// *************************************************************************** *
// *                                                                           *
// *                      Mentor Graphics Corporation                          *
// *                          All rights reserved                              *
// *                                                                           *
// *************************************************************************** *
// *                                                                           *
// * Description:         CANDB File                                           *
// * Generated at:        2019-08-28 11:46:03                                  *
// * System:              xMA19024                                             *
// * Variant:             LSPA                                                 *
// * Network:             PropulsionCAN                                        *
// *                                                                           *
// *************************************************************************** *
// *                                                                           *
// *             THIS CONFIGURATION MIGHT CONTAIN SOME ERRORS                  *
// *              IF THE INPUT MODEL WAS NOT PROPERLY FORMED!                  *
// *                    Do Not Use this File directly!                         *
// *                                                                           *
// *************************************************************************** *
VERSION "PropulsionCAN"

NS_ :

BS_:

BU_:  BECM DEM ECM EGSM ESM ETC IEM IGM ISGM MVBM MVCM MVEM OBC SRS TACM TCM VDDM VGM

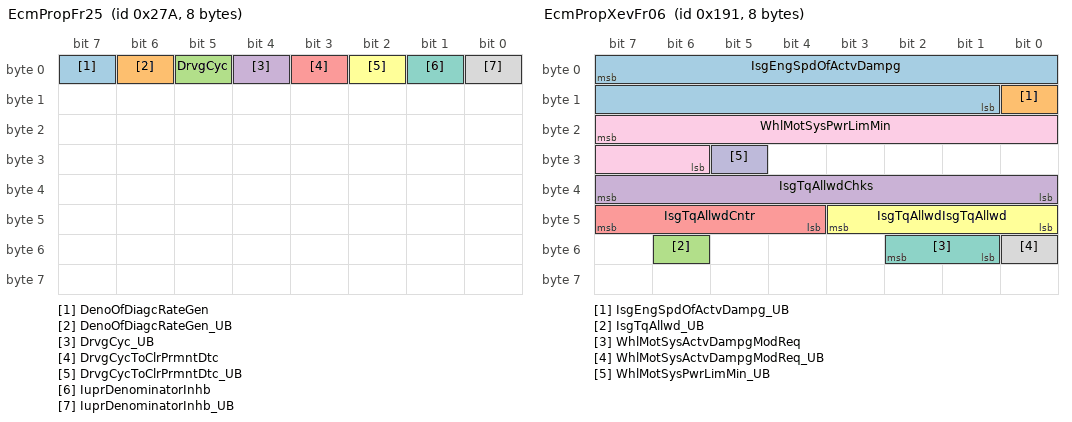
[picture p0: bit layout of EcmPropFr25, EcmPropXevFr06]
BO_ 634 EcmPropFr25: 8 ECM
 SG_ DenoOfDiagcRateGen : 7|1@0+ (1,0) [0|1] "" BECM,IEM,IGM,ISGM,MVBM,OBC
 SG_ DenoOfDiagcRateGen_UB : 6|1@0+ (1,0) [0|1] "" BECM,IEM,IGM,ISGM,MVBM,OBC
 SG_ DrvgCyc : 5|1@0+ (1,0) [0|1] "" BECM,IEM,IGM,ISGM,MVBM,MVCM,OBC,TCM
 SG_ DrvgCyc_UB : 4|1@0+ (1,0) [0|1] "" BECM,IEM,IGM,ISGM,MVBM,MVCM,OBC,TCM
 SG_ DrvgCycToClrPrmntDtc : 3|1@0+ (1,0) [0|1] "" BECM,IEM,IGM,ISGM,MVBM,OBC
 SG_ DrvgCycToClrPrmntDtc_UB : 2|1@0+ (1,0) [0|1] "" BECM,IEM,IGM,ISGM,MVBM,OBC
 SG_ IuprDenominatorInhb : 1|1@0+ (1,0) [0|1] "" BECM,IEM,IGM,ISGM,MVBM,OBC,TCM,VDDM
 SG_ IuprDenominatorInhb_UB : 0|1@0+ (1,0) [0|1] "" BECM,IEM,IGM,ISGM,MVBM,OBC,TCM,VDDM

BO_ 1312 EcmPropNMFr: 8 ECM
 SG_ PNC22_ECM : 22|1@0+ (1,0) [0|0] "" DEM
 SG_ PNC25_ECM : 25|1@0+ (1,0) [0|0] "" DEM
 SG_ PNC26_ECM : 26|1@0+ (1,0) [0|0] "" DEM
 SG_ PNC27_ECM : 27|1@0+ (1,0) [0|0] "" DEM
 SG_ PNC28_ECM : 28|1@0+ (1,0) [0|0] "" DEM
 SG_ PNC29_ECM : 29|1@0+ (1,0) [0|0] "" DEM
 SG_ PNC30_ECM : 30|1@0+ (1,0) [0|0] "" DEM
 SG_ PNC16_ECM : 16|1@0+ (1,0) [0|0] "" DEM
 SG_ PNC24_ECM : 24|1@0+ (1,0) [0|0] "" DEM
 SG_ PNC20_ECM : 20|1@0+ (1,0) [0|0] "" DEM
 SG_ PNC39_ECM : 39|1@0+ (1,0) [0|0] "" DEM
 SG_ PNC35_ECM : 35|1@0+ (1,0) [0|0] "" DEM
 SG_ NM_PNI_ECM : 14|1@0+ (1,0) [0|0] "" DEM
 SG_ NM_AW_ECM : 12|1@0+ (1,0) [0|0] "" DEM
 SG_ NM_CS_ECM : 11|1@0+ (1,0) [0|0] "" DEM
 SG_ NM_RMR_ECM : 8|1@0+ (1,0) [0|0] "" DEM
 SG_ NM_NodeID_ECM : 7|8@0+ (1,0) [0|0] "" DEM

BO_ 1347 EcmPropVFCVectorFr: 8 ECM
 SG_ VFCVectorECMBlockID : 1|2@0+ (1.0,0.0) [0.0|3.0] "Unitless" ETC
 SG_ VFCVectorECMVFCid0 : 2|1@0+ (1,0) [0|1] "" ETC
 SG_ VFCVectorECMVFCid1 : 3|1@0+ (1,0) [0|1] "" ETC
 SG_ VFCVectorECMVFCid10 : 12|1@0+ (1,0) [0|1] "" ETC
 SG_ VFCVectorECMVFCid11 : 13|1@0+ (1,0) [0|1] "" ETC
 SG_ VFCVectorECMVFCid12 : 14|1@0+ (1,0) [0|1] "" ETC
 SG_ VFCVectorECMVFCid13 : 15|1@0+ (1,0) [0|1] "" ETC
 SG_ VFCVectorECMVFCid14 : 16|1@0+ (1,0) [0|1] "" ETC
 SG_ VFCVectorECMVFCid15 : 17|1@0+ (1,0) [0|1] "" ETC
 SG_ VFCVectorECMVFCid16 : 18|1@0+ (1,0) [0|1] "" ETC
 SG_ VFCVectorECMVFCid17 : 19|1@0+ (1,0) [0|1] "" ETC
 SG_ VFCVectorECMVFCid18 : 20|1@0+ (1,0) [0|1] "" ETC
 SG_ VFCVectorECMVFCid19 : 21|1@0+ (1,0) [0|1] "" ETC
 SG_ VFCVectorECMVFCid2 : 4|1@0+ (1,0) [0|1] "" ETC
 SG_ VFCVectorECMVFCid20 : 22|1@0+ (1,0) [0|1] "" ETC
 SG_ VFCVectorECMVFCid21 : 23|1@0+ (1,0) [0|1] "" ETC
 SG_ VFCVectorECMVFCid22 : 24|1@0+ (1,0) [0|1] "" ETC
 SG_ VFCVectorECMVFCid23 : 25|1@0+ (1,0) [0|1] "" ETC
 SG_ VFCVectorECMVFCid24 : 26|1@0+ (1,0) [0|1] "" ETC
 SG_ VFCVectorECMVFCid25 : 27|1@0+ (1,0) [0|1] "" ETC
 SG_ VFCVectorECMVFCid26 : 28|1@0+ (1,0) [0|1] "" ETC
 SG_ VFCVectorECMVFCid27 : 29|1@0+ (1,0) [0|1] "" ETC
 SG_ VFCVectorECMVFCid28 : 30|1@0+ (1,0) [0|1] "" ETC
 SG_ VFCVectorECMVFCid29 : 31|1@0+ (1,0) [0|1] "" ETC
 SG_ VFCVectorECMVFCid3 : 5|1@0+ (1,0) [0|1] "" ETC
 SG_ VFCVectorECMVFCid30 : 32|1@0+ (1,0) [0|1] "" ETC
 SG_ VFCVectorECMVFCid31 : 33|1@0+ (1,0) [0|1] "" ETC
 SG_ VFCVectorECMVFCid32 : 34|1@0+ (1,0) [0|1] "" ETC
 SG_ VFCVectorECMVFCid33 : 35|1@0+ (1,0) [0|1] "" ETC
 SG_ VFCVectorECMVFCid34 : 36|1@0+ (1,0) [0|1] "" ETC
 SG_ VFCVectorECMVFCid35 : 37|1@0+ (1,0) [0|1] "" ETC
 SG_ VFCVectorECMVFCid36 : 38|1@0+ (1,0) [0|1] "" ETC
 SG_ VFCVectorECMVFCid37 : 39|1@0+ (1,0) [0|1] "" ETC
 SG_ VFCVectorECMVFCid38 : 40|1@0+ (1,0) [0|1] "" ETC
 SG_ VFCVectorECMVFCid39 : 41|1@0+ (1,0) [0|1] "" ETC
 SG_ VFCVectorECMVFCid4 : 6|1@0+ (1,0) [0|1] "" ETC
 SG_ VFCVectorECMVFCid40 : 42|1@0+ (1,0) [0|1] "" ETC
 SG_ VFCVectorECMVFCid41 : 43|1@0+ (1,0) [0|1] "" ETC
 SG_ VFCVectorECMVFCid42 : 44|1@0+ (1,0) [0|1] "" ETC
 SG_ VFCVectorECMVFCid43 : 45|1@0+ (1,0) [0|1] "" ETC
 SG_ VFCVectorECMVFCid44 : 46|1@0+ (1,0) [0|1] "" ETC
 SG_ VFCVectorECMVFCid45 : 47|1@0+ (1,0) [0|1] "" ETC
 SG_ VFCVectorECMVFCid46 : 48|1@0+ (1,0) [0|1] "" ETC
 SG_ VFCVectorECMVFCid47 : 49|1@0+ (1,0) [0|1] "" ETC
 SG_ VFCVectorECMVFCid48 : 50|1@0+ (1,0) [0|1] "" ETC
 SG_ VFCVectorECMVFCid49 : 51|1@0+ (1,0) [0|1] "" ETC
 SG_ VFCVectorECMVFCid5 : 7|1@0+ (1,0) [0|1] "" ETC
 SG_ VFCVectorECMVFCid50 : 52|1@0+ (1,0) [0|1] "" ETC
 SG_ VFCVectorECMVFCid51 : 53|1@0+ (1,0) [0|1] "" ETC
 SG_ VFCVectorECMVFCid52 : 54|1@0+ (1,0) [0|1] "" ETC
 SG_ VFCVectorECMVFCid53 : 55|1@0+ (1,0) [0|1] "" ETC
 SG_ VFCVectorECMVFCid54 : 56|1@0+ (1,0) [0|1] "" ETC
 SG_ VFCVectorECMVFCid55 : 57|1@0+ (1,0) [0|1] "" ETC
 SG_ VFCVectorECMVFCid56 : 58|1@0+ (1,0) [0|1] "" ETC
 SG_ VFCVectorECMVFCid57 : 59|1@0+ (1,0) [0|1] "" ETC
 SG_ VFCVectorECMVFCid58 : 60|1@0+ (1,0) [0|1] "" ETC
 SG_ VFCVectorECMVFCid59 : 61|1@0+ (1,0) [0|1] "" ETC
 SG_ VFCVectorECMVFCid6 : 8|1@0+ (1,0) [0|1] "" ETC
 SG_ VFCVectorECMVFCid60 : 62|1@0+ (1,0) [0|1] "" ETC
 SG_ VFCVectorECMVFCid61 : 63|1@0+ (1,0) [0|1] "" ETC
 SG_ VFCVectorECMVFCid7 : 9|1@0+ (1,0) [0|1] "" ETC
 SG_ VFCVectorECMVFCid8 : 10|1@0+ (1,0) [0|1] "" ETC
 SG_ VFCVectorECMVFCid9 : 11|1@0+ (1,0) [0|1] "" ETC

BO_ 401 EcmPropXevFr06: 8 ECM
 SG_ IsgEngSpdOfActvDampg : 7|15@0+ (0.5,0.0) [0.0|16383.5] "rpm" IGM
 SG_ IsgEngSpdOfActvDampg_UB : 8|1@0+ (1,0) [0|1] "" IGM
 SG_ IsgTqAllwd_UB : 54|1@0+ (1,0) [0|1] "" IGM
 SG_ IsgTqAllwdChks : 39|8@0+ (1.0,0.0) [0.0|255.0] "Unitless" IGM
 SG_ IsgTqAllwdCntr : 47|4@0+ (1.0,0.0) [0.0|15.0] "Unitless" IGM
 SG_ IsgTqAllwdIsgTqAllwd : 43|4@0+ (1.0,0.0) [0.0|15.0] "Unitless" IGM
 SG_ WhlMotSysActvDampgModReq : 50|2@0+ (1,0) [0|3] "" IEM
 SG_ WhlMotSysActvDampgModReq_UB : 48|1@0+ (1,0) [0|1] "" IEM
 SG_ WhlMotSysPwrLimMin : 23|10@0+ (0.5,-511.0) [-511.0|0.0] "kW" IEM
 SG_ WhlMotSysPwrLimMin_UB : 29|1@0+ (1,0) [0|1] "" IEM

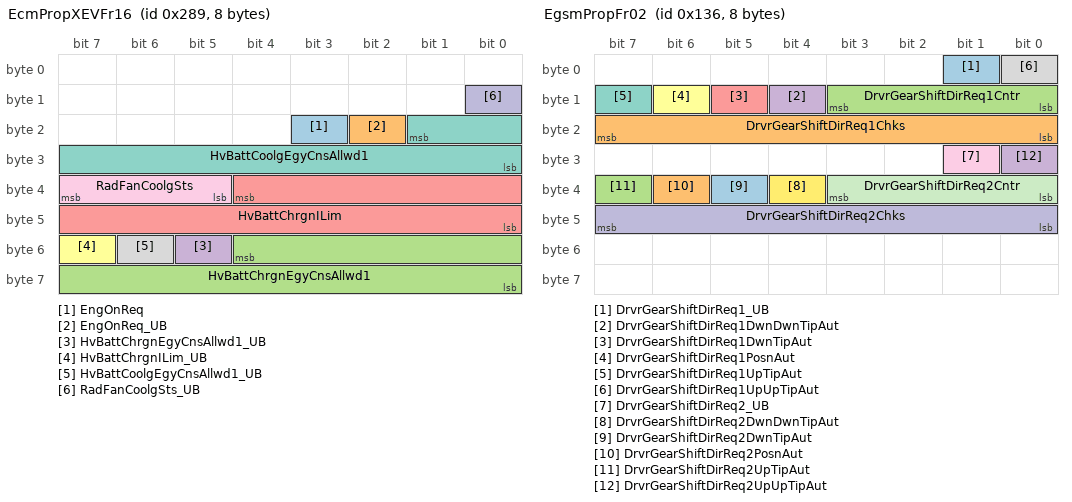
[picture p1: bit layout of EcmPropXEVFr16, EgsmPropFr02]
BO_ 649 EcmPropXEVFr16: 8 ECM
 SG_ EngOnReq : 19|1@0+ (1,0) [0|1] "" BECM
 SG_ EngOnReq_UB : 18|1@0+ (1,0) [0|1] "" BECM
 SG_ HvBattChrgnEgyCnsAllwd1 : 52|13@0+ (20.0,0.0) [0.0|163820.0] "Wh" BECM
 SG_ HvBattChrgnEgyCnsAllwd1_UB : 53|1@0+ (1,0) [0|1] "" BECM
 SG_ HvBattChrgnILim : 36|13@0+ (0.1,0.0) [0.0|819.1] "A" OBC
 SG_ HvBattChrgnILim_UB : 55|1@0+ (1,0) [0|1] "" OBC
 SG_ HvBattCoolgEgyCnsAllwd1 : 17|10@0+ (20.0,0.0) [0.0|20460.0] "Wh" BECM
 SG_ HvBattCoolgEgyCnsAllwd1_UB : 54|1@0+ (1,0) [0|1] "" BECM
 SG_ RadFanCoolgSts : 39|3@0+ (1.0,0.0) [0.0|7.0] "Unitless" BECM
 SG_ RadFanCoolgSts_UB : 8|1@0+ (1,0) [0|1] "" BECM

BO_ 1584 EcmToVddmPropDiagResFrame: 8 ECM
 SG_ EcmToVddmPropDiagResNpdu : 7|64@0+ (1,0) [0|0] "" VDDM

BO_ 2024 EcmToVgmJ1979OBDPropCanResFrame11: 8 ECM
 SG_ EcmToVgmJ1979OBDPropCanResNpdu11 : 7|64@0+ (1,0) [0|0] "" VGM

BO_ 309 EgsmPropFr01: 8 EGSM
 SG_ DrvrGearShiftManReq_UB : 7|1@0+ (1,0) [0|1] "" ECM,TCM
 SG_ DrvrGearShiftManReqDwnDwnTipReq : 0|1@0+ (1,0) [0|1] "" ECM,TCM
 SG_ DrvrGearShiftManReqDwnTipReq : 1|1@0+ (1,0) [0|1] "" ECM,TCM
 SG_ DrvrGearShiftManReqSteerWhlDwnReq1 : 2|1@0+ (1,0) [0|1] "" ECM,TCM
 SG_ DrvrGearShiftManReqSteerWhlUpReq : 3|1@0+ (1,0) [0|1] "" ECM,TCM
 SG_ DrvrGearShiftManReqTipReq1 : 4|1@0+ (1,0) [0|1] "" ECM,TCM
 SG_ DrvrGearShiftManReqUpTipReq1 : 5|1@0+ (1,0) [0|1] "" ECM,TCM
 SG_ DrvrGearShiftManReqUpUpTipReq : 6|1@0+ (1,0) [0|1] "" ECM,TCM
 SG_ DrvrGearShiftParkReq_UB : 15|1@0+ (1,0) [0|1] "" ECM,VDDM
 SG_ DrvrGearShiftParkReq1 : 14|1@0+ (1,0) [0|1] "" ECM,VDDM
 SG_ DrvrGearShiftParkReqChks : 23|8@0+ (1.0,0.0) [0.0|255.0] "Unitless" ECM,VDDM
 SG_ DrvrGearShiftParkReqCntr : 11|4@0+ (1.0,0.0) [0.0|15.0] "Unitless" ECM,VDDM
 SG_ DrvrGearShiftParkReqSts : 13|2@0+ (1,0) [0|3] "" ECM,VDDM
 SG_ GearLock : 28|1@0+ (1,0) [0|1] "" ECM
 SG_ GearLock_UB : 29|1@0+ (1,0) [0|1] "" ECM
 SG_ GearShiftUnitSts : 26|3@0+ (1,0) [0|7] "" ECM,VDDM
 SG_ GearShiftUnitSts_UB : 27|1@0+ (1,0) [0|1] "" ECM,VDDM

BO_ 310 EgsmPropFr02: 8 EGSM
 SG_ DrvrGearShiftDirReq1_UB : 1|1@0+ (1,0) [0|1] "" ECM,VDDM
 SG_ DrvrGearShiftDirReq1Chks : 23|8@0+ (1.0,0.0) [0.0|255.0] "Unitless" ECM,VDDM
 SG_ DrvrGearShiftDirReq1Cntr : 11|4@0+ (1.0,0.0) [0.0|15.0] "Unitless" ECM,VDDM
 SG_ DrvrGearShiftDirReq1DwnDwnTipAut : 12|1@0+ (1,0) [0|1] "" ECM,VDDM
 SG_ DrvrGearShiftDirReq1DwnTipAut : 13|1@0+ (1,0) [0|1] "" ECM,VDDM
 SG_ DrvrGearShiftDirReq1PosnAut : 14|1@0+ (1,0) [0|1] "" ECM,VDDM
 SG_ DrvrGearShiftDirReq1UpTipAut : 15|1@0+ (1,0) [0|1] "" ECM,VDDM
 SG_ DrvrGearShiftDirReq1UpUpTipAut : 0|1@0+ (1,0) [0|1] "" ECM,VDDM
 SG_ DrvrGearShiftDirReq2_UB : 25|1@0+ (1,0) [0|1] "" ECM,VDDM
 SG_ DrvrGearShiftDirReq2Chks : 47|8@0+ (1.0,0.0) [0.0|255.0] "Unitless" ECM,VDDM
 SG_ DrvrGearShiftDirReq2Cntr : 35|4@0+ (1.0,0.0) [0.0|15.0] "Unitless" ECM,VDDM
 SG_ DrvrGearShiftDirReq2DwnDwnTipAut : 36|1@0+ (1,0) [0|1] "" ECM,VDDM
 SG_ DrvrGearShiftDirReq2DwnTipAut : 37|1@0+ (1,0) [0|1] "" ECM,VDDM
 SG_ DrvrGearShiftDirReq2PosnAut : 38|1@0+ (1,0) [0|1] "" ECM,VDDM
 SG_ DrvrGearShiftDirReq2UpTipAut : 39|1@0+ (1,0) [0|1] "" ECM,VDDM
 SG_ DrvrGearShiftDirReq2UpUpTipAut : 24|1@0+ (1,0) [0|1] "" ECM,VDDM

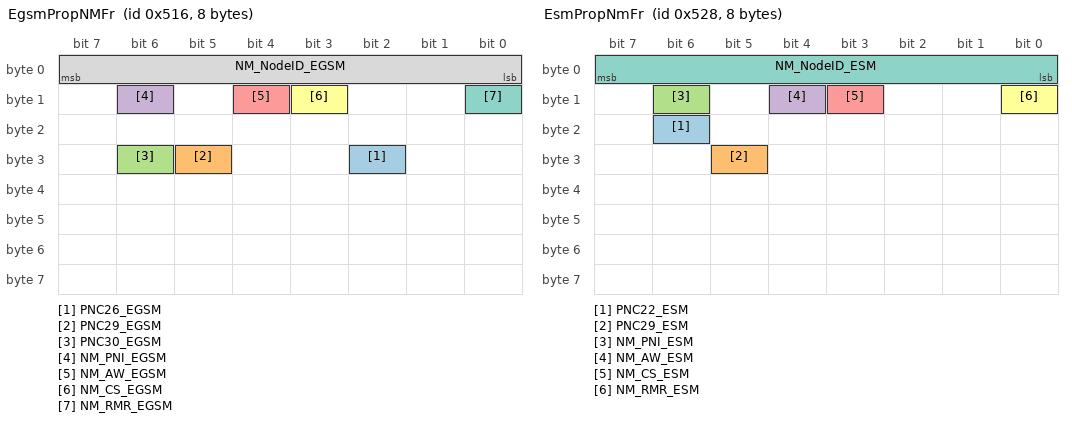
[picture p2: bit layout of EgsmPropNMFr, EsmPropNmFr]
BO_ 1302 EgsmPropNMFr: 8 EGSM
 SG_ PNC26_EGSM : 26|1@0+ (1,0) [0|0] "" ECM
 SG_ PNC29_EGSM : 29|1@0+ (1,0) [0|0] "" ECM
 SG_ PNC30_EGSM : 30|1@0+ (1,0) [0|0] "" ECM
 SG_ NM_PNI_EGSM : 14|1@0+ (1,0) [0|0] "" ECM
 SG_ NM_AW_EGSM : 12|1@0+ (1,0) [0|0] "" ECM
 SG_ NM_CS_EGSM : 11|1@0+ (1,0) [0|0] "" ECM
 SG_ NM_RMR_EGSM : 8|1@0+ (1,0) [0|0] "" ECM
 SG_ NM_NodeID_EGSM : 7|8@0+ (1,0) [0|0] "" ECM

BO_ 1349 EgsmPropVFCVectorFr: 8 EGSM
 SG_ VFCVectorEGSMBlockID : 1|2@0+ (1.0,0.0) [0.0|3.0] "Unitless" ETC
 SG_ VFCVectorEGSMVFCid0 : 2|1@0+ (1,0) [0|1] "" ETC
 SG_ VFCVectorEGSMVFCid1 : 3|1@0+ (1,0) [0|1] "" ETC
 SG_ VFCVectorEGSMVFCid10 : 12|1@0+ (1,0) [0|1] "" ETC
 SG_ VFCVectorEGSMVFCid11 : 13|1@0+ (1,0) [0|1] "" ETC
 SG_ VFCVectorEGSMVFCid12 : 14|1@0+ (1,0) [0|1] "" ETC
 SG_ VFCVectorEGSMVFCid13 : 15|1@0+ (1,0) [0|1] "" ETC
 SG_ VFCVectorEGSMVFCid14 : 16|1@0+ (1,0) [0|1] "" ETC
 SG_ VFCVectorEGSMVFCid15 : 17|1@0+ (1,0) [0|1] "" ETC
 SG_ VFCVectorEGSMVFCid16 : 18|1@0+ (1,0) [0|1] "" ETC
 SG_ VFCVectorEGSMVFCid17 : 19|1@0+ (1,0) [0|1] "" ETC
 SG_ VFCVectorEGSMVFCid18 : 20|1@0+ (1,0) [0|1] "" ETC
 SG_ VFCVectorEGSMVFCid19 : 21|1@0+ (1,0) [0|1] "" ETC
 SG_ VFCVectorEGSMVFCid2 : 4|1@0+ (1,0) [0|1] "" ETC
 SG_ VFCVectorEGSMVFCid20 : 22|1@0+ (1,0) [0|1] "" ETC
 SG_ VFCVectorEGSMVFCid21 : 23|1@0+ (1,0) [0|1] "" ETC
 SG_ VFCVectorEGSMVFCid22 : 24|1@0+ (1,0) [0|1] "" ETC
 SG_ VFCVectorEGSMVFCid23 : 25|1@0+ (1,0) [0|1] "" ETC
 SG_ VFCVectorEGSMVFCid24 : 26|1@0+ (1,0) [0|1] "" ETC
 SG_ VFCVectorEGSMVFCid25 : 27|1@0+ (1,0) [0|1] "" ETC
 SG_ VFCVectorEGSMVFCid26 : 28|1@0+ (1,0) [0|1] "" ETC
 SG_ VFCVectorEGSMVFCid27 : 29|1@0+ (1,0) [0|1] "" ETC
 SG_ VFCVectorEGSMVFCid28 : 30|1@0+ (1,0) [0|1] "" ETC
 SG_ VFCVectorEGSMVFCid29 : 31|1@0+ (1,0) [0|1] "" ETC
 SG_ VFCVectorEGSMVFCid3 : 5|1@0+ (1,0) [0|1] "" ETC
 SG_ VFCVectorEGSMVFCid30 : 32|1@0+ (1,0) [0|1] "" ETC
 SG_ VFCVectorEGSMVFCid31 : 33|1@0+ (1,0) [0|1] "" ETC
 SG_ VFCVectorEGSMVFCid32 : 34|1@0+ (1,0) [0|1] "" ETC
 SG_ VFCVectorEGSMVFCid33 : 35|1@0+ (1,0) [0|1] "" ETC
 SG_ VFCVectorEGSMVFCid34 : 36|1@0+ (1,0) [0|1] "" ETC
 SG_ VFCVectorEGSMVFCid35 : 37|1@0+ (1,0) [0|1] "" ETC
 SG_ VFCVectorEGSMVFCid36 : 38|1@0+ (1,0) [0|1] "" ETC
 SG_ VFCVectorEGSMVFCid37 : 39|1@0+ (1,0) [0|1] "" ETC
 SG_ VFCVectorEGSMVFCid38 : 40|1@0+ (1,0) [0|1] "" ETC
 SG_ VFCVectorEGSMVFCid39 : 41|1@0+ (1,0) [0|1] "" ETC
 SG_ VFCVectorEGSMVFCid4 : 6|1@0+ (1,0) [0|1] "" ETC
 SG_ VFCVectorEGSMVFCid40 : 42|1@0+ (1,0) [0|1] "" ETC
 SG_ VFCVectorEGSMVFCid41 : 43|1@0+ (1,0) [0|1] "" ETC
 SG_ VFCVectorEGSMVFCid42 : 44|1@0+ (1,0) [0|1] "" ETC
 SG_ VFCVectorEGSMVFCid43 : 45|1@0+ (1,0) [0|1] "" ETC
 SG_ VFCVectorEGSMVFCid44 : 46|1@0+ (1,0) [0|1] "" ETC
 SG_ VFCVectorEGSMVFCid45 : 47|1@0+ (1,0) [0|1] "" ETC
 SG_ VFCVectorEGSMVFCid46 : 48|1@0+ (1,0) [0|1] "" ETC
 SG_ VFCVectorEGSMVFCid47 : 49|1@0+ (1,0) [0|1] "" ETC
 SG_ VFCVectorEGSMVFCid48 : 50|1@0+ (1,0) [0|1] "" ETC
 SG_ VFCVectorEGSMVFCid49 : 51|1@0+ (1,0) [0|1] "" ETC
 SG_ VFCVectorEGSMVFCid5 : 7|1@0+ (1,0) [0|1] "" ETC
 SG_ VFCVectorEGSMVFCid50 : 52|1@0+ (1,0) [0|1] "" ETC
 SG_ VFCVectorEGSMVFCid51 : 53|1@0+ (1,0) [0|1] "" ETC
 SG_ VFCVectorEGSMVFCid52 : 54|1@0+ (1,0) [0|1] "" ETC
 SG_ VFCVectorEGSMVFCid53 : 55|1@0+ (1,0) [0|1] "" ETC
 SG_ VFCVectorEGSMVFCid54 : 56|1@0+ (1,0) [0|1] "" ETC
 SG_ VFCVectorEGSMVFCid55 : 57|1@0+ (1,0) [0|1] "" ETC
 SG_ VFCVectorEGSMVFCid56 : 58|1@0+ (1,0) [0|1] "" ETC
 SG_ VFCVectorEGSMVFCid57 : 59|1@0+ (1,0) [0|1] "" ETC
 SG_ VFCVectorEGSMVFCid58 : 60|1@0+ (1,0) [0|1] "" ETC
 SG_ VFCVectorEGSMVFCid59 : 61|1@0+ (1,0) [0|1] "" ETC
 SG_ VFCVectorEGSMVFCid6 : 8|1@0+ (1,0) [0|1] "" ETC
 SG_ VFCVectorEGSMVFCid60 : 62|1@0+ (1,0) [0|1] "" ETC
 SG_ VFCVectorEGSMVFCid61 : 63|1@0+ (1,0) [0|1] "" ETC
 SG_ VFCVectorEGSMVFCid7 : 9|1@0+ (1,0) [0|1] "" ETC
 SG_ VFCVectorEGSMVFCid8 : 10|1@0+ (1,0) [0|1] "" ETC
 SG_ VFCVectorEGSMVFCid9 : 11|1@0+ (1,0) [0|1] "" ETC

BO_ 1587 EgsmToVddmPropDiagResFrame: 8 EGSM
 SG_ EgsmToVddmPropDiagResNpdu : 7|64@0+ (1,0) [0|0] "" VDDM

BO_ 801 EsmPropFr01: 4 ESM
 SG_ ComLostExtrSoundFront : 7|1@0+ (1,0) [0|1] "" VDDM
 SG_ ComLostExtrSoundFront_UB : 15|1@0+ (1,0) [0|1] "" VDDM

BO_ 1320 EsmPropNmFr: 8 ESM
 SG_ PNC22_ESM : 22|1@0+ (1,0) [0|0] "" EGSM
 SG_ PNC29_ESM : 29|1@0+ (1,0) [0|0] "" EGSM
 SG_ NM_PNI_ESM : 14|1@0+ (1,0) [0|0] "" EGSM
 SG_ NM_AW_ESM : 12|1@0+ (1,0) [0|0] "" EGSM
 SG_ NM_CS_ESM : 11|1@0+ (1,0) [0|0] "" EGSM
 SG_ NM_RMR_ESM : 8|1@0+ (1,0) [0|0] "" EGSM
 SG_ NM_NodeID_ESM : 7|8@0+ (1,0) [0|0] "" EGSM

BO_ 1594 EsmToVddmPropDiagResFrame: 8 ESM
 SG_ EsmToVddmPropDiagResNpdu : 7|64@0+ (1,0) [0|0] "" VDDM

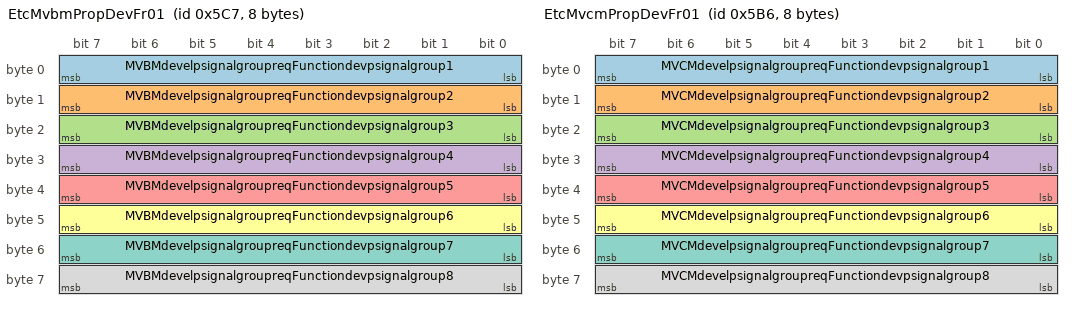
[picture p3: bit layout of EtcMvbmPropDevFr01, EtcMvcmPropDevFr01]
BO_ 1479 EtcMvbmPropDevFr01: 8 ETC
 SG_ MVBMdevelpsignalgroupreqFunctiondevpsignalgroup1 : 7|8@0+ (1.0,0.0) [0.0|255.0] "Unitless" MVBM
 SG_ MVBMdevelpsignalgroupreqFunctiondevpsignalgroup2 : 15|8@0+ (1.0,0.0) [0.0|255.0] "Unitless" MVBM
 SG_ MVBMdevelpsignalgroupreqFunctiondevpsignalgroup3 : 23|8@0+ (1.0,0.0) [0.0|255.0] "Unitless" MVBM
 SG_ MVBMdevelpsignalgroupreqFunctiondevpsignalgroup4 : 31|8@0+ (1.0,0.0) [0.0|255.0] "Unitless" MVBM
 SG_ MVBMdevelpsignalgroupreqFunctiondevpsignalgroup5 : 39|8@0+ (1.0,0.0) [0.0|255.0] "Unitless" MVBM
 SG_ MVBMdevelpsignalgroupreqFunctiondevpsignalgroup6 : 47|8@0+ (1.0,0.0) [0.0|255.0] "Unitless" MVBM
 SG_ MVBMdevelpsignalgroupreqFunctiondevpsignalgroup7 : 55|8@0+ (1.0,0.0) [0.0|255.0] "Unitless" MVBM
 SG_ MVBMdevelpsignalgroupreqFunctiondevpsignalgroup8 : 63|8@0+ (1.0,0.0) [0.0|255.0] "Unitless" MVBM

BO_ 1462 EtcMvcmPropDevFr01: 8 ETC
 SG_ MVCMdevelpsignalgroupreqFunctiondevpsignalgroup1 : 7|8@0+ (1.0,0.0) [0.0|255.0] "Unitless" MVCM
 SG_ MVCMdevelpsignalgroupreqFunctiondevpsignalgroup2 : 15|8@0+ (1.0,0.0) [0.0|255.0] "Unitless" MVCM
 SG_ MVCMdevelpsignalgroupreqFunctiondevpsignalgroup3 : 23|8@0+ (1.0,0.0) [0.0|255.0] "Unitless" MVCM
 SG_ MVCMdevelpsignalgroupreqFunctiondevpsignalgroup4 : 31|8@0+ (1.0,0.0) [0.0|255.0] "Unitless" MVCM
 SG_ MVCMdevelpsignalgroupreqFunctiondevpsignalgroup5 : 39|8@0+ (1.0,0.0) [0.0|255.0] "Unitless" MVCM
 SG_ MVCMdevelpsignalgroupreqFunctiondevpsignalgroup6 : 47|8@0+ (1.0,0.0) [0.0|255.0] "Unitless" MVCM
 SG_ MVCMdevelpsignalgroupreqFunctiondevpsignalgroup7 : 55|8@0+ (1.0,0.0) [0.0|255.0] "Unitless" MVCM
 SG_ MVCMdevelpsignalgroupreqFunctiondevpsignalgroup8 : 63|8@0+ (1.0,0.0) [0.0|255.0] "Unitless" MVCM

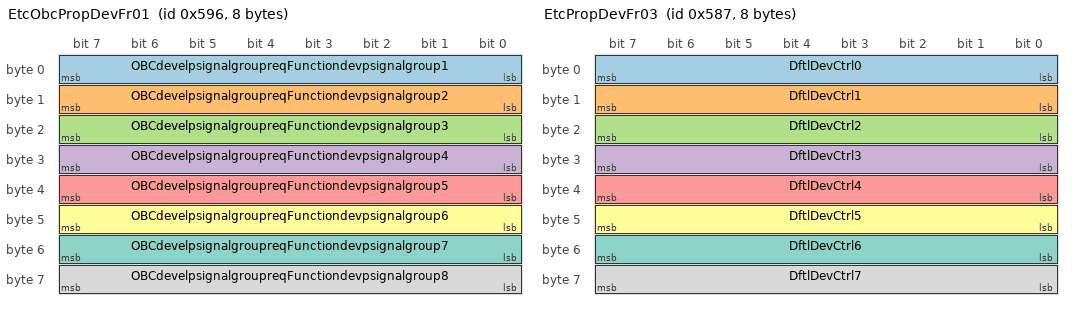
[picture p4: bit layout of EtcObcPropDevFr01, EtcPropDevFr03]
BO_ 1430 EtcObcPropDevFr01: 8 ETC
 SG_ OBCdevelpsignalgroupreqFunctiondevpsignalgroup1 : 7|8@0+ (1.0,0.0) [0.0|255.0] "Unitless" OBC
 SG_ OBCdevelpsignalgroupreqFunctiondevpsignalgroup2 : 15|8@0+ (1.0,0.0) [0.0|255.0] "Unitless" OBC
 SG_ OBCdevelpsignalgroupreqFunctiondevpsignalgroup3 : 23|8@0+ (1.0,0.0) [0.0|255.0] "Unitless" OBC
 SG_ OBCdevelpsignalgroupreqFunctiondevpsignalgroup4 : 31|8@0+ (1.0,0.0) [0.0|255.0] "Unitless" OBC
 SG_ OBCdevelpsignalgroupreqFunctiondevpsignalgroup5 : 39|8@0+ (1.0,0.0) [0.0|255.0] "Unitless" OBC
 SG_ OBCdevelpsignalgroupreqFunctiondevpsignalgroup6 : 47|8@0+ (1.0,0.0) [0.0|255.0] "Unitless" OBC
 SG_ OBCdevelpsignalgroupreqFunctiondevpsignalgroup7 : 55|8@0+ (1.0,0.0) [0.0|255.0] "Unitless" OBC
 SG_ OBCdevelpsignalgroupreqFunctiondevpsignalgroup8 : 63|8@0+ (1.0,0.0) [0.0|255.0] "Unitless" OBC

BO_ 1415 EtcPropDevFr03: 8 ETC
 SG_ DftlDevCtrl0 : 7|8@0+ (1.0,0.0) [0.0|255.0] "Unitless" DEM
 SG_ DftlDevCtrl1 : 15|8@0+ (1.0,0.0) [0.0|255.0] "Unitless" DEM
 SG_ DftlDevCtrl2 : 23|8@0+ (1.0,0.0) [0.0|255.0] "Unitless" DEM
 SG_ DftlDevCtrl3 : 31|8@0+ (1.0,0.0) [0.0|255.0] "Unitless" DEM
 SG_ DftlDevCtrl4 : 39|8@0+ (1.0,0.0) [0.0|255.0] "Unitless" DEM
 SG_ DftlDevCtrl5 : 47|8@0+ (1.0,0.0) [0.0|255.0] "Unitless" DEM
 SG_ DftlDevCtrl6 : 55|8@0+ (1.0,0.0) [0.0|255.0] "Unitless" DEM
 SG_ DftlDevCtrl7 : 63|8@0+ (1.0,0.0) [0.0|255.0] "Unitless" DEM

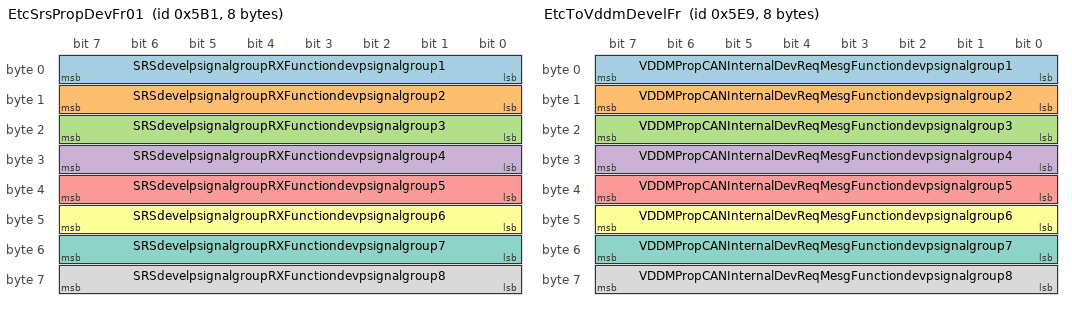
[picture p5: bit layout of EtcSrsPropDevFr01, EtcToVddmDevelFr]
BO_ 1457 EtcSrsPropDevFr01: 8 ETC
 SG_ SRSdevelpsignalgroupRXFunctiondevpsignalgroup1 : 7|8@0+ (1.0,0.0) [0.0|255.0] "Unitless" SRS
 SG_ SRSdevelpsignalgroupRXFunctiondevpsignalgroup2 : 15|8@0+ (1.0,0.0) [0.0|255.0] "Unitless" SRS
 SG_ SRSdevelpsignalgroupRXFunctiondevpsignalgroup3 : 23|8@0+ (1.0,0.0) [0.0|255.0] "Unitless" SRS
 SG_ SRSdevelpsignalgroupRXFunctiondevpsignalgroup4 : 31|8@0+ (1.0,0.0) [0.0|255.0] "Unitless" SRS
 SG_ SRSdevelpsignalgroupRXFunctiondevpsignalgroup5 : 39|8@0+ (1.0,0.0) [0.0|255.0] "Unitless" SRS
 SG_ SRSdevelpsignalgroupRXFunctiondevpsignalgroup6 : 47|8@0+ (1.0,0.0) [0.0|255.0] "Unitless" SRS
 SG_ SRSdevelpsignalgroupRXFunctiondevpsignalgroup7 : 55|8@0+ (1.0,0.0) [0.0|255.0] "Unitless" SRS
 SG_ SRSdevelpsignalgroupRXFunctiondevpsignalgroup8 : 63|8@0+ (1.0,0.0) [0.0|255.0] "Unitless" SRS

BO_ 1410 EtctoCddXCPFr01: 8 ETC

BO_ 1448 ETCtoDEMXCPFr01: 8 ETC

BO_ 1447 ETCtoDEMXCPFr02: 8 ETC

BO_ 1449 ETCtoDEMXCPFr03: 8 ETC

BO_ 1450 ETCtoDEMXCPFr04: 8 ETC

BO_ 1451 ETCtoDEMXCPFr05: 8 ETC

BO_ 1452 ETCtoDEMXCPFr06: 8 ETC

BO_ 1412 EtctoEcmXCPFr01: 8 ETC

BO_ 1418 EtctoIgsmXCPFr01: 8 ETC

BO_ 1424 ETCtoTACMXcpFr01: 8 ETC

BO_ 1428 ETCtoTACMXcpFr02: 8 ETC

BO_ 1513 EtcToVddmDevelFr: 8 ETC
 SG_ VDDMPropCANInternalDevReqMesgFunctiondevpsignalgroup1 : 7|8@0+ (1.0,0.0) [0.0|255.0] "Unitless" VDDM
 SG_ VDDMPropCANInternalDevReqMesgFunctiondevpsignalgroup2 : 15|8@0+ (1.0,0.0) [0.0|255.0] "Unitless" VDDM
 SG_ VDDMPropCANInternalDevReqMesgFunctiondevpsignalgroup3 : 23|8@0+ (1.0,0.0) [0.0|255.0] "Unitless" VDDM
 SG_ VDDMPropCANInternalDevReqMesgFunctiondevpsignalgroup4 : 31|8@0+ (1.0,0.0) [0.0|255.0] "Unitless" VDDM
 SG_ VDDMPropCANInternalDevReqMesgFunctiondevpsignalgroup5 : 39|8@0+ (1.0,0.0) [0.0|255.0] "Unitless" VDDM
 SG_ VDDMPropCANInternalDevReqMesgFunctiondevpsignalgroup6 : 47|8@0+ (1.0,0.0) [0.0|255.0] "Unitless" VDDM
 SG_ VDDMPropCANInternalDevReqMesgFunctiondevpsignalgroup7 : 55|8@0+ (1.0,0.0) [0.0|255.0] "Unitless" VDDM
 SG_ VDDMPropCANInternalDevReqMesgFunctiondevpsignalgroup8 : 63|8@0+ (1.0,0.0) [0.0|255.0] "Unitless" VDDM

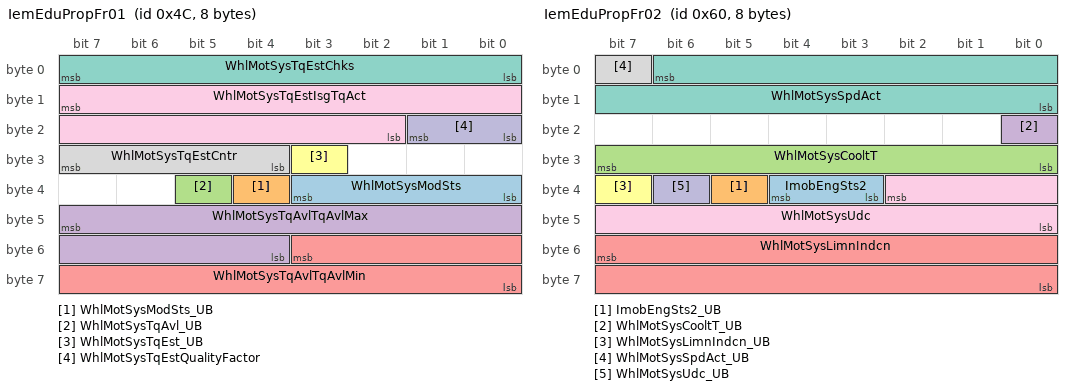
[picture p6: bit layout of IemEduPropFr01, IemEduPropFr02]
BO_ 76 IemEduPropFr01: 8 IEM
 SG_ WhlMotSysModSts : 35|4@0+ (1,0) [0|15] "" BECM,ECM,VDDM
 SG_ WhlMotSysModSts_UB : 36|1@0+ (1,0) [0|1] "" BECM,ECM,VDDM
 SG_ WhlMotSysTqAvl_UB : 37|1@0+ (1,0) [0|1] "" ECM
 SG_ WhlMotSysTqAvlTqAvlMax : 47|12@0+ (4.0,-8188.0) [-8188.0|8192.0] "NewtonMeter" ECM
 SG_ WhlMotSysTqAvlTqAvlMin : 51|12@0+ (4.0,-8188.0) [-8188.0|8192.0] "NewtonMeter" ECM
 SG_ WhlMotSysTqEst_UB : 27|1@0+ (1,0) [0|1] "" ECM,VDDM
 SG_ WhlMotSysTqEstChks : 7|8@0+ (1.0,0.0) [0.0|255.0] "Unitless" ECM,VDDM
 SG_ WhlMotSysTqEstCntr : 31|4@0+ (1.0,0.0) [0.0|15.0] "Unitless" ECM,VDDM
 SG_ WhlMotSysTqEstIsgTqAct : 15|14@0+ (1.0,-8188.0) [-8188.0|8192.0] "NewtonMeter" ECM,VDDM
 SG_ WhlMotSysTqEstQualityFactor : 17|2@0+ (1,0) [0|3] "" ECM,VDDM

BO_ 96 IemEduPropFr02: 8 IEM
 SG_ ImobEngSts2 : 36|2@0+ (1,0) [0|3] "" VDDM
 SG_ ImobEngSts2_UB : 37|1@0+ (1,0) [0|1] "" VDDM
 SG_ WhlMotSysCooltT : 31|8@0+ (1.0,-40.0) [-40.0|215.0] "degC" ECM,VDDM
 SG_ WhlMotSysCooltT_UB : 16|1@0+ (1,0) [0|1] "" ECM,VDDM
 SG_ WhlMotSysLimnIndcn : 55|16@0+ (1.0,0.0) [0.0|65535.0] "Unitless" ECM,VDDM
 SG_ WhlMotSysLimnIndcn_UB : 39|1@0+ (1,0) [0|1] "" ECM,VDDM
 SG_ WhlMotSysSpdAct : 6|15@0- (1.0,0.0) [-16384.0|16383.0] "rpm" ECM,VDDM
 SG_ WhlMotSysSpdAct_UB : 7|1@0+ (1,0) [0|1] "" ECM,VDDM
 SG_ WhlMotSysUdc : 34|11@0+ (0.25,0.0) [0.0|511.0] "Volt" ECM,VDDM
 SG_ WhlMotSysUdc_UB : 38|1@0+ (1,0) [0|1] "" ECM,VDDM

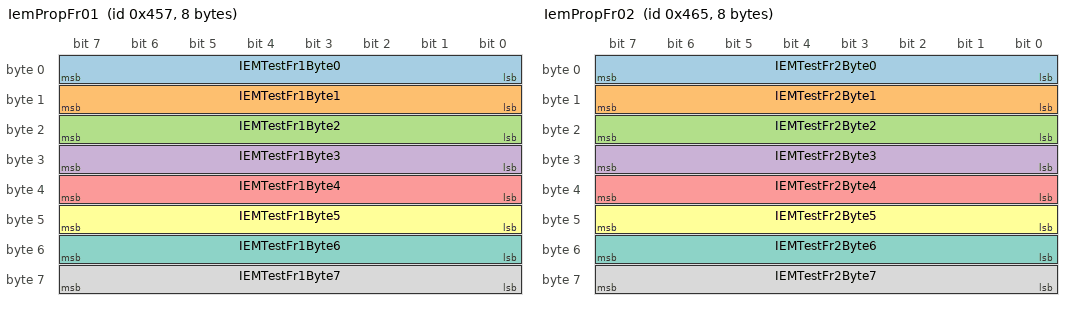
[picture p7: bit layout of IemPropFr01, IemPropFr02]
BO_ 1111 IemPropFr01: 8 IEM
 SG_ IEMTestFr1Byte0 : 7|8@0+ (1.0,0.0) [0.0|255.0] "Unitless" ETC
 SG_ IEMTestFr1Byte1 : 15|8@0+ (1.0,0.0) [0.0|255.0] "Unitless" ETC
 SG_ IEMTestFr1Byte2 : 23|8@0+ (1.0,0.0) [0.0|255.0] "Unitless" ETC
 SG_ IEMTestFr1Byte3 : 31|8@0+ (1.0,0.0) [0.0|255.0] "Unitless" ETC
 SG_ IEMTestFr1Byte4 : 39|8@0+ (1.0,0.0) [0.0|255.0] "Unitless" ETC
 SG_ IEMTestFr1Byte5 : 47|8@0+ (1.0,0.0) [0.0|255.0] "Unitless" ETC
 SG_ IEMTestFr1Byte6 : 55|8@0+ (1.0,0.0) [0.0|255.0] "Unitless" ETC
 SG_ IEMTestFr1Byte7 : 63|8@0+ (1.0,0.0) [0.0|255.0] "Unitless" ETC

BO_ 1125 IemPropFr02: 8 IEM
 SG_ IEMTestFr2Byte0 : 7|8@0+ (1.0,0.0) [0.0|255.0] "Unitless" ETC
 SG_ IEMTestFr2Byte1 : 15|8@0+ (1.0,0.0) [0.0|255.0] "Unitless" ETC
 SG_ IEMTestFr2Byte2 : 23|8@0+ (1.0,0.0) [0.0|255.0] "Unitless" ETC
 SG_ IEMTestFr2Byte3 : 31|8@0+ (1.0,0.0) [0.0|255.0] "Unitless" ETC
 SG_ IEMTestFr2Byte4 : 39|8@0+ (1.0,0.0) [0.0|255.0] "Unitless" ETC
 SG_ IEMTestFr2Byte5 : 47|8@0+ (1.0,0.0) [0.0|255.0] "Unitless" ETC
 SG_ IEMTestFr2Byte6 : 55|8@0+ (1.0,0.0) [0.0|255.0] "Unitless" ETC
 SG_ IEMTestFr2Byte7 : 63|8@0+ (1.0,0.0) [0.0|255.0] "Unitless" ETC

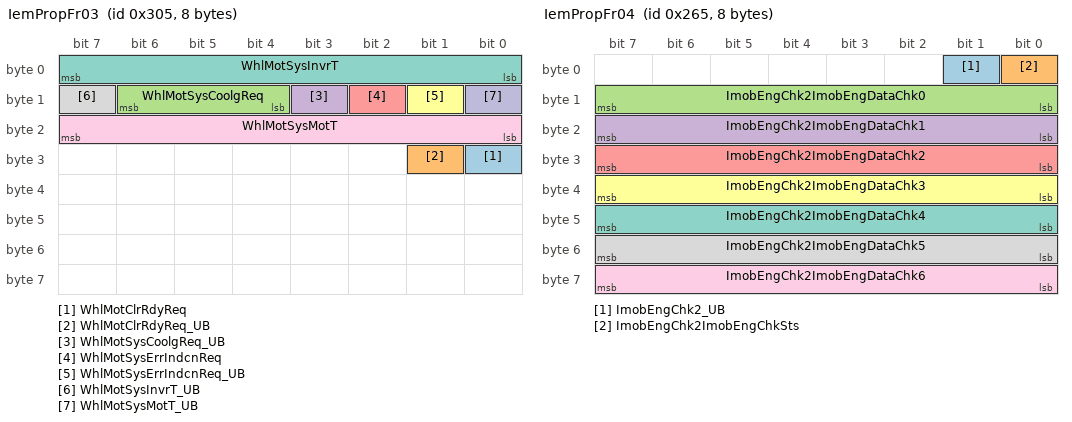
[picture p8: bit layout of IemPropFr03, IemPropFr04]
BO_ 773 IemPropFr03: 8 IEM
 SG_ WhlMotClrRdyReq : 24|1@0+ (1,0) [0|1] "" ECM
 SG_ WhlMotClrRdyReq_UB : 25|1@0+ (1,0) [0|1] "" ECM
 SG_ WhlMotSysCoolgReq : 14|3@0+ (1,0) [0|7] "" ECM
 SG_ WhlMotSysCoolgReq_UB : 11|1@0+ (1,0) [0|1] "" ECM
 SG_ WhlMotSysErrIndcnReq : 10|1@0+ (1,0) [0|1] "" ECM
 SG_ WhlMotSysErrIndcnReq_UB : 9|1@0+ (1,0) [0|1] "" ECM
 SG_ WhlMotSysInvrT : 7|8@0+ (1.0,-50.0) [-50.0|200.0] "degC" ECM,VDDM
 SG_ WhlMotSysInvrT_UB : 15|1@0+ (1,0) [0|1] "" ECM,VDDM
 SG_ WhlMotSysMotT : 23|8@0+ (1.0,-50.0) [-50.0|200.0] "degC" ECM,VDDM
 SG_ WhlMotSysMotT_UB : 8|1@0+ (1,0) [0|1] "" ECM,VDDM

BO_ 613 IemPropFr04: 8 IEM
 SG_ ImobEngChk2_UB : 1|1@0+ (1,0) [0|1] "" VDDM
 SG_ ImobEngChk2ImobEngChkSts : 0|1@0+ (1,0) [0|1] "" VDDM
 SG_ ImobEngChk2ImobEngDataChk0 : 15|8@0+ (1.0,0.0) [0.0|255.0] "Unitless" VDDM
 SG_ ImobEngChk2ImobEngDataChk1 : 23|8@0+ (1.0,0.0) [0.0|255.0] "Unitless" VDDM
 SG_ ImobEngChk2ImobEngDataChk2 : 31|8@0+ (1.0,0.0) [0.0|255.0] "Unitless" VDDM
 SG_ ImobEngChk2ImobEngDataChk3 : 39|8@0+ (1.0,0.0) [0.0|255.0] "Unitless" VDDM
 SG_ ImobEngChk2ImobEngDataChk4 : 47|8@0+ (1.0,0.0) [0.0|255.0] "Unitless" VDDM
 SG_ ImobEngChk2ImobEngDataChk5 : 55|8@0+ (1.0,0.0) [0.0|255.0] "Unitless" VDDM
 SG_ ImobEngChk2ImobEngDataChk6 : 63|8@0+ (1.0,0.0) [0.0|255.0] "Unitless" VDDM

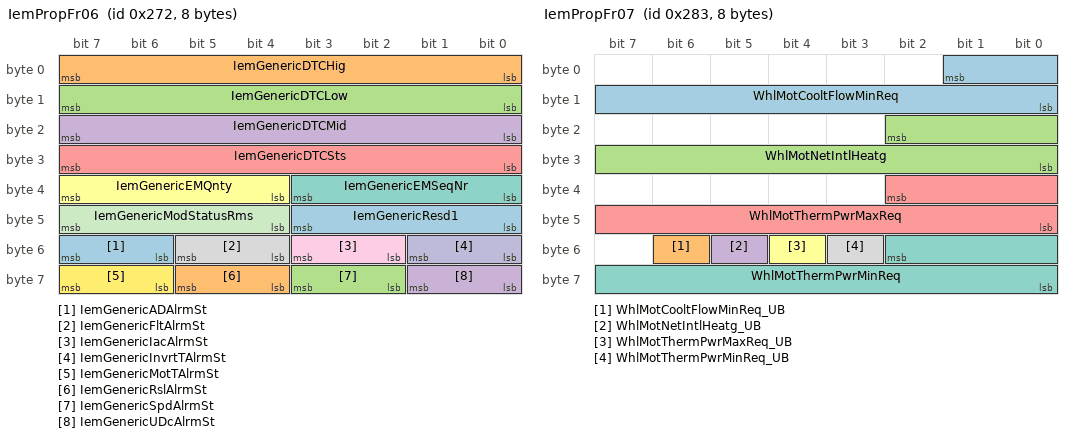
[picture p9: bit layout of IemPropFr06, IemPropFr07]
BO_ 626 IemPropFr06: 8 IEM
 SG_ IemGenericADAlrmSt : 55|2@0+ (1,0) [0|3] "" VDDM
 SG_ IemGenericDTCHig : 7|8@0+ (1.0,0.0) [0.0|255.0] "Unitless" VDDM
 SG_ IemGenericDTCLow : 15|8@0+ (1.0,0.0) [0.0|255.0] "Unitless" VDDM
 SG_ IemGenericDTCMid : 23|8@0+ (1.0,0.0) [0.0|255.0] "Unitless" VDDM
 SG_ IemGenericDTCSts : 31|8@0+ (1.0,0.0) [0.0|255.0] "Unitless" VDDM
 SG_ IemGenericEMQnty : 39|4@0+ (1.0,0.0) [0.0|15.0] "Unitless" VDDM
 SG_ IemGenericEMSeqNr : 35|4@0+ (1.0,0.0) [0.0|15.0] "Unitless" VDDM
 SG_ IemGenericFltAlrmSt : 53|2@0+ (1,0) [0|3] "" VDDM
 SG_ IemGenericIacAlrmSt : 51|2@0+ (1,0) [0|3] "" VDDM
 SG_ IemGenericInvrtTAlrmSt : 49|2@0+ (1,0) [0|3] "" VDDM
 SG_ IemGenericModStatusRms : 47|4@0+ (1,0) [0|15] "" VDDM
 SG_ IemGenericMotTAlrmSt : 63|2@0+ (1,0) [0|3] "" VDDM
 SG_ IemGenericResd1 : 43|4@0+ (1.0,0.0) [0.0|15.0] "Unitless" VDDM
 SG_ IemGenericRslAlrmSt : 61|2@0+ (1,0) [0|3] "" VDDM
 SG_ IemGenericSpdAlrmSt : 59|2@0+ (1,0) [0|3] "" VDDM
 SG_ IemGenericUDcAlrmSt : 57|2@0+ (1,0) [0|3] "" VDDM

BO_ 643 IemPropFr07: 8 IEM
 SG_ WhlMotCooltFlowMinReq : 1|10@0+ (0.01,0.0) [0.0|10.23] "L / min" ECM
 SG_ WhlMotCooltFlowMinReq_UB : 54|1@0+ (1,0) [0|1] "" ECM
 SG_ WhlMotNetIntlHeatg : 18|11@0- (10.0,0.0) [-10000.0|10000.0] "W" ECM
 SG_ WhlMotNetIntlHeatg_UB : 53|1@0+ (1,0) [0|1] "" ECM
 SG_ WhlMotThermPwrMaxReq : 34|11@0- (10.0,0.0) [-10000.0|10000.0] "W" ECM
 SG_ WhlMotThermPwrMaxReq_UB : 52|1@0+ (1,0) [0|1] "" ECM
 SG_ WhlMotThermPwrMinReq : 50|11@0- (10.0,0.0) [-10000.0|10000.0] "W" ECM
 SG_ WhlMotThermPwrMinReq_UB : 51|1@0+ (1,0) [0|1] "" ECM

BO_ 99 IemPropFr08: 8 IEM
 SG_ WhlMotSysIdc : 5|14@0+ (0.1,-818.8) [-818.8|819.2] "A" ECM,VDDM
 SG_ WhlMotSysIdc_UB : 6|1@0+ (1,0) [0|1] "" ECM,VDDM

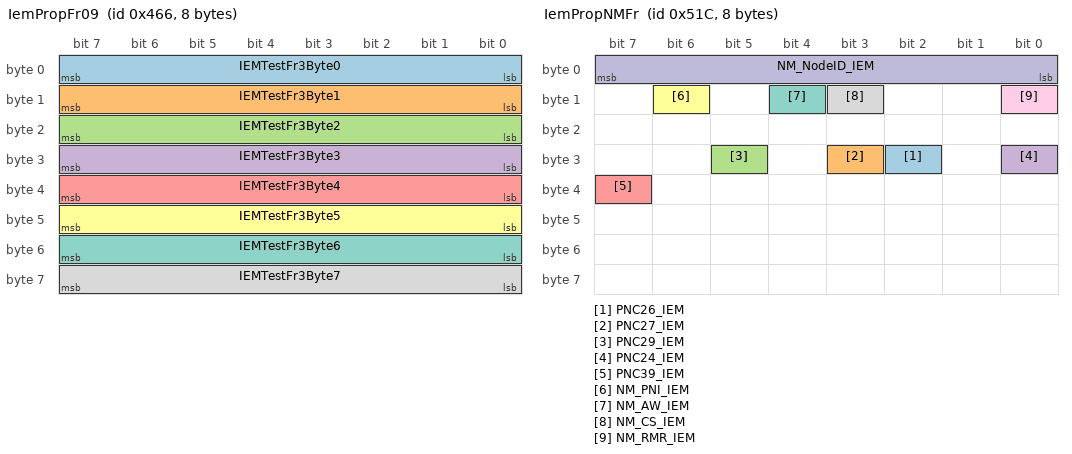
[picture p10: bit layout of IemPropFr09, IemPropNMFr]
BO_ 1126 IemPropFr09: 8 IEM
 SG_ IEMTestFr3Byte0 : 7|8@0+ (1.0,0.0) [0.0|255.0] "Unitless" ETC
 SG_ IEMTestFr3Byte1 : 15|8@0+ (1.0,0.0) [0.0|255.0] "Unitless" ETC
 SG_ IEMTestFr3Byte2 : 23|8@0+ (1.0,0.0) [0.0|255.0] "Unitless" ETC
 SG_ IEMTestFr3Byte3 : 31|8@0+ (1.0,0.0) [0.0|255.0] "Unitless" ETC
 SG_ IEMTestFr3Byte4 : 39|8@0+ (1.0,0.0) [0.0|255.0] "Unitless" ETC
 SG_ IEMTestFr3Byte5 : 47|8@0+ (1.0,0.0) [0.0|255.0] "Unitless" ETC
 SG_ IEMTestFr3Byte6 : 55|8@0+ (1.0,0.0) [0.0|255.0] "Unitless" ETC
 SG_ IEMTestFr3Byte7 : 63|8@0+ (1.0,0.0) [0.0|255.0] "Unitless" ETC

BO_ 1308 IemPropNMFr: 8 IEM
 SG_ PNC26_IEM : 26|1@0+ (1,0) [0|0] "" ESM
 SG_ PNC27_IEM : 27|1@0+ (1,0) [0|0] "" ESM
 SG_ PNC29_IEM : 29|1@0+ (1,0) [0|0] "" ESM
 SG_ PNC24_IEM : 24|1@0+ (1,0) [0|0] "" ESM
 SG_ PNC39_IEM : 39|1@0+ (1,0) [0|0] "" ESM
 SG_ NM_PNI_IEM : 14|1@0+ (1,0) [0|0] "" ESM
 SG_ NM_AW_IEM : 12|1@0+ (1,0) [0|0] "" ESM
 SG_ NM_CS_IEM : 11|1@0+ (1,0) [0|0] "" ESM
 SG_ NM_RMR_IEM : 8|1@0+ (1,0) [0|0] "" ESM
 SG_ NM_NodeID_IEM : 7|8@0+ (1,0) [0|0] "" ESM

BO_ 1591 IemToVddmPropDiagResFrame: 8 IEM
 SG_ IemToVddmPropDiagResNpdu : 7|64@0+ (1,0) [0|0] "" VDDM

BO_ 2027 IemToVgmJ1979OBDPropCanResFrame11: 8 IEM
 SG_ IemToVgmJ1979OBDPropCanResNpdu11 : 7|64@0+ (1,0) [0|0] "" VGM

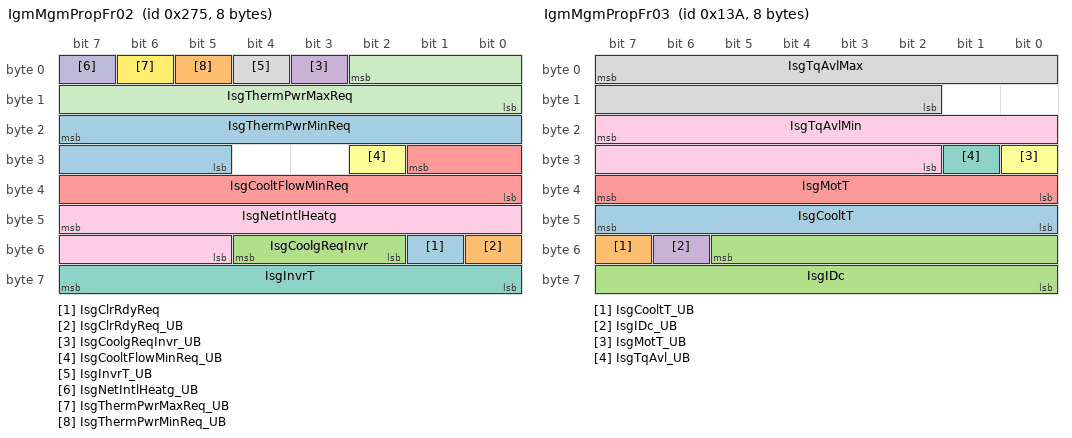
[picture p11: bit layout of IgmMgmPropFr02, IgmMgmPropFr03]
BO_ 629 IgmMgmPropFr02: 8 IGM
 SG_ IsgClrRdyReq : 49|1@0+ (1,0) [0|1] "" ECM
 SG_ IsgClrRdyReq_UB : 48|1@0+ (1,0) [0|1] "" ECM
 SG_ IsgCoolgReqInvr : 52|3@0+ (1,0) [0|7] "" ECM
 SG_ IsgCoolgReqInvr_UB : 3|1@0+ (1,0) [0|1] "" ECM
 SG_ IsgCooltFlowMinReq : 25|10@0+ (0.01,0.0) [0.0|10.23] "L / min" ECM
 SG_ IsgCooltFlowMinReq_UB : 26|1@0+ (1,0) [0|1] "" ECM
 SG_ IsgInvrT : 63|8@0+ (1.0,-50.0) [-50.0|200.0] "degC" ECM,VDDM
 SG_ IsgInvrT_UB : 4|1@0+ (1,0) [0|1] "" ECM,VDDM
 SG_ IsgNetIntlHeatg : 47|11@0- (10.0,0.0) [-10000.0|10000.0] "W" ECM
 SG_ IsgNetIntlHeatg_UB : 7|1@0+ (1,0) [0|1] "" ECM
 SG_ IsgThermPwrMaxReq : 2|11@0- (10.0,0.0) [-10000.0|10000.0] "W" ECM
 SG_ IsgThermPwrMaxReq_UB : 6|1@0+ (1,0) [0|1] "" ECM
 SG_ IsgThermPwrMinReq : 23|11@0- (10.0,0.0) [-10000.0|10000.0] "W" ECM
 SG_ IsgThermPwrMinReq_UB : 5|1@0+ (1,0) [0|1] "" ECM

BO_ 314 IgmMgmPropFr03: 8 IGM
 SG_ IsgCooltT : 47|8@0+ (1.0,-40.0) [-40.0|215.0] "degC" BECM,ECM,VDDM
 SG_ IsgCooltT_UB : 55|1@0+ (1,0) [0|1] "" BECM,ECM,VDDM
 SG_ IsgIDc : 53|14@0+ (0.1,-818.8) [-818.8|819.2] "A" ECM,VDDM
 SG_ IsgIDc_UB : 54|1@0+ (1,0) [0|1] "" ECM,VDDM
 SG_ IsgMotT : 39|8@0+ (1.0,-50.0) [-50.0|200.0] "degC" ECM,VDDM
 SG_ IsgMotT_UB : 24|1@0+ (1,0) [0|1] "" ECM,VDDM
 SG_ IsgTqAvl_UB : 25|1@0+ (1,0) [0|1] "" ECM
 SG_ IsgTqAvlMax : 7|14@0+ (1.0,-8188.0) [-8188.0|8192.0] "NewtonMeter" ECM
 SG_ IsgTqAvlMin : 23|14@0+ (1.0,-8188.0) [-8188.0|8192.0] "NewtonMeter" ECM

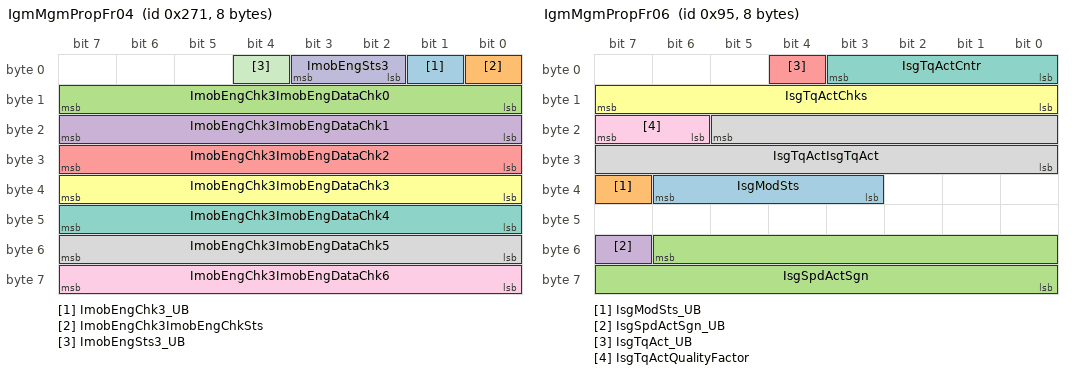
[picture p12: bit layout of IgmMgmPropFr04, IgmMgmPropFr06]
BO_ 625 IgmMgmPropFr04: 8 IGM
 SG_ ImobEngChk3_UB : 1|1@0+ (1,0) [0|1] "" VDDM
 SG_ ImobEngChk3ImobEngChkSts : 0|1@0+ (1,0) [0|1] "" VDDM
 SG_ ImobEngChk3ImobEngDataChk0 : 15|8@0+ (1.0,0.0) [0.0|255.0] "Unitless" VDDM
 SG_ ImobEngChk3ImobEngDataChk1 : 23|8@0+ (1.0,0.0) [0.0|255.0] "Unitless" VDDM
 SG_ ImobEngChk3ImobEngDataChk2 : 31|8@0+ (1.0,0.0) [0.0|255.0] "Unitless" VDDM
 SG_ ImobEngChk3ImobEngDataChk3 : 39|8@0+ (1.0,0.0) [0.0|255.0] "Unitless" VDDM
 SG_ ImobEngChk3ImobEngDataChk4 : 47|8@0+ (1.0,0.0) [0.0|255.0] "Unitless" VDDM
 SG_ ImobEngChk3ImobEngDataChk5 : 55|8@0+ (1.0,0.0) [0.0|255.0] "Unitless" VDDM
 SG_ ImobEngChk3ImobEngDataChk6 : 63|8@0+ (1.0,0.0) [0.0|255.0] "Unitless" VDDM
 SG_ ImobEngSts3 : 3|2@0+ (1,0) [0|3] "" VDDM
 SG_ ImobEngSts3_UB : 4|1@0+ (1,0) [0|1] "" VDDM

BO_ 342 IgmMgmPropFr05: 8 IGM
 SG_ IsgLimnIndcn : 55|16@0+ (1.0,0.0) [0.0|65535.0] "Unitless" ECM,VDDM
 SG_ IsgLimnIndcn_UB : 20|1@0+ (1,0) [0|1] "" ECM,VDDM
 SG_ IsgUDc : 2|11@0+ (0.25,0.0) [0.0|511.0] "Volt" ECM,VDDM
 SG_ IsgUDc_UB : 3|1@0+ (1,0) [0|1] "" ECM,VDDM

BO_ 149 IgmMgmPropFr06: 8 IGM
 SG_ IsgModSts : 38|4@0+ (1,0) [0|15] "" BECM,ECM,VDDM
 SG_ IsgModSts_UB : 39|1@0+ (1,0) [0|1] "" BECM,ECM,VDDM
 SG_ IsgSpdActSgn : 54|15@0- (1.0,0.0) [-16384.0|16383.0] "rpm" ECM,VDDM
 SG_ IsgSpdActSgn_UB : 55|1@0+ (1,0) [0|1] "" ECM,VDDM
 SG_ IsgTqAct_UB : 4|1@0+ (1,0) [0|1] "" ECM,VDDM
 SG_ IsgTqActChks : 15|8@0+ (1.0,0.0) [0.0|255.0] "Unitless" ECM,VDDM
 SG_ IsgTqActCntr : 3|4@0+ (1.0,0.0) [0.0|15.0] "Unitless" ECM,VDDM
 SG_ IsgTqActIsgTqAct : 21|14@0+ (1.0,-8188.0) [-8188.0|8192.0] "NewtonMeter" ECM,VDDM
 SG_ IsgTqActQualityFactor : 23|2@0+ (1,0) [0|3] "" ECM,VDDM

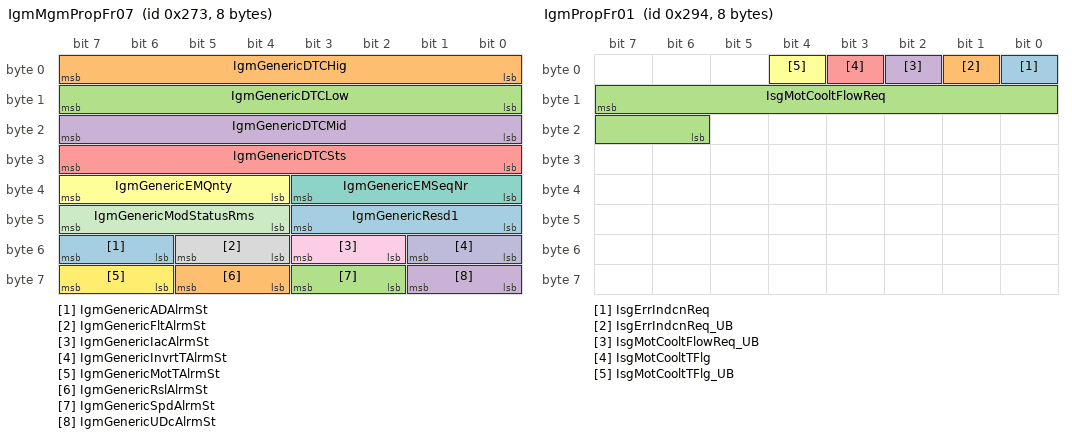
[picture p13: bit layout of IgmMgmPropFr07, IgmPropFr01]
BO_ 627 IgmMgmPropFr07: 8 IGM
 SG_ IgmGenericADAlrmSt : 55|2@0+ (1,0) [0|3] "" VDDM
 SG_ IgmGenericDTCHig : 7|8@0+ (1.0,0.0) [0.0|255.0] "Unitless" VDDM
 SG_ IgmGenericDTCLow : 15|8@0+ (1.0,0.0) [0.0|255.0] "Unitless" VDDM
 SG_ IgmGenericDTCMid : 23|8@0+ (1.0,0.0) [0.0|255.0] "Unitless" VDDM
 SG_ IgmGenericDTCSts : 31|8@0+ (1.0,0.0) [0.0|255.0] "Unitless" VDDM
 SG_ IgmGenericEMQnty : 39|4@0+ (1.0,0.0) [0.0|15.0] "Unitless" VDDM
 SG_ IgmGenericEMSeqNr : 35|4@0+ (1.0,0.0) [0.0|15.0] "Unitless" VDDM
 SG_ IgmGenericFltAlrmSt : 53|2@0+ (1,0) [0|3] "" VDDM
 SG_ IgmGenericIacAlrmSt : 51|2@0+ (1,0) [0|3] "" VDDM
 SG_ IgmGenericInvrtTAlrmSt : 49|2@0+ (1,0) [0|3] "" VDDM
 SG_ IgmGenericModStatusRms : 47|4@0+ (1,0) [0|15] "" VDDM
 SG_ IgmGenericMotTAlrmSt : 63|2@0+ (1,0) [0|3] "" VDDM
 SG_ IgmGenericResd1 : 43|4@0+ (1.0,0.0) [0.0|15.0] "Unitless" VDDM
 SG_ IgmGenericRslAlrmSt : 61|2@0+ (1,0) [0|3] "" VDDM
 SG_ IgmGenericSpdAlrmSt : 59|2@0+ (1,0) [0|3] "" VDDM
 SG_ IgmGenericUDcAlrmSt : 57|2@0+ (1,0) [0|3] "" VDDM

BO_ 660 IgmPropFr01: 8 IGM
 SG_ IsgErrIndcnReq : 0|1@0+ (1,0) [0|1] "" ECM
 SG_ IsgErrIndcnReq_UB : 1|1@0+ (1,0) [0|1] "" ECM
 SG_ IsgMotCooltFlowReq : 15|10@0+ (0.05,0.0) [0.0|51.150000000000006] "L / min" ECM
 SG_ IsgMotCooltFlowReq_UB : 2|1@0+ (1,0) [0|1] "" ECM
 SG_ IsgMotCooltTFlg : 3|1@0+ (1,0) [0|1] "" ECM
 SG_ IsgMotCooltTFlg_UB : 4|1@0+ (1,0) [0|1] "" ECM

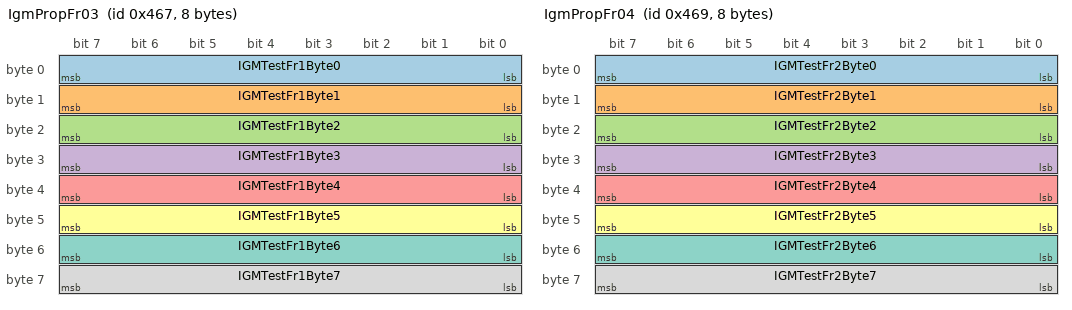
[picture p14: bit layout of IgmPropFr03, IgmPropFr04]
BO_ 1127 IgmPropFr03: 8 IGM
 SG_ IGMTestFr1Byte0 : 7|8@0+ (1.0,0.0) [0.0|255.0] "Unitless" ETC
 SG_ IGMTestFr1Byte1 : 15|8@0+ (1.0,0.0) [0.0|255.0] "Unitless" ETC
 SG_ IGMTestFr1Byte2 : 23|8@0+ (1.0,0.0) [0.0|255.0] "Unitless" ETC
 SG_ IGMTestFr1Byte3 : 31|8@0+ (1.0,0.0) [0.0|255.0] "Unitless" ETC
 SG_ IGMTestFr1Byte4 : 39|8@0+ (1.0,0.0) [0.0|255.0] "Unitless" ETC
 SG_ IGMTestFr1Byte5 : 47|8@0+ (1.0,0.0) [0.0|255.0] "Unitless" ETC
 SG_ IGMTestFr1Byte6 : 55|8@0+ (1.0,0.0) [0.0|255.0] "Unitless" ETC
 SG_ IGMTestFr1Byte7 : 63|8@0+ (1.0,0.0) [0.0|255.0] "Unitless" ETC

BO_ 1129 IgmPropFr04: 8 IGM
 SG_ IGMTestFr2Byte0 : 7|8@0+ (1.0,0.0) [0.0|255.0] "Unitless" ETC
 SG_ IGMTestFr2Byte1 : 15|8@0+ (1.0,0.0) [0.0|255.0] "Unitless" ETC
 SG_ IGMTestFr2Byte2 : 23|8@0+ (1.0,0.0) [0.0|255.0] "Unitless" ETC
 SG_ IGMTestFr2Byte3 : 31|8@0+ (1.0,0.0) [0.0|255.0] "Unitless" ETC
 SG_ IGMTestFr2Byte4 : 39|8@0+ (1.0,0.0) [0.0|255.0] "Unitless" ETC
 SG_ IGMTestFr2Byte5 : 47|8@0+ (1.0,0.0) [0.0|255.0] "Unitless" ETC
 SG_ IGMTestFr2Byte6 : 55|8@0+ (1.0,0.0) [0.0|255.0] "Unitless" ETC
 SG_ IGMTestFr2Byte7 : 63|8@0+ (1.0,0.0) [0.0|255.0] "Unitless" ETC

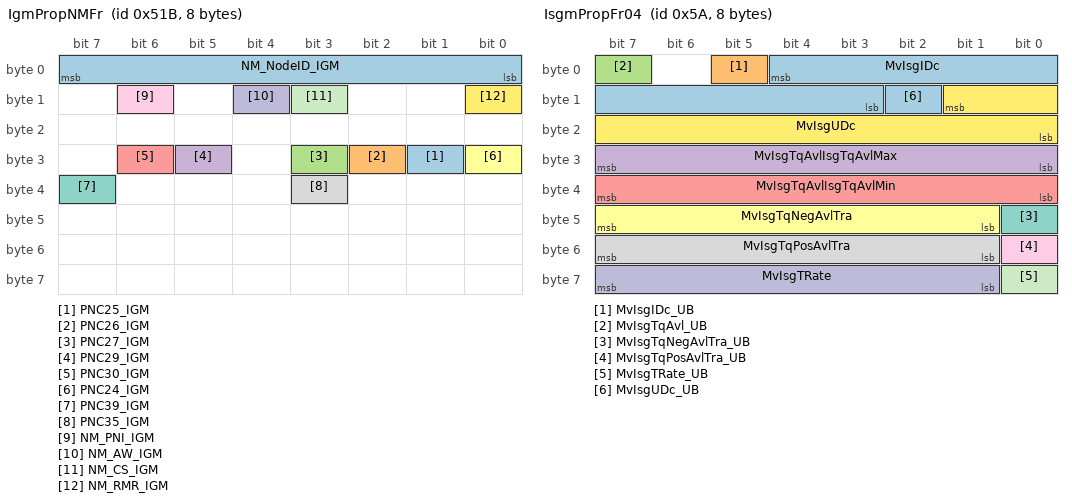
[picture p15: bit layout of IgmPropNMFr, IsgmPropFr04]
BO_ 1307 IgmPropNMFr: 8 IGM
 SG_ PNC25_IGM : 25|1@0+ (1,0) [0|0] "" IEM
 SG_ PNC26_IGM : 26|1@0+ (1,0) [0|0] "" IEM
 SG_ PNC27_IGM : 27|1@0+ (1,0) [0|0] "" IEM
 SG_ PNC29_IGM : 29|1@0+ (1,0) [0|0] "" IEM
 SG_ PNC30_IGM : 30|1@0+ (1,0) [0|0] "" IEM
 SG_ PNC24_IGM : 24|1@0+ (1,0) [0|0] "" IEM
 SG_ PNC39_IGM : 39|1@0+ (1,0) [0|0] "" IEM
 SG_ PNC35_IGM : 35|1@0+ (1,0) [0|0] "" IEM
 SG_ NM_PNI_IGM : 14|1@0+ (1,0) [0|0] "" IEM
 SG_ NM_AW_IGM : 12|1@0+ (1,0) [0|0] "" IEM
 SG_ NM_CS_IGM : 11|1@0+ (1,0) [0|0] "" IEM
 SG_ NM_RMR_IGM : 8|1@0+ (1,0) [0|0] "" IEM
 SG_ NM_NodeID_IGM : 7|8@0+ (1,0) [0|0] "" IEM

BO_ 1590 IgmToVddmPropDiagResFrame: 8 IGM
 SG_ IgmToVddmPropDiagResNpdu : 7|64@0+ (1,0) [0|0] "" VDDM

BO_ 2028 IgmToVgmJ1979OBDPropCanResFrame11: 8 IGM
 SG_ IgmToVgmJ1979OBDPropCanResNpdu11 : 7|64@0+ (1,0) [0|0] "" VGM

BO_ 90 IsgmPropFr04: 8 ISGM
 SG_ MvIsgIDc : 4|10@0+ (1.0,-410.0) [-410.0|410.0] "A" ECM,MVBM
 SG_ MvIsgIDc_UB : 5|1@0+ (1,0) [0|1] "" ECM,MVBM
 SG_ MvIsgTqAvl_UB : 7|1@0+ (1,0) [0|1] "" ECM
 SG_ MvIsgTqAvlIsgTqAvlMax : 31|8@0+ (0.5,0.0) [0.0|70.0] "NewtonMeter" ECM
 SG_ MvIsgTqAvlIsgTqAvlMin : 39|8@0+ (0.5,-70.0) [-70.0|0.0] "NewtonMeter" ECM
 SG_ MvIsgTqNegAvlTra : 47|7@0+ (-0.5,0.0) [-55.0|0.0] "NewtonMeter" ECM
 SG_ MvIsgTqNegAvlTra_UB : 40|1@0+ (1,0) [0|1] "" ECM
 SG_ MvIsgTqPosAvlTra : 55|7@0+ (0.5,0.0) [0.0|55.0] "NewtonMeter" ECM
 SG_ MvIsgTqPosAvlTra_UB : 48|1@0+ (1,0) [0|1] "" ECM
 SG_ MvIsgTRate : 63|7@0+ (1.0,0.0) [0.0|120.0] "%" ECM
 SG_ MvIsgTRate_UB : 56|1@0+ (1,0) [0|1] "" ECM
 SG_ MvIsgUDc : 9|10@0+ (0.1,0.0) [0.0|102.30000000000001] "Volt" ECM,MVBM
 SG_ MvIsgUDc_UB : 10|1@0+ (1,0) [0|1] "" ECM,MVBM

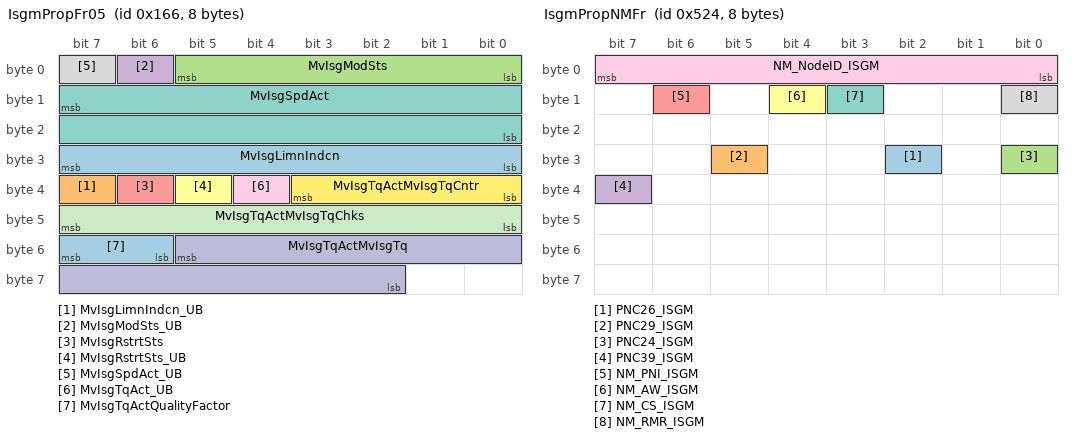
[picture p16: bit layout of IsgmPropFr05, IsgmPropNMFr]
BO_ 358 IsgmPropFr05: 8 ISGM
 SG_ MvIsgLimnIndcn : 31|8@0+ (1.0,0.0) [0.0|255.0] "Unitless" ECM
 SG_ MvIsgLimnIndcn_UB : 39|1@0+ (1,0) [0|1] "" ECM
 SG_ MvIsgModSts : 5|6@0+ (1,0) [0|63] "" ECM,VDDM
 SG_ MvIsgModSts_UB : 6|1@0+ (1,0) [0|1] "" ECM,VDDM
 SG_ MvIsgRstrtSts : 38|1@0+ (1,0) [0|1] "" ECM
 SG_ MvIsgRstrtSts_UB : 37|1@0+ (1,0) [0|1] "" ECM
 SG_ MvIsgSpdAct : 15|16@0+ (1.0,-10000.0) [-10000.0|22000.0] "rpm" ECM
 SG_ MvIsgSpdAct_UB : 7|1@0+ (1,0) [0|1] "" ECM
 SG_ MvIsgTqAct_UB : 36|1@0+ (1,0) [0|1] "" ECM
 SG_ MvIsgTqActMvIsgTq : 53|12@0+ (0.1,-70.0) [-70.0|70.0] "NewtonMeter" ECM
 SG_ MvIsgTqActMvIsgTqChks : 47|8@0+ (1.0,0.0) [0.0|255.0] "Unitless" ECM
 SG_ MvIsgTqActMvIsgTqCntr : 35|4@0+ (1.0,0.0) [0.0|15.0] "Unitless" ECM
 SG_ MvIsgTqActQualityFactor : 55|2@0+ (1,0) [0|3] "" ECM

BO_ 897 IsgmPropFr07: 8 ISGM
 SG_ MvIsgFltState1_UB : 10|1@0+ (1,0) [0|1] "" ECM
 SG_ MvIsgFltState1MvIsgIvtrThermProtn : 7|1@0+ (1,0) [0|1] "" ECM
 SG_ MvIsgFltState1MvIsgLoadDump : 6|1@0+ (1,0) [0|1] "" ECM
 SG_ MvIsgFltState1MvIsgNegSpdDetn : 5|1@0+ (1,0) [0|1] "" ECM
 SG_ MvIsgFltState1MvIsgOvrheatg : 4|1@0+ (1,0) [0|1] "" ECM
 SG_ MvIsgFltState1MvIsgPwrLimn : 3|1@0+ (1,0) [0|1] "" ECM
 SG_ MvIsgFltState1MvIsgStrtrModWarn : 2|1@0+ (1,0) [0|1] "" ECM
 SG_ MvIsgFltState1MvIsgULo : 1|1@0+ (1,0) [0|1] "" ECM
 SG_ MvIsgFltState1MvIsgUOvld : 0|1@0+ (1,0) [0|1] "" ECM
 SG_ MvIsgFltState2_UB : 47|1@0+ (1,0) [0|1] "" ECM
 SG_ MvIsgFltState2MvIsgBrushWearUDrpFlt : 9|1@0+ (1,0) [0|1] "" ECM
 SG_ MvIsgFltState2MvIsgCanFlt : 8|1@0+ (1,0) [0|1] "" ECM
 SG_ MvIsgFltState2MvIsgExctCircHiSideFlt : 23|1@0+ (1,0) [0|1] "" ECM
 SG_ MvIsgFltState2MvIsgIOvld : 18|1@0+ (1,0) [0|1] "" ECM
 SG_ MvIsgFltState2MvIsgPwrModuleIvtrFlt : 19|1@0+ (1,0) [0|1] "" ECM
 SG_ MvIsgFltState2MvIsgPwrModuleStrtrFlt : 20|1@0+ (1,0) [0|1] "" ECM
 SG_ MvIsgFltState2MvIsgRotorIOvld : 21|1@0+ (1,0) [0|1] "" ECM
 SG_ MvIsgFltState2MvIsgTqLvlFlt : 22|1@0+ (1,0) [0|1] "" ECM
 SG_ MvIsgFltState3_UB : 46|1@0+ (1,0) [0|1] "" ECM
 SG_ MvIsgFltState3BattUHi : 31|1@0+ (1,0) [0|1] "" ECM
 SG_ MvIsgFltState3BattULo : 30|1@0+ (1,0) [0|1] "" ECM
 SG_ MvIsgFltState3MvIsg48vVSClOc : 29|1@0+ (1,0) [0|1] "" ECM
 SG_ MvIsgFltState3MvIsgExctCircLatentFlt : 28|1@0+ (1,0) [0|1] "" ECM
 SG_ MvIsgFltState3MvIsgRotorOpenCircFlt : 27|1@0+ (1,0) [0|1] "" ECM
 SG_ MvIsgFltState3MvIsgRPSCh : 26|1@0+ (1,0) [0|1] "" ECM
 SG_ MvIsgFltState3MvIsgRPSClOc : 25|1@0+ (1,0) [0|1] "" ECM
 SG_ MvIsgFltState3MvIsgRvsSpdFlt : 24|1@0+ (1,0) [0|1] "" ECM
 SG_ MvIsgFltState4_UB : 45|1@0+ (1,0) [0|1] "" ECM
 SG_ MvIsgFltState4MvIsg48vVSCh : 39|1@0+ (1,0) [0|1] "" ECM
 SG_ MvIsgFltState4MvIsgECSCh : 38|1@0+ (1,0) [0|1] "" ECM
 SG_ MvIsgFltState4MvIsgECSClOc : 37|1@0+ (1,0) [0|1] "" ECM
 SG_ MvIsgFltState4MvIsgPCSCl : 36|1@0+ (1,0) [0|1] "" ECM
 SG_ MvIsgFltState4MvIsgPCSOc : 35|1@0+ (1,0) [0|1] "" ECM
 SG_ MvIsgFltState4MvIsgTECl : 34|1@0+ (1,0) [0|1] "" ECM
 SG_ MvIsgFltState4MvIsgTPCBChOc : 33|1@0+ (1,0) [0|1] "" ECM
 SG_ MvIsgFltState4MvIsgTPCBCl : 32|1@0+ (1,0) [0|1] "" ECM
 SG_ MvIsgFltState5_UB : 44|1@0+ (1,0) [0|1] "" ECM
 SG_ MvIsgFltState5MvIsgPMSClCh : 43|1@0+ (1,0) [0|1] "" ECM
 SG_ MvIsgFltState5MvIsgPMSOc : 42|1@0+ (1,0) [0|1] "" ECM
 SG_ MvIsgFltState5MvIsgRotorPosnTrackingLoopFlt : 41|1@0+ (1,0) [0|1] "" ECM
 SG_ MvIsgFltState5MvIsgRPSOc : 40|1@0+ (1,0) [0|1] "" ECM
 SG_ MvIsgFltState5MvIsgTEChOc : 55|1@0+ (1,0) [0|1] "" ECM

BO_ 1316 IsgmPropNMFr: 8 ISGM
 SG_ PNC26_ISGM : 26|1@0+ (1,0) [0|0] "" IGM
 SG_ PNC29_ISGM : 29|1@0+ (1,0) [0|0] "" IGM
 SG_ PNC24_ISGM : 24|1@0+ (1,0) [0|0] "" IGM
 SG_ PNC39_ISGM : 39|1@0+ (1,0) [0|0] "" IGM
 SG_ NM_PNI_ISGM : 14|1@0+ (1,0) [0|0] "" IGM
 SG_ NM_AW_ISGM : 12|1@0+ (1,0) [0|0] "" IGM
 SG_ NM_CS_ISGM : 11|1@0+ (1,0) [0|0] "" IGM
 SG_ NM_RMR_ISGM : 8|1@0+ (1,0) [0|0] "" IGM
 SG_ NM_NodeID_ISGM : 7|8@0+ (1,0) [0|0] "" IGM

BO_ 1419 IsgmtoEtcXCPFr01: 8 ISGM

BO_ 1598 IsgmToVddmPropDiagResFrame: 8 ISGM
 SG_ IsgmToVddmPropDiagResNpdu : 7|64@0+ (1,0) [0|0] "" VDDM

BO_ 2028 IsgmToVgmJ1979OBDPropCanResFrame11: 8 ISGM
 SG_ IsgmToVgmJ1979OBDPropCanResNpdu11 : 7|64@0+ (1,0) [0|0] "" VGM

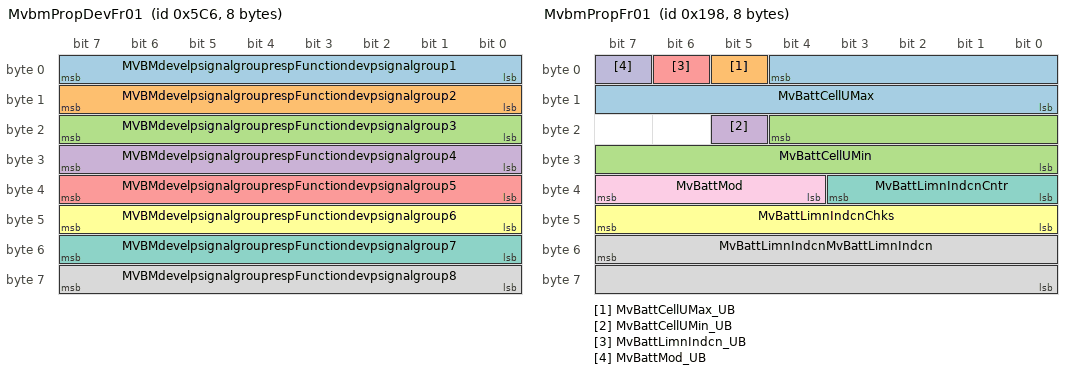
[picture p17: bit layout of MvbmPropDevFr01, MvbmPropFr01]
BO_ 1478 MvbmPropDevFr01: 8 MVBM
 SG_ MVBMdevelpsignalgrouprespFunctiondevpsignalgroup1 : 7|8@0+ (1.0,0.0) [0.0|255.0] "Unitless" ETC
 SG_ MVBMdevelpsignalgrouprespFunctiondevpsignalgroup2 : 15|8@0+ (1.0,0.0) [0.0|255.0] "Unitless" ETC
 SG_ MVBMdevelpsignalgrouprespFunctiondevpsignalgroup3 : 23|8@0+ (1.0,0.0) [0.0|255.0] "Unitless" ETC
 SG_ MVBMdevelpsignalgrouprespFunctiondevpsignalgroup4 : 31|8@0+ (1.0,0.0) [0.0|255.0] "Unitless" ETC
 SG_ MVBMdevelpsignalgrouprespFunctiondevpsignalgroup5 : 39|8@0+ (1.0,0.0) [0.0|255.0] "Unitless" ETC
 SG_ MVBMdevelpsignalgrouprespFunctiondevpsignalgroup6 : 47|8@0+ (1.0,0.0) [0.0|255.0] "Unitless" ETC
 SG_ MVBMdevelpsignalgrouprespFunctiondevpsignalgroup7 : 55|8@0+ (1.0,0.0) [0.0|255.0] "Unitless" ETC
 SG_ MVBMdevelpsignalgrouprespFunctiondevpsignalgroup8 : 63|8@0+ (1.0,0.0) [0.0|255.0] "Unitless" ETC

BO_ 408 MvbmPropFr01: 8 MVBM
 SG_ MvBattCellUMax : 4|13@0+ (0.001,0.0) [0.0|8.19] "Volt" ECM
 SG_ MvBattCellUMax_UB : 5|1@0+ (1,0) [0|1] "" ECM
 SG_ MvBattCellUMin : 20|13@0+ (0.001,0.0) [0.0|8.19] "Volt" ECM
 SG_ MvBattCellUMin_UB : 21|1@0+ (1,0) [0|1] "" ECM
 SG_ MvBattLimnIndcn_UB : 6|1@0+ (1,0) [0|1] "" ECM
 SG_ MvBattLimnIndcnChks : 47|8@0+ (1.0,0.0) [0.0|255.0] "Unitless" ECM
 SG_ MvBattLimnIndcnCntr : 35|4@0+ (1.0,0.0) [0.0|15.0] "Unitless" ECM
 SG_ MvBattLimnIndcnMvBattLimnIndcn : 55|16@0+ (1.0,0.0) [0.0|65535.0] "Unitless" ECM
 SG_ MvBattMod : 39|4@0+ (1,0) [0|15] "" ECM,VDDM
 SG_ MvBattMod_UB : 7|1@0+ (1,0) [0|1] "" ECM,VDDM

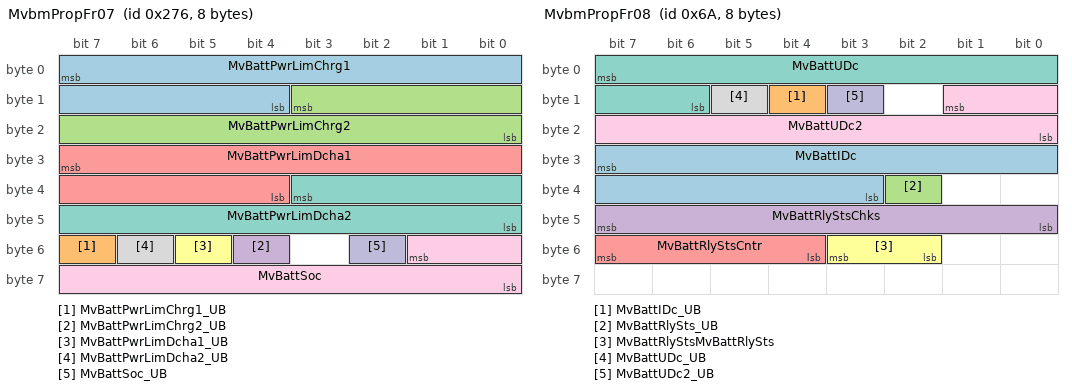
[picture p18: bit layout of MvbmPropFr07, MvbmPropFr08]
BO_ 630 MvbmPropFr07: 8 MVBM
 SG_ MvBattPwrLimChrg1 : 7|12@0+ (0.01,0.0) [0.0|40.94] "kW" ECM
 SG_ MvBattPwrLimChrg1_UB : 55|1@0+ (1,0) [0|1] "" ECM
 SG_ MvBattPwrLimChrg2 : 11|12@0+ (0.01,0.0) [0.0|40.94] "kW" ECM
 SG_ MvBattPwrLimChrg2_UB : 52|1@0+ (1,0) [0|1] "" ECM
 SG_ MvBattPwrLimDcha1 : 31|12@0+ (0.01,-40.94) [-40.94|0.0] "kW" ECM
 SG_ MvBattPwrLimDcha1_UB : 53|1@0+ (1,0) [0|1] "" ECM
 SG_ MvBattPwrLimDcha2 : 35|12@0+ (0.01,-40.94) [-40.94|0.0] "kW" ECM
 SG_ MvBattPwrLimDcha2_UB : 54|1@0+ (1,0) [0|1] "" ECM
 SG_ MvBattSoc : 49|10@0+ (0.1,0.0) [0.0|100.0] "%" ECM
 SG_ MvBattSoc_UB : 50|1@0+ (1,0) [0|1] "" ECM

BO_ 106 MvbmPropFr08: 8 MVBM
 SG_ MvBattIDc : 31|13@0- (0.25,0.0) [-1024.0|1023.75] "A" ECM
 SG_ MvBattIDc_UB : 12|1@0+ (1,0) [0|1] "" ECM
 SG_ MvBattRlySts_UB : 34|1@0+ (1,0) [0|1] "" ECM,ISGM,MVCM,VDDM
 SG_ MvBattRlyStsChks : 47|8@0+ (1.0,0.0) [0.0|255.0] "Unitless" ECM,ISGM,MVCM,VDDM
 SG_ MvBattRlyStsCntr : 55|4@0+ (1.0,0.0) [0.0|15.0] "Unitless" ECM,ISGM,MVCM,VDDM
 SG_ MvBattRlyStsMvBattRlySts : 51|2@0+ (1,0) [0|3] "" ECM,ISGM,MVCM,VDDM
 SG_ MvBattUDc : 7|10@0+ (0.1,0.0) [0.0|102.30000000000001] "Volt" ECM,MVCM
 SG_ MvBattUDc_UB : 13|1@0+ (1,0) [0|1] "" ECM,MVCM
 SG_ MvBattUDc2 : 9|10@0+ (0.1,0.0) [0.0|102.30000000000001] "Volt" ECM
 SG_ MvBattUDc2_UB : 11|1@0+ (1,0) [0|1] "" ECM

BO_ 584 MvbmPropFr10: 8 MVBM
 SG_ MvBattFltState1_UB : 6|1@0+ (1,0) [0|1] "" ECM
 SG_ MvBattFltState1MvBattBccComFlt : 23|1@0+ (1,0) [0|1] "" ECM
 SG_ MvBattFltState1MvBattBccFlt : 22|1@0+ (1,0) [0|1] "" ECM
 SG_ MvBattFltState1MvBattCellOvpFlt : 21|1@0+ (1,0) [0|1] "" ECM
 SG_ MvBattFltState1MvBattCellUvpFlt : 20|1@0+ (1,0) [0|1] "" ECM
 SG_ MvBattFltState1MvBattComFlt : 19|1@0+ (1,0) [0|1] "" ECM
 SG_ MvBattFltState1MvBattOcpFlt : 18|1@0+ (1,0) [0|1] "" ECM
 SG_ MvBattFltState1MvBattOvpFlt : 17|1@0+ (1,0) [0|1] "" ECM
 SG_ MvBattFltState1MvBattUvpFlt : 16|1@0+ (1,0) [0|1] "" ECM
 SG_ MvBattFltState2_UB : 7|1@0+ (1,0) [0|1] "" ECM
 SG_ MvBattFltState2BattUHi : 31|1@0+ (1,0) [0|1] "" ECM
 SG_ MvBattFltState2BattULo : 30|1@0+ (1,0) [0|1] "" ECM
 SG_ MvBattFltState2MvBattCbClsFlt : 29|1@0+ (1,0) [0|1] "" ECM
 SG_ MvBattFltState2MvBattCellUSampleFlt : 28|1@0+ (1,0) [0|1] "" ECM
 SG_ MvBattFltState2MvBattISampleFlt : 27|1@0+ (1,0) [0|1] "" ECM
 SG_ MvBattFltState2MvBattPrecFail : 26|1@0+ (1,0) [0|1] "" ECM
 SG_ MvBattFltState2MvBattTSGND : 25|1@0+ (1,0) [0|1] "" ECM
 SG_ MvBattFltState2MvBattTSPWR : 24|1@0+ (1,0) [0|1] "" ECM
 SG_ MvBattFltState3_UB : 5|1@0+ (1,0) [0|1] "" ECM
 SG_ MvBattFltState3MvBattCVSGND : 32|1@0+ (1,0) [0|1] "" ECM
 SG_ MvBattFltState3MvBattCVSOc : 33|1@0+ (1,0) [0|1] "" ECM
 SG_ MvBattFltState3MvBattCVSOOR : 34|1@0+ (1,0) [0|1] "" ECM
 SG_ MvBattFltState3MvBattCVSPWR : 35|1@0+ (1,0) [0|1] "" ECM
 SG_ MvBattFltState3MvBattPVSGND : 36|1@0+ (1,0) [0|1] "" ECM
 SG_ MvBattFltState3MvBattPVSOc : 37|1@0+ (1,0) [0|1] "" ECM
 SG_ MvBattFltState3MvBattPVSPWR : 38|1@0+ (1,0) [0|1] "" ECM
 SG_ MvBattFltState3MvBattTSOOR : 39|1@0+ (1,0) [0|1] "" ECM
 SG_ MvBattFltState4_UB : 47|1@0+ (1,0) [0|1] "" ECM
 SG_ MvBattFltState4MvBattCSGND : 40|1@0+ (1,0) [0|1] "" ECM
 SG_ MvBattFltState4MvBattCSOc : 41|1@0+ (1,0) [0|1] "" ECM
 SG_ MvBattFltState4MvBattCSOOR : 42|1@0+ (1,0) [0|1] "" ECM
 SG_ MvBattFltState4MvBattPVSOOR : 43|1@0+ (1,0) [0|1] "" ECM
 SG_ MvBattFltState4MvBattTVSGND : 44|1@0+ (1,0) [0|1] "" ECM
 SG_ MvBattFltState4MvBattTVSOOR : 45|1@0+ (1,0) [0|1] "" ECM
 SG_ MvBattFltState4MvBattTVSPWR : 46|1@0+ (1,0) [0|1] "" ECM

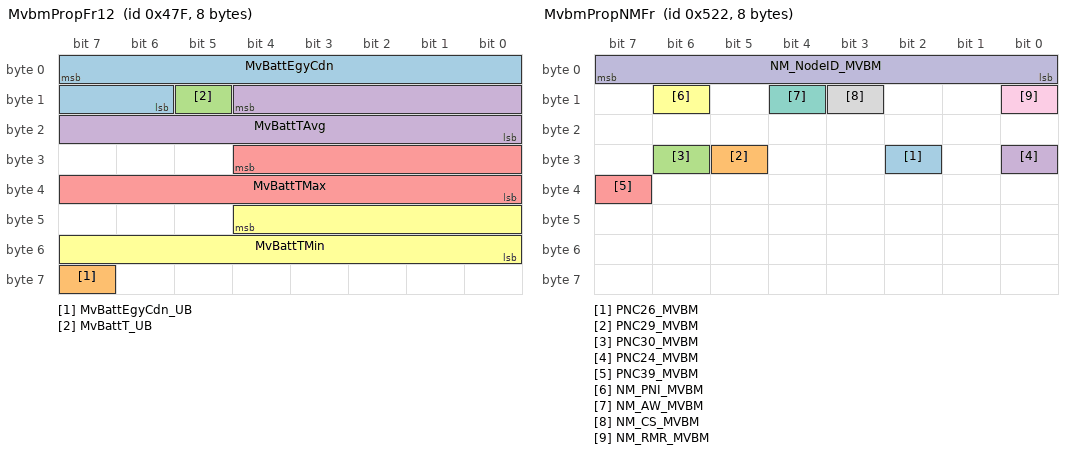
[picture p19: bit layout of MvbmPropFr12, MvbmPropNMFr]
BO_ 1151 MvbmPropFr12: 8 MVBM
 SG_ MvBattEgyCdn : 7|10@0+ (0.1,0.0) [0.0|100.0] "%" ECM
 SG_ MvBattEgyCdn_UB : 63|1@0+ (1,0) [0|1] "" ECM
 SG_ MvBattT_UB : 13|1@0+ (1,0) [0|1] "" ECM,VDDM
 SG_ MvBattTAvg : 12|13@0- (0.1,0.0) [-256.0|255.9] "degC" ECM,VDDM
 SG_ MvBattTMax : 28|13@0- (0.1,0.0) [-256.0|255.9] "degC" ECM,VDDM
 SG_ MvBattTMin : 44|13@0- (0.1,0.0) [-256.0|255.9] "degC" ECM,VDDM

BO_ 1314 MvbmPropNMFr: 8 MVBM
 SG_ PNC26_MVBM : 26|1@0+ (1,0) [0|0] "" Vector_XXX
 SG_ PNC29_MVBM : 29|1@0+ (1,0) [0|0] "" Vector_XXX
 SG_ PNC30_MVBM : 30|1@0+ (1,0) [0|0] "" Vector_XXX
 SG_ PNC24_MVBM : 24|1@0+ (1,0) [0|0] "" Vector_XXX
 SG_ PNC39_MVBM : 39|1@0+ (1,0) [0|0] "" Vector_XXX
 SG_ NM_PNI_MVBM : 14|1@0+ (1,0) [0|0] "" Vector_XXX
 SG_ NM_AW_MVBM : 12|1@0+ (1,0) [0|0] "" Vector_XXX
 SG_ NM_CS_MVBM : 11|1@0+ (1,0) [0|0] "" Vector_XXX
 SG_ NM_RMR_MVBM : 8|1@0+ (1,0) [0|0] "" Vector_XXX
 SG_ NM_NodeID_MVBM : 7|8@0+ (1,0) [0|0] "" Vector_XXX

BO_ 1618 MvbmToVddmPropDiagResFrame: 8 MVBM
 SG_ MvbmToVddmPropDiagResNpdu : 7|64@0+ (1,0) [0|0] "" VDDM

BO_ 2027 MvemToVgmJ1979OBDPropCanResFrame11: 8 MVEM
 SG_ MvemToVgmJ1979OBDPropCanResNpdu11 : 7|64@0+ (1,0) [0|0] "" VGM

CM_ SG_ 634 DenoOfDiagcRateGen "To indicate the whether the driving cycle meets the condition as a diagnostics denominator cycle defined in China Six J3.4.3.2";
CM_ SG_ 634 DrvgCyc " Transition from 0 to 1 indicates a start of a new Driving Cycle.";
CM_ SG_ 634 DrvgCycToClrPrmntDtc "China Sixth defines the cycle of clearing permanent fault codes. (J3.2.5.2 (B))";
CM_ SG_ 634 IuprDenominatorInhb "Inhibition flag of IUPR denominator from China Six.";
CM_ SG_ 1347 VFCVectorECMBlockID "Block Identifier";
CM_ SG_ 1347 VFCVectorECMVFCid0 "AdjustableDriveControls";
CM_ SG_ 1347 VFCVectorECMVFCid1 "ParkingDrivingClimatization";
CM_ SG_ 1347 VFCVectorECMVFCid10 "ExteriorLighting";
CM_ SG_ 1347 VFCVectorECMVFCid11 "Reserved";
CM_ SG_ 1347 VFCVectorECMVFCid12 "Alarm";
CM_ SG_ 1347 VFCVectorECMVFCid13 "Reserved";
CM_ SG_ 1347 VFCVectorECMVFCid14 "InteriorLighting";
CM_ SG_ 1347 VFCVectorECMVFCid15 "InteriorLightingEntrance";
CM_ SG_ 1347 VFCVectorECMVFCid16 "Locking";
CM_ SG_ 1347 VFCVectorECMVFCid17 "RemoteKey";
CM_ SG_ 1347 VFCVectorECMVFCid18 "PropulsionStart";
CM_ SG_ 1347 VFCVectorECMVFCid19 "PassiveSafetyAndRestraints";
CM_ SG_ 1347 VFCVectorECMVFCid2 "PostClimatisation";
CM_ SG_ 1347 VFCVectorECMVFCid20 "Reserved";
CM_ SG_ 1347 VFCVectorECMVFCid21 "PowerOperatedTailgate";
CM_ SG_ 1347 VFCVectorECMVFCid22 "VehicleDriving";
CM_ SG_ 1347 VFCVectorECMVFCid23 "Reserved";
CM_ SG_ 1347 VFCVectorECMVFCid24 "UserProfileInput";
CM_ SG_ 1347 VFCVectorECMVFCid25 "SeatComfortFunctions";
CM_ SG_ 1347 VFCVectorECMVFCid26 "Brake";
CM_ SG_ 1347 VFCVectorECMVFCid27 "InformationPoll";
CM_ SG_ 1347 VFCVectorECMVFCid28 "HVEnergyStorage";
CM_ SG_ 1347 VFCVectorECMVFCid29 "Reserved";
CM_ SG_ 1347 VFCVectorECMVFCid3 "PowertrainParkingClimatization";
CM_ SG_ 1347 VFCVectorECMVFCid30 "TelematicsConnectivity";
CM_ SG_ 1347 VFCVectorECMVFCid31 "Reserved";
CM_ SG_ 1347 VFCVectorECMVFCid32 "Entertainment";
CM_ SG_ 1347 VFCVectorECMVFCid33 "Diagnostics";
CM_ SG_ 1347 VFCVectorECMVFCid34 "AllECUs";
CM_ SG_ 1347 VFCVectorECMVFCid35 "TrailerCaravanFunctions";
CM_ SG_ 1347 VFCVectorECMVFCid36 "Immobilizer";
CM_ SG_ 1347 VFCVectorECMVFCid37 "Windows";
CM_ SG_ 1347 VFCVectorECMVFCid38 "Visibility";
CM_ SG_ 1347 VFCVectorECMVFCid39 "WarningSounds";
CM_ SG_ 1347 VFCVectorECMVFCid4 "Reserved";
CM_ SG_ 1347 VFCVectorECMVFCid40 "Entrance";
CM_ SG_ 1347 VFCVectorECMVFCid41 "InfotainmentPush";
CM_ SG_ 1347 VFCVectorECMVFCid42 "ChargingHV";
CM_ SG_ 1347 VFCVectorECMVFCid43 "BodyPreClimatisation";
CM_ SG_ 1347 VFCVectorECMVFCid44 "Crash";
CM_ SG_ 1347 VFCVectorECMVFCid45 "GlobalShortDuration";
CM_ SG_ 1347 VFCVectorECMVFCid46 "Hazard";
CM_ SG_ 1347 VFCVectorECMVFCid47 "Reserved";
CM_ SG_ 1347 VFCVectorECMVFCid48 "DoorOpenWarning";
CM_ SG_ 1347 VFCVectorECMVFCid49 "ChargingInit";
CM_ SG_ 1347 VFCVectorECMVFCid5 "Reserved";
CM_ SG_ 1347 VFCVectorECMVFCid50 "Reserved";
CM_ SG_ 1347 VFCVectorECMVFCid51 "Reserved";
CM_ SG_ 1347 VFCVectorECMVFCid52 "ThermalRunaway";
CM_ SG_ 1347 VFCVectorECMVFCid53 "Reserved";
CM_ SG_ 1347 VFCVectorECMVFCid54 "Reserved";
CM_ SG_ 1347 VFCVectorECMVFCid55 "Reserved";
CM_ SG_ 1347 VFCVectorECMVFCid56 "Reserved";
CM_ SG_ 1347 VFCVectorECMVFCid57 "Reserved";
CM_ SG_ 1347 VFCVectorECMVFCid58 "Reserved";
CM_ SG_ 1347 VFCVectorECMVFCid59 "Reserved";
CM_ SG_ 1347 VFCVectorECMVFCid6 "UserInputSettings";
CM_ SG_ 1347 VFCVectorECMVFCid60 "Reserved";
CM_ SG_ 1347 VFCVectorECMVFCid61 "Reserved";
CM_ SG_ 1347 VFCVectorECMVFCid7 "Reserved";
CM_ SG_ 1347 VFCVectorECMVFCid8 "VehicleAPI";
CM_ SG_ 1347 VFCVectorECMVFCid9 "IPWakeup";
CM_ SG_ 401 IsgEngSpdOfActvDampg "Engine speed target for ISG damping function.";
CM_ SG_ 401 IsgTqAllwdChks "Checksum for IsgTqAllwd";
CM_ SG_ 401 IsgTqAllwdCntr "Counter for IsgTqAllwd";
CM_ SG_ 401 IsgTqAllwdIsgTqAllwd "Indication if ISG is allowed to apply propulsive or regenerative torque on wheels.";
CM_ SG_ 401 WhlMotSysActvDampgModReq "ERAD active damping mod request.";
CM_ SG_ 401 WhlMotSysPwrLimMin "Minimum electric motor powerlimit on DC side. Positive power means power flowing into inverter. ";
CM_ SG_ 649 EngOnReq "request to start engine on";
CM_ SG_ 649 HvBattChrgnEgyCnsAllwd1 "How much available energy is available for charging. Estimated available energy from wall socket.";
CM_ SG_ 649 HvBattChrgnILim "Charging current limit value to OBC";
CM_ SG_ 649 HvBattCoolgEgyCnsAllwd1 "How much available energy is available for battery cooling. Estimated available energy from wall socket or Hv battery.";
CM_ SG_ 649 RadFanCoolgSts "Status of radiator fan  ";
CM_ SG_ 309 DrvrGearShiftManReqDwnDwnTipReq "Driver tip request from gear shifter or steering wheel for gear selection. Valid for Shift-By-Wire system. Tip down down request";
CM_ SG_ 309 DrvrGearShiftManReqDwnTipReq "Driver tip request from gear shifter or steering wheel for gear selection. Valid for Shift-By-Wire system. Tip down request";
CM_ SG_ 309 DrvrGearShiftManReqSteerWhlDwnReq1 "Driver tip request from gear shifter or steering wheel for gear selection. Valid for Shift-By-Wire system. Paddle down request";
CM_ SG_ 309 DrvrGearShiftManReqSteerWhlUpReq "Driver tip request from gear shifter or steering wheel for gear selection. Valid for Shift-By-Wire system. Paddle up request";
CM_ SG_ 309 DrvrGearShiftManReqTipReq1 "Driver tip request from gear shifter or steering wheel for gear selection. Valid for Shift-By-Wire system. Tip request";
CM_ SG_ 309 DrvrGearShiftManReqUpTipReq1 "Driver tip request from gear shifter or steering wheel for gear selection. Valid for Shift-By-Wire system. Tip up request";
CM_ SG_ 309 DrvrGearShiftManReqUpUpTipReq "Driver tip request from gear shifter or steering wheel for gear selection. Valid for Shift-By-Wire system. Tip up up request";
CM_ SG_ 309 DrvrGearShiftParkReq1 "Driver park request from gear shifter. Valid for Shift-By-Wire system.";
CM_ SG_ 309 DrvrGearShiftParkReqChks "Driver park request from gear shifter. Valid for Shift-By-Wire system.Checksum";
CM_ SG_ 309 DrvrGearShiftParkReqCntr "Driver park request from gear shifter. Valid for Shift-By-Wire system.Counter";
CM_ SG_ 309 DrvrGearShiftParkReqSts "Driver park request from gear shifter. Valid for Shift-By-Wire system.Status";
CM_ SG_ 309 GearLock "When GearLock is in Active status, driver can chang gear.";
CM_ SG_ 309 GearShiftUnitSts "Signal is used to inform ECM of fault status of EGSM in Shift-by-wire koncept vehicles.";
CM_ SG_ 310 DrvrGearShiftDirReq1Chks "8 bit checksum";
CM_ SG_ 310 DrvrGearShiftDirReq1Cntr "4 bit counter used in checksum calculation. N=E (modulo 16)";
CM_ SG_ 310 DrvrGearShiftDirReq1DwnDwnTipAut "Gear shifter downdown tip in automatic gate";
CM_ SG_ 310 DrvrGearShiftDirReq1DwnTipAut "Gear shifter down tip in automatic gate";
CM_ SG_ 310 DrvrGearShiftDirReq1PosnAut "Gear shifter in automatic gate position";
CM_ SG_ 310 DrvrGearShiftDirReq1UpTipAut "Gear shifter up tip in automatic gate";
CM_ SG_ 310 DrvrGearShiftDirReq1UpUpTipAut "Gear shifter upup tip in automatic gate";
CM_ SG_ 310 DrvrGearShiftDirReq2Chks "8 bit checksum";
CM_ SG_ 310 DrvrGearShiftDirReq2Cntr "4 bit counter used in checksum calculation. N=E (modulo 16)";
CM_ SG_ 310 DrvrGearShiftDirReq2DwnDwnTipAut "Gear shifter downdown tip in automatic gate";
CM_ SG_ 310 DrvrGearShiftDirReq2DwnTipAut "Gear shifter down tip in automatic gate";
CM_ SG_ 310 DrvrGearShiftDirReq2PosnAut "Gear shifter in automatic gate position";
CM_ SG_ 310 DrvrGearShiftDirReq2UpTipAut "Gear shifter up tip in automatic gate";
CM_ SG_ 310 DrvrGearShiftDirReq2UpUpTipAut "Gear shifter upup tip in automatic gate";
CM_ SG_ 1349 VFCVectorEGSMBlockID "Block Identifier";
CM_ SG_ 1349 VFCVectorEGSMVFCid0 "AdjustableDriveControls";
CM_ SG_ 1349 VFCVectorEGSMVFCid1 "ParkingDrivingClimatization";
CM_ SG_ 1349 VFCVectorEGSMVFCid10 "ExteriorLighting";
CM_ SG_ 1349 VFCVectorEGSMVFCid11 "Reserved";
CM_ SG_ 1349 VFCVectorEGSMVFCid12 "Alarm";
CM_ SG_ 1349 VFCVectorEGSMVFCid13 "Reserved";
CM_ SG_ 1349 VFCVectorEGSMVFCid14 "InteriorLighting";
CM_ SG_ 1349 VFCVectorEGSMVFCid15 "InteriorLightingEntrance";
CM_ SG_ 1349 VFCVectorEGSMVFCid16 "Locking";
CM_ SG_ 1349 VFCVectorEGSMVFCid17 "RemoteKey";
CM_ SG_ 1349 VFCVectorEGSMVFCid18 "PropulsionStart";
CM_ SG_ 1349 VFCVectorEGSMVFCid19 "PassiveSafetyAndRestraints";
CM_ SG_ 1349 VFCVectorEGSMVFCid2 "PostClimatisation";
CM_ SG_ 1349 VFCVectorEGSMVFCid20 "Reserved";
CM_ SG_ 1349 VFCVectorEGSMVFCid21 "PowerOperatedTailgate";
CM_ SG_ 1349 VFCVectorEGSMVFCid22 "VehicleDriving";
CM_ SG_ 1349 VFCVectorEGSMVFCid23 "Reserved";
CM_ SG_ 1349 VFCVectorEGSMVFCid24 "UserProfileInput";
CM_ SG_ 1349 VFCVectorEGSMVFCid25 "SeatComfortFunctions";
CM_ SG_ 1349 VFCVectorEGSMVFCid26 "Brake";
CM_ SG_ 1349 VFCVectorEGSMVFCid27 "InformationPoll";
CM_ SG_ 1349 VFCVectorEGSMVFCid28 "HVEnergyStorage";
CM_ SG_ 1349 VFCVectorEGSMVFCid29 "Reserved";
CM_ SG_ 1349 VFCVectorEGSMVFCid3 "PowertrainParkingClimatization";
CM_ SG_ 1349 VFCVectorEGSMVFCid30 "TelematicsConnectivity";
CM_ SG_ 1349 VFCVectorEGSMVFCid31 "Reserved";
CM_ SG_ 1349 VFCVectorEGSMVFCid32 "Entertainment";
CM_ SG_ 1349 VFCVectorEGSMVFCid33 "Diagnostics";
CM_ SG_ 1349 VFCVectorEGSMVFCid34 "AllECUs";
CM_ SG_ 1349 VFCVectorEGSMVFCid35 "TrailerCaravanFunctions";
CM_ SG_ 1349 VFCVectorEGSMVFCid36 "Immobilizer";
CM_ SG_ 1349 VFCVectorEGSMVFCid37 "Windows";
CM_ SG_ 1349 VFCVectorEGSMVFCid38 "Visibility";
CM_ SG_ 1349 VFCVectorEGSMVFCid39 "WarningSounds";
CM_ SG_ 1349 VFCVectorEGSMVFCid4 "Reserved";
CM_ SG_ 1349 VFCVectorEGSMVFCid40 "Entrance";
CM_ SG_ 1349 VFCVectorEGSMVFCid41 "InfotainmentPush";
CM_ SG_ 1349 VFCVectorEGSMVFCid42 "ChargingHV";
CM_ SG_ 1349 VFCVectorEGSMVFCid43 "BodyPreClimatisation";
CM_ SG_ 1349 VFCVectorEGSMVFCid44 "Crash";
CM_ SG_ 1349 VFCVectorEGSMVFCid45 "GlobalShortDuration";
CM_ SG_ 1349 VFCVectorEGSMVFCid46 "Hazard";
CM_ SG_ 1349 VFCVectorEGSMVFCid47 "Reserved";
CM_ SG_ 1349 VFCVectorEGSMVFCid48 "DoorOpenWarning";
CM_ SG_ 1349 VFCVectorEGSMVFCid49 "ChargingInit";
CM_ SG_ 1349 VFCVectorEGSMVFCid5 "Reserved";
CM_ SG_ 1349 VFCVectorEGSMVFCid50 "Reserved";
CM_ SG_ 1349 VFCVectorEGSMVFCid51 "Reserved";
CM_ SG_ 1349 VFCVectorEGSMVFCid52 "ThermalRunaway";
CM_ SG_ 1349 VFCVectorEGSMVFCid53 "Reserved";
CM_ SG_ 1349 VFCVectorEGSMVFCid54 "Reserved";
CM_ SG_ 1349 VFCVectorEGSMVFCid55 "Reserved";
CM_ SG_ 1349 VFCVectorEGSMVFCid56 "Reserved";
CM_ SG_ 1349 VFCVectorEGSMVFCid57 "Reserved";
CM_ SG_ 1349 VFCVectorEGSMVFCid58 "Reserved";
CM_ SG_ 1349 VFCVectorEGSMVFCid59 "Reserved";
CM_ SG_ 1349 VFCVectorEGSMVFCid6 "UserInputSettings";
CM_ SG_ 1349 VFCVectorEGSMVFCid60 "Reserved";
CM_ SG_ 1349 VFCVectorEGSMVFCid61 "Reserved";
CM_ SG_ 1349 VFCVectorEGSMVFCid7 "Reserved";
CM_ SG_ 1349 VFCVectorEGSMVFCid8 "VehicleAPI";
CM_ SG_ 1349 VFCVectorEGSMVFCid9 "IPWakeup";
CM_ SG_ 801 ComLostExtrSoundFront "ComLostExtrSoundFront";
CM_ SG_ 1479 MVBMdevelpsignalgroupreqFunctiondevpsignalgroup1 "develop signal group request";
CM_ SG_ 1479 MVBMdevelpsignalgroupreqFunctiondevpsignalgroup2 "develop signal group request";
CM_ SG_ 1479 MVBMdevelpsignalgroupreqFunctiondevpsignalgroup3 "develop signal group request";
CM_ SG_ 1479 MVBMdevelpsignalgroupreqFunctiondevpsignalgroup4 "develop signal group request";
CM_ SG_ 1479 MVBMdevelpsignalgroupreqFunctiondevpsignalgroup5 "develop signal group request";
CM_ SG_ 1479 MVBMdevelpsignalgroupreqFunctiondevpsignalgroup6 "develop signal group request";
CM_ SG_ 1479 MVBMdevelpsignalgroupreqFunctiondevpsignalgroup7 "develop signal group request";
CM_ SG_ 1479 MVBMdevelpsignalgroupreqFunctiondevpsignalgroup8 "develop signal group request";
CM_ SG_ 1462 MVCMdevelpsignalgroupreqFunctiondevpsignalgroup1 "develop signal group request";
CM_ SG_ 1462 MVCMdevelpsignalgroupreqFunctiondevpsignalgroup2 "develop signal group request";
CM_ SG_ 1462 MVCMdevelpsignalgroupreqFunctiondevpsignalgroup3 "develop signal group request";
CM_ SG_ 1462 MVCMdevelpsignalgroupreqFunctiondevpsignalgroup4 "develop signal group request";
CM_ SG_ 1462 MVCMdevelpsignalgroupreqFunctiondevpsignalgroup5 "develop signal group request";
CM_ SG_ 1462 MVCMdevelpsignalgroupreqFunctiondevpsignalgroup6 "develop signal group request";
CM_ SG_ 1462 MVCMdevelpsignalgroupreqFunctiondevpsignalgroup7 "develop signal group request";
CM_ SG_ 1462 MVCMdevelpsignalgroupreqFunctiondevpsignalgroup8 "develop signal group request";
CM_ SG_ 1430 OBCdevelpsignalgroupreqFunctiondevpsignalgroup1 "develop signal group request";
CM_ SG_ 1430 OBCdevelpsignalgroupreqFunctiondevpsignalgroup2 "develop signal group request";
CM_ SG_ 1430 OBCdevelpsignalgroupreqFunctiondevpsignalgroup3 "develop signal group request";
CM_ SG_ 1430 OBCdevelpsignalgroupreqFunctiondevpsignalgroup4 "develop signal group request";
CM_ SG_ 1430 OBCdevelpsignalgroupreqFunctiondevpsignalgroup5 "develop signal group request";
CM_ SG_ 1430 OBCdevelpsignalgroupreqFunctiondevpsignalgroup6 "develop signal group request";
CM_ SG_ 1430 OBCdevelpsignalgroupreqFunctiondevpsignalgroup7 "develop signal group request";
CM_ SG_ 1430 OBCdevelpsignalgroupreqFunctiondevpsignalgroup8 "develop signal group request";
CM_ SG_ 1415 DftlDevCtrl0 "Debug signals for development purposes.";
CM_ SG_ 1415 DftlDevCtrl1 "Debug signals for development purposes.";
CM_ SG_ 1415 DftlDevCtrl2 "Debug signals for development purposes.";
CM_ SG_ 1415 DftlDevCtrl3 "Debug signals for development purposes.";
CM_ SG_ 1415 DftlDevCtrl4 "Debug signals for development purposes.";
CM_ SG_ 1415 DftlDevCtrl5 "Debug signals for development purposes.";
CM_ SG_ 1415 DftlDevCtrl6 "Debug signals for development purposes.";
CM_ SG_ 1415 DftlDevCtrl7 "Debug signals for development purposes.";
CM_ SG_ 1457 SRSdevelpsignalgroupRXFunctiondevpsignalgroup1 "SRS development signal";
CM_ SG_ 1457 SRSdevelpsignalgroupRXFunctiondevpsignalgroup2 "SRS development signal";
CM_ SG_ 1457 SRSdevelpsignalgroupRXFunctiondevpsignalgroup3 "SRS development signal";
CM_ SG_ 1457 SRSdevelpsignalgroupRXFunctiondevpsignalgroup4 "SRS development signal";
CM_ SG_ 1457 SRSdevelpsignalgroupRXFunctiondevpsignalgroup5 "SRS development signal";
CM_ SG_ 1457 SRSdevelpsignalgroupRXFunctiondevpsignalgroup6 "SRS development signal";
CM_ SG_ 1457 SRSdevelpsignalgroupRXFunctiondevpsignalgroup7 "SRS development signal";
CM_ SG_ 1457 SRSdevelpsignalgroupRXFunctiondevpsignalgroup8 "SRS development signal";
CM_ SG_ 1513 VDDMPropCANInternalDevReqMesgFunctiondevpsignalgroup1 "develop signal group requirement";
CM_ SG_ 1513 VDDMPropCANInternalDevReqMesgFunctiondevpsignalgroup2 "develop signal group requirement";
CM_ SG_ 1513 VDDMPropCANInternalDevReqMesgFunctiondevpsignalgroup3 "develop signal group requirement";
CM_ SG_ 1513 VDDMPropCANInternalDevReqMesgFunctiondevpsignalgroup4 "develop signal group requirement";
CM_ SG_ 1513 VDDMPropCANInternalDevReqMesgFunctiondevpsignalgroup5 "develop signal group requirement";
CM_ SG_ 1513 VDDMPropCANInternalDevReqMesgFunctiondevpsignalgroup6 "develop signal group requirement";
CM_ SG_ 1513 VDDMPropCANInternalDevReqMesgFunctiondevpsignalgroup7 "develop signal group requirement";
CM_ SG_ 1513 VDDMPropCANInternalDevReqMesgFunctiondevpsignalgroup8 "develop signal group requirement";
CM_ SG_ 76 WhlMotSysModSts "Reflects the current operating mode of the IEM.";
CM_ SG_ 76 WhlMotSysTqAvlTqAvlMax "Max available torque";
CM_ SG_ 76 WhlMotSysTqAvlTqAvlMin "Min available torque";
CM_ SG_ 76 WhlMotSysTqEstChks "Checksum of estimation torque";
CM_ SG_ 76 WhlMotSysTqEstCntr "Counter of estimation torque";
CM_ SG_ 76 WhlMotSysTqEstIsgTqAct "Estimation torque of Rear Axle Control";
CM_ SG_ 76 WhlMotSysTqEstQualityFactor "Quality factor of estimation torque";
CM_ SG_ 96 ImobEngSts2 "IEM CEM message immo status. Can be undefined, immobilised, motive mobilised or non motive mobilised.";
CM_ SG_ 96 WhlMotSysCooltT "Measured coolant temperature in rear axle inverter in degC";
CM_ SG_ 96 WhlMotSysLimnIndcn "The limitation indication of derating conditions";
CM_ SG_ 96 WhlMotSysSpdAct "The actual rotational speed of rear motor";
CM_ SG_ 96 WhlMotSysUdc "The DC voltage of rear motor";
CM_ SG_ 1111 IEMTestFr1Byte0 "DTC1 status
";
CM_ SG_ 1111 IEMTestFr1Byte1 "DTC1 low byte";
CM_ SG_ 1111 IEMTestFr1Byte2 "DTC1 middle byte";
CM_ SG_ 1111 IEMTestFr1Byte3 "DTC1 high byte
";
CM_ SG_ 1111 IEMTestFr1Byte4 "DTC2 status";
CM_ SG_ 1111 IEMTestFr1Byte5 "DTC2 low byte";
CM_ SG_ 1111 IEMTestFr1Byte6 "DTC2 middle byte";
CM_ SG_ 1111 IEMTestFr1Byte7 "DTC2 high byte";
CM_ SG_ 1125 IEMTestFr2Byte0 "DTC1 status";
CM_ SG_ 1125 IEMTestFr2Byte1 "DTC1 low byte
";
CM_ SG_ 1125 IEMTestFr2Byte2 "DTC1 middle byte";
CM_ SG_ 1125 IEMTestFr2Byte3 "DTC1 high byte";
CM_ SG_ 1125 IEMTestFr2Byte4 "DTC2 status";
CM_ SG_ 1125 IEMTestFr2Byte5 "DTC2 low byte
";
CM_ SG_ 1125 IEMTestFr2Byte6 "DTC2 middle byte";
CM_ SG_ 1125 IEMTestFr2Byte7 "DTC2 high byte";
CM_ SG_ 773 WhlMotClrRdyReq "WhlMotClrRdyReq";
CM_ SG_ 773 WhlMotSysCoolgReq "Signal to request increased cooling to Erad and IEM.Request is in 3 steps of increased cooling.";
CM_ SG_ 773 WhlMotSysErrIndcnReq "WhlMotSysErrIndcnReq";
CM_ SG_ 773 WhlMotSysInvrT "The inverter temperature measured in the IEM.";
CM_ SG_ 773 WhlMotSysMotT "The temperature of motor";
CM_ SG_ 613 ImobEngChk2ImobEngChkSts "Message from IEM to CEM that challenge is available and 7 bytes of challenge. Message to CEM Challenge available";
CM_ SG_ 613 ImobEngChk2ImobEngDataChk0 "Message from IEM to CEM that challenge is available and 7 bytes of challenge. Byte 0";
CM_ SG_ 613 ImobEngChk2ImobEngDataChk1 "Message from IEM to CEM that challenge is available and 7 bytes of challenge. Byte 1";
CM_ SG_ 613 ImobEngChk2ImobEngDataChk2 "Message from IEM to CEM that challenge is available and 7 bytes of challenge. Byte 2";
CM_ SG_ 613 ImobEngChk2ImobEngDataChk3 "Message from IEM to CEM that challenge is available and 7 bytes of challenge. Byte 3";
CM_ SG_ 613 ImobEngChk2ImobEngDataChk4 "Message from IEM to CEM that challenge is available and 7 bytes of challenge. Byte 4";
CM_ SG_ 613 ImobEngChk2ImobEngDataChk5 "Message from IEM to CEM that challenge is available and 7 bytes of challenge. Byte 5";
CM_ SG_ 613 ImobEngChk2ImobEngDataChk6 "Message from IEM to CEM that challenge is available and 7 bytes of challenge. Byte 6";
CM_ SG_ 626 IemGenericADAlrmSt "Active Discharge fault alarm status";
CM_ SG_ 626 IemGenericDTCHig "DTC high byte for non OBD or OBD";
CM_ SG_ 626 IemGenericDTCLow "DTC low byte for non OBD";
CM_ SG_ 626 IemGenericDTCMid "DTC middle byte for non OBD DTC low byte for OBD";
CM_ SG_ 626 IemGenericDTCSts "DTC Status";
CM_ SG_ 626 IemGenericEMQnty "Quantity of electric motor";
CM_ SG_ 626 IemGenericEMSeqNr "Sequence number of electric motor";
CM_ SG_ 626 IemGenericFltAlrmSt "Fault alarm status";
CM_ SG_ 626 IemGenericIacAlrmSt "3 Phase current alarm status";
CM_ SG_ 626 IemGenericInvrtTAlrmSt "Inverter temperature alarm status";
CM_ SG_ 626 IemGenericModStatusRms "Motor status for RMS monitor";
CM_ SG_ 626 IemGenericMotTAlrmSt "Motor temperature alarm status";
CM_ SG_ 626 IemGenericResd1 "Reserved for future use";
CM_ SG_ 626 IemGenericRslAlrmSt "Resolver fault alarm status";
CM_ SG_ 626 IemGenericSpdAlrmSt "Over speed alarm status";
CM_ SG_ 626 IemGenericUDcAlrmSt "High voltage alarm status";
CM_ SG_ 643 WhlMotCooltFlowMinReq "Minimum coolant flow required by rear wheel motor";
CM_ SG_ 643 WhlMotNetIntlHeatg "Net internal heating for rear wheel motor";
CM_ SG_ 643 WhlMotThermPwrMaxReq "Maximum heat transfer from component to coolant requested by rear wheel motor(Negative for heating)";
CM_ SG_ 643 WhlMotThermPwrMinReq "Minimum heat transfer from component to coolant requested by rear wheel motor(Negative for heating)";
CM_ SG_ 99 WhlMotSysIdc "DC current measured in the IEM.";
CM_ SG_ 629 IsgClrRdyReq "IGM Readiness Clear Signal";
CM_ SG_ 629 IsgCoolgReqInvr "Request for increased cooling flow to Inverter";
CM_ SG_ 629 IsgCooltFlowMinReq "Minimum coolant flow required by ISG";
CM_ SG_ 629 IsgInvrT "Temperature of the inverter";
CM_ SG_ 629 IsgNetIntlHeatg "Net internal heating for ISG";
CM_ SG_ 629 IsgThermPwrMaxReq "Maximum heat transfer from component to coolant requested by ISG. (Negative for heating)";
CM_ SG_ 629 IsgThermPwrMinReq "Minimum heat transfer from component to coolant requested by ISG. (Negative for heating)";
CM_ SG_ 314 IsgCooltT "Measured coolant temperature in inverter in degC";
CM_ SG_ 314 IsgIDc "DC current measured by the front inverter";
CM_ SG_ 314 IsgMotT "Temperature of the CISG";
CM_ SG_ 314 IsgTqAvlMax "Max available torque";
CM_ SG_ 314 IsgTqAvlMin "Min available torque";
CM_ SG_ 625 ImobEngChk3ImobEngChkSts "Message from IGM to CEM that challenge is available and 7 bytes of challenge. Message to CEM Challenge available";
CM_ SG_ 625 ImobEngChk3ImobEngDataChk0 "Message from IGM to CEM that challenge is available and 7 bytes of challenge. Byte 0";
CM_ SG_ 625 ImobEngChk3ImobEngDataChk1 "Message from IGM to CEM that challenge is available and 7 bytes of challenge. Byte 1";
CM_ SG_ 625 ImobEngChk3ImobEngDataChk2 "Message from IGM to CEM that challenge is available and 7 bytes of challenge. Byte 2";
CM_ SG_ 625 ImobEngChk3ImobEngDataChk3 "Message from IGM to CEM that challenge is available and 7 bytes of challenge. Byte 3";
CM_ SG_ 625 ImobEngChk3ImobEngDataChk4 "Message from IGM to CEM that challenge is available and 7 bytes of challenge. Byte 4";
CM_ SG_ 625 ImobEngChk3ImobEngDataChk5 "Message from IGM to CEM that challenge is available and 7 bytes of challenge. Byte 5";
CM_ SG_ 625 ImobEngChk3ImobEngDataChk6 "Message from IGM to CEM that challenge is available and 7 bytes of challenge. Byte 6";
CM_ SG_ 625 ImobEngSts3 "IGM CEM message immo status. Undefined, immobilised, motive mobilised or non motive mobilised.";
CM_ SG_ 342 IsgLimnIndcn "LOS signal";
CM_ SG_ 342 IsgUDc "HVDC voltage";
CM_ SG_ 149 IsgModSts "Inverter mode status";
CM_ SG_ 149 IsgSpdActSgn "Actual ISG speed with sign to indicate forward or backward direction";
CM_ SG_ 149 IsgTqActChks "Checksum";
CM_ SG_ 149 IsgTqActCntr "Counter";
CM_ SG_ 149 IsgTqActIsgTqAct "Actual torque";
CM_ SG_ 149 IsgTqActQualityFactor "Quality factor";
CM_ SG_ 627 IgmGenericADAlrmSt "Active Discharge fault alarm status";
CM_ SG_ 627 IgmGenericDTCHig "DTC high byte for non OBD or OBD";
CM_ SG_ 627 IgmGenericDTCLow "DTC low byte for non OBD";
CM_ SG_ 627 IgmGenericDTCMid "DTC middle byte for non OBD DTC low byte for OBD";
CM_ SG_ 627 IgmGenericDTCSts "DTC Status";
CM_ SG_ 627 IgmGenericEMQnty "Quantity of electric motor";
CM_ SG_ 627 IgmGenericEMSeqNr "Sequence number of electric motor";
CM_ SG_ 627 IgmGenericFltAlrmSt "Fault alarm status";
CM_ SG_ 627 IgmGenericIacAlrmSt "3 Phase current alarm status";
CM_ SG_ 627 IgmGenericInvrtTAlrmSt "Inverter temperature alarm status";
CM_ SG_ 627 IgmGenericModStatusRms "Motor status for RMS monitor";
CM_ SG_ 627 IgmGenericMotTAlrmSt "Motor temperature alarm status";
CM_ SG_ 627 IgmGenericResd1 "Reserved for future use";
CM_ SG_ 627 IgmGenericRslAlrmSt "Resolver fault alarm status";
CM_ SG_ 627 IgmGenericSpdAlrmSt "Over speed alarm status";
CM_ SG_ 627 IgmGenericUDcAlrmSt "High voltage alarm status";
CM_ SG_ 660 IsgErrIndcnReq "MIL ilumination req from IGM";
CM_ SG_ 660 IsgMotCooltFlowReq "Flow request for coolant to the CISG";
CM_ SG_ 660 IsgMotCooltTFlg "Request for lower coolant temperature for the CISG";
CM_ SG_ 1127 IGMTestFr1Byte0 "DTC1 status";
CM_ SG_ 1127 IGMTestFr1Byte1 "DTC1 low byte
";
CM_ SG_ 1127 IGMTestFr1Byte2 "DTC1 middle byte";
CM_ SG_ 1127 IGMTestFr1Byte3 "DTC1 high byte";
CM_ SG_ 1127 IGMTestFr1Byte4 "DTC2 status";
CM_ SG_ 1127 IGMTestFr1Byte5 "DTC2 low byte";
CM_ SG_ 1127 IGMTestFr1Byte6 "DTC2 middle byte";
CM_ SG_ 1127 IGMTestFr1Byte7 "DTC2 high byte";
CM_ SG_ 1129 IGMTestFr2Byte0 "DTC1 status";
CM_ SG_ 1129 IGMTestFr2Byte1 "DTC1 low byte
";
CM_ SG_ 1129 IGMTestFr2Byte2 "DTC1 middle byte";
CM_ SG_ 1129 IGMTestFr2Byte3 "DTC1 high byte";
CM_ SG_ 1129 IGMTestFr2Byte4 "DTC2 status";
CM_ SG_ 1129 IGMTestFr2Byte5 "DTC2 low byte";
CM_ SG_ 1129 IGMTestFr2Byte6 "DTC2 middle byte";
CM_ SG_ 1129 IGMTestFr2Byte7 "DTC2 high byte";
CM_ SG_ 90 MvIsgIDc "Continuous side current during Machine Mode";
CM_ SG_ 90 MvIsgTqAvlIsgTqAvlMax "Potential reachable positive torque during permanent mode";
CM_ SG_ 90 MvIsgTqAvlIsgTqAvlMin "Potential reachable negnative torque during permanent mode";
CM_ SG_ 90 MvIsgTqNegAvlTra "Potential reachable peak torque during operational mode";
CM_ SG_ 90 MvIsgTqPosAvlTra "Potential reachable peak torque during operational mode";
CM_ SG_ 90 MvIsgTRate "IBSG Temperature Rate";
CM_ SG_ 90 MvIsgUDc "+BAT48V terminal voltage";
CM_ SG_ 358 MvIsgLimnIndcn "Bit 0: MvIsgFltLvl1,Bit 1: MvIsgFltLvl2,Bit 2: MvIsgFltLvl3,Bit 3: Reserved,Bit 4: MvIsgPwrLimn,Bit 5: MvIsgMILReq,Bit 6: MvIsgSVSReq";
CM_ SG_ 358 MvIsgModSts "Machine Mode status";
CM_ SG_ 358 MvIsgRstrtSts "IBSG status for restart need";
CM_ SG_ 358 MvIsgSpdAct "Machine rotor speed measure";
CM_ SG_ 358 MvIsgTqActMvIsgTq "Estimated torque during machine mode";
CM_ SG_ 358 MvIsgTqActMvIsgTqChks "Chks";
CM_ SG_ 358 MvIsgTqActMvIsgTqCntr "Cntr";
CM_ SG_ 358 MvIsgTqActQualityFactor "QualityFactor";
CM_ SG_ 897 MvIsgFltState1MvIsgIvtrThermProtn "ISGM fault states 1 Inverter thermal protection during cranking phase (stalled rotor)";
CM_ SG_ 897 MvIsgFltState1MvIsgLoadDump "ISGM fault states 1 LOADDUMP detection on plus BAT48V";
CM_ SG_ 897 MvIsgFltState1MvIsgNegSpdDetn "ISGM fault states 1 Negative speed detection in during a start attempt";
CM_ SG_ 897 MvIsgFltState1MvIsgOvrheatg "ISGM fault states 1 Thermal overheating protection Flag for stator, rotor, Power module, Control Board and Excitation board";
CM_ SG_ 897 MvIsgFltState1MvIsgPwrLimn "ISGM fault states 1 Output Power Derating due to temperature";
CM_ SG_ 897 MvIsgFltState1MvIsgStrtrModWarn "ISGM fault states 1 Starter mode warning detection due to high temperature";
CM_ SG_ 897 MvIsgFltState1MvIsgULo "ISGM fault states 1 Too low voltage detection on plus BAT48V detection";
CM_ SG_ 897 MvIsgFltState1MvIsgUOvld "ISGM fault states 1 Too high voltage detection on plus BAT48V detection";
CM_ SG_ 897 MvIsgFltState2MvIsgBrushWearUDrpFlt "ISGM falt states 2 Too high brush wear voltage drop detection";
CM_ SG_ 897 MvIsgFltState2MvIsgCanFlt "ISGM falt states 2 CAN fault detection";
CM_ SG_ 897 MvIsgFltState2MvIsgExctCircHiSideFlt "ISGM falt states 2 Excitation circuit High side mosfet failure detection";
CM_ SG_ 897 MvIsgFltState2MvIsgIOvld "ISGM fault state2 functional phase over current detection";
CM_ SG_ 897 MvIsgFltState2MvIsgPwrModuleIvtrFlt "ISGM falt states 2 Power module internal failure(Phase opencircuit)";
CM_ SG_ 897 MvIsgFltState2MvIsgPwrModuleStrtrFlt "ISGM falt states 2 Power module internal failure (Stator short-circuit to GND or B plus)";
CM_ SG_ 897 MvIsgFltState2MvIsgRotorIOvld "ISGM falt states 2 Rotor over current detection in functional mode";
CM_ SG_ 897 MvIsgFltState2MvIsgTqLvlFlt "ISGM falt states 2 Unexpected torque level detection";
CM_ SG_ 897 MvIsgFltState3BattUHi "ISGM fault states 3 12V network high voltage detection";
CM_ SG_ 897 MvIsgFltState3BattULo "ISGM fault states 3 12V network low voltage detection";
CM_ SG_ 897 MvIsgFltState3MvIsg48vVSClOc "ISGM fault states 3 48V voltage sensor circuit low/open circuit";
CM_ SG_ 897 MvIsgFltState3MvIsgExctCircLatentFlt "ISGM fault states 3 Excitation circuit DMAG mosfet failure detection";
CM_ SG_ 897 MvIsgFltState3MvIsgRotorOpenCircFlt "ISGM fault states 3 Rotor open circuit detection";
CM_ SG_ 897 MvIsgFltState3MvIsgRPSCh "ISGM fault states 3 Rotor position sensor circuit high";
CM_ SG_ 897 MvIsgFltState3MvIsgRPSClOc "ISGM fault states 3 Rotor position sensor circuit low/open circuit";
CM_ SG_ 897 MvIsgFltState3MvIsgRvsSpdFlt "ISGM fault states 3 Reverse rotation protection";
CM_ SG_ 897 MvIsgFltState4MvIsg48vVSCh "ISGM fault states 4 48V voltage sensor circuit high";
CM_ SG_ 897 MvIsgFltState4MvIsgECSCh "ISGM fault states 4 Exitation current sensor circuit high";
CM_ SG_ 897 MvIsgFltState4MvIsgECSClOc "ISGM fault states 4 Exitation current sensor circuit low/open circuit";
CM_ SG_ 897 MvIsgFltState4MvIsgPCSCl "ISGM fault states 4 Exitation current sensor circuit low/open circuit";
CM_ SG_ 897 MvIsgFltState4MvIsgPCSOc "ISGM fault states 4 Excitation current sensor circuit low/open circuit";
CM_ SG_ 897 MvIsgFltState4MvIsgTECl "ISGM fault states 4 Temperature sensor of excitation circuit low";
CM_ SG_ 897 MvIsgFltState4MvIsgTPCBChOc "ISGM fault states 4 Temperature sensor of PCB circuit high/open circuit";
CM_ SG_ 897 MvIsgFltState4MvIsgTPCBCl "ISGM fault states 4 Temperature sensor of PCB circuit low";
CM_ SG_ 897 MvIsgFltState5MvIsgPMSClCh "ISGM fault states 5 Power module sensor circuit low/high";
CM_ SG_ 897 MvIsgFltState5MvIsgPMSOc "ISGM fault states 5 Power module sensor circuit low";
CM_ SG_ 897 MvIsgFltState5MvIsgRotorPosnTrackingLoopFlt "ISGM fault states 5 Rotor Position Tracking Loop not correctly locked";
CM_ SG_ 897 MvIsgFltState5MvIsgRPSOc "Rotor position sensor open circuit fault";
CM_ SG_ 897 MvIsgFltState5MvIsgTEChOc "ISGM fault states 5 Temperature sensor of excitation  circuit high/open circuit";
CM_ SG_ 1478 MVBMdevelpsignalgrouprespFunctiondevpsignalgroup1 "develop signal group response";
CM_ SG_ 1478 MVBMdevelpsignalgrouprespFunctiondevpsignalgroup2 "develop signal group response";
CM_ SG_ 1478 MVBMdevelpsignalgrouprespFunctiondevpsignalgroup3 "develop signal group response";
CM_ SG_ 1478 MVBMdevelpsignalgrouprespFunctiondevpsignalgroup4 "develop signal group response";
CM_ SG_ 1478 MVBMdevelpsignalgrouprespFunctiondevpsignalgroup5 "develop signal group response";
CM_ SG_ 1478 MVBMdevelpsignalgrouprespFunctiondevpsignalgroup6 "develop signal group response";
CM_ SG_ 1478 MVBMdevelpsignalgrouprespFunctiondevpsignalgroup7 "develop signal group response";
CM_ SG_ 1478 MVBMdevelpsignalgrouprespFunctiondevpsignalgroup8 "develop signal group response";
CM_ SG_ 408 MvBattCellUMax "Maximum cell voltage";
CM_ SG_ 408 MvBattCellUMin "Minimum cell voltage";
CM_ SG_ 408 MvBattLimnIndcnChks "Checksum";
CM_ SG_ 408 MvBattLimnIndcnCntr "Counter";
CM_ SG_ 408 MvBattLimnIndcnMvBattLimnIndcn "Faults in medium voltage battery

Bit 0 Hybrid system fault
Bit 1 SVS
Bit 2 Derating 
Bit 3 Restorability 
Bit 4 Unrestorability
Bit 5Cell hardware OVP fault
Bit 6 MIL Req
Bit 7 Reserved
Bit 8 Reserved
Bit 9 Reserved
Bit 10 Reserved
Bit 11 Reserved
Bit 12 Reserved
Bit 13 Reserved
Bit 14 Reserved
Bit 15 Reserved";
CM_ SG_ 408 MvBattMod "Mode of 48V battery";
CM_ SG_ 630 MvBattPwrLimChrg1 "Maximum charge power available for the next 1 second.";
CM_ SG_ 630 MvBattPwrLimChrg2 "Maximum charge power available for the next 10 second";
CM_ SG_ 630 MvBattPwrLimDcha1 "Maximum charge power available for the next 1 second";
CM_ SG_ 630 MvBattPwrLimDcha2 "Maximum discharge power available for the next 10 second.";
CM_ SG_ 630 MvBattSoc "MV Calculated SOC";
CM_ SG_ 106 MvBattIDc "Measured current in or out of the battery";
CM_ SG_ 106 MvBattRlyStsChks "CheckSum";
CM_ SG_ 106 MvBattRlyStsCntr "Counter";
CM_ SG_ 106 MvBattRlyStsMvBattRlySts "Actual relay position";
CM_ SG_ 106 MvBattUDc "48V battery pack voltage (before the contactor)";
CM_ SG_ 106 MvBattUDc2 "Voltage between the positive and negtive terminals";
CM_ SG_ 584 MvBattFltState1MvBattBccComFlt "BCC (cell voltage sampling MCU) communication fault";
CM_ SG_ 584 MvBattFltState1MvBattBccFlt "BCC (cell voltage measurement MCU) fault";
CM_ SG_ 584 MvBattFltState1MvBattCellOvpFlt "Cell OVP error flag";
CM_ SG_ 584 MvBattFltState1MvBattCellUvpFlt "Cell UVP error flag";
CM_ SG_ 584 MvBattFltState1MvBattComFlt "BMS communication fault with ECU";
CM_ SG_ 584 MvBattFltState1MvBattOcpFlt "Pack OC fault";
CM_ SG_ 584 MvBattFltState1MvBattOvpFlt "Pack OVP error flag";
CM_ SG_ 584 MvBattFltState1MvBattUvpFlt "Pack UVP error flag";
CM_ SG_ 584 MvBattFltState2BattUHi "12V power supply OV";
CM_ SG_ 584 MvBattFltState2BattULo "12V power supply UV";
CM_ SG_ 584 MvBattFltState2MvBattCbClsFlt "CB stuck close fault";
CM_ SG_ 584 MvBattFltState2MvBattCellUSampleFlt "Cell voltage sampling line fault";
CM_ SG_ 584 MvBattFltState2MvBattISampleFlt "Current sampling fault";
CM_ SG_ 584 MvBattFltState2MvBattPrecFail "Percharge fail";
CM_ SG_ 584 MvBattFltState2MvBattTSGND "Battery pack temperature sampling circuit is short to Ground";
CM_ SG_ 584 MvBattFltState2MvBattTSPWR "Battery pack temperature sampling circuit is short to Power";
CM_ SG_ 584 MvBattFltState3MvBattCVSGND "Cell voltage sampling sensor short to ground";
CM_ SG_ 584 MvBattFltState3MvBattCVSOc "Battery Cell Voltage sampling circuit is open";
CM_ SG_ 584 MvBattFltState3MvBattCVSOOR "Battery Cell Voltage sampling is out of range";
CM_ SG_ 584 MvBattFltState3MvBattCVSPWR "Cell voltage sampling sensor short to power";
CM_ SG_ 584 MvBattFltState3MvBattPVSGND "Pack voltage sampling sensor short to ground";
CM_ SG_ 584 MvBattFltState3MvBattPVSOc "Pack Voltage sampling circuit is open";
CM_ SG_ 584 MvBattFltState3MvBattPVSPWR "Pack voltage sampling sensor short to power";
CM_ SG_ 584 MvBattFltState3MvBattTSOOR "Battery pack temperature sample circuit  is out of range";
CM_ SG_ 584 MvBattFltState4MvBattCSGND "Current sampling circuit is short to Ground";
CM_ SG_ 584 MvBattFltState4MvBattCSOc "Current sampling circuit is open";
CM_ SG_ 584 MvBattFltState4MvBattCSOOR "Current sampling is out of range";
CM_ SG_ 584 MvBattFltState4MvBattPVSOOR "Battery Pack Voltage sampling is out of range";
CM_ SG_ 584 MvBattFltState4MvBattTVSGND "48V Terminal Voltage sampling circuit is short to Ground";
CM_ SG_ 584 MvBattFltState4MvBattTVSOOR "48V Terminal Voltage sampling is out of range";
CM_ SG_ 584 MvBattFltState4MvBattTVSPWR "48V Terminal Voltage sampling circuit is short to Power";
CM_ SG_ 1151 MvBattEgyCdn "Battery SOH";
CM_ SG_ 1151 MvBattTAvg "MV battery average temperature";
CM_ SG_ 1151 MvBattTMax "MV battery max temperature";
CM_ SG_ 1151 MvBattTMin "MV battery min temperature";
BA_DEF_ BO_ "GenMsgSendType" ENUM "cyclic", "spontaneous", "not-used", "not-used", "not-used", "cyclicAndSpontaneous", "not-used", "cyclicIfActive", "NoMsgSendType"; // [us]
BA_DEF_ BO_ "GenMsgCycleTime" INT 0 65536; // [ms]
BA_DEF_ BO_ "GenMsgStartDelayTime" INT 0 65536; // [ms]
BA_DEF_ BO_ "GenMsgDelayTime" INT 0 65536; // [ms]
BA_DEF_ SG_ "GenSigSendType" ENUM "Cyclic","OnWrite","OnWriteWithRepetition","OnChange","OnChangeWithRepetition","IfActive","IfActiveWithRepetition","NoSigSendType";
BA_DEF_ SG_ "GenSigStartValue" HEX 0 80000000;
BA_DEF_ BO_ "GenMsgILSupport" ENUM "No","Yes";
BA_DEF_ BO_ "NmAsrMessage" ENUM "No","Yes";
BA_DEF_ SG_ "GenSigFuncType" ENUM "NoFunction","n/a","n/a","n/a","n/a","n/a","n/a","n/a","n/a","n/a","n/a","n/a","n/a","n/a","n/a","CHK","CNTR","n/a","n/a","n/a","CNTR_AR_01","CRC_AR_01_BOTH","CRC_AR_01_ALT","CRC_AR_01_LOW","CRC_AR_01_NIBBLE","CNTR_AR_04","CRC_AR_04A","CNTR_AR_05","CRC_AR_05";
BA_DEF_ SG_ "GenSigDataID" STRING;

BA_DEF_DEF_ "GenSigStartValue" 0;
BA_DEF_DEF_ "GenSigSendType" "NoSigSendType";
BA_DEF_DEF_ "GenMsgCycleTime" 0;
BA_DEF_DEF_ "GenMsgDelayTime" 0;
BA_DEF_DEF_ "GenMsgStartDelayTime" 0;
BA_DEF_DEF_ "GenMsgSendType" "NoMsgSendType";
BA_DEF_DEF_ "GenMsgILSupport" "Yes";
BA_DEF_DEF_ "NmAsrMessage" "No";
BA_DEF_DEF_ "GenSigFuncType" "NoFunction";
BA_DEF_DEF_ "GenSigDataID" "";
// Frame: EcmPropFr25
BA_ "GenMsgSendType" BO_ 634 0;
BA_ "GenMsgCycleTime" BO_ 634 100.000;
BA_ "GenSigSendType" SG_ 634 DenoOfDiagcRateGen 0;
BA_ "GenSigSendType" SG_ 634 DrvgCyc 0;
BA_ "GenSigSendType" SG_ 634 DrvgCycToClrPrmntDtc 0;
BA_ "GenSigSendType" SG_ 634 IuprDenominatorInhb 0;
// Frame: EcmPropNMFr
BA_ "GenMsgSendType" BO_ 1312 1;
BA_ "GenMsgDelayTime" BO_ 1312 20.000;
BA_ "GenMsgILSupport" BO_ 1312 0;
BA_ "NmAsrMessage" BO_ 1312 1;
// Frame: EcmPropVFCVectorFr
BA_ "GenMsgSendType" BO_ 1347 1;
BA_ "GenMsgDelayTime" BO_ 1347 495.000;
BA_ "GenSigSendType" SG_ 1347 VFCVectorECMBlockID 1;
BA_ "GenSigSendType" SG_ 1347 VFCVectorECMVFCid0 1;
BA_ "GenSigSendType" SG_ 1347 VFCVectorECMVFCid1 1;
BA_ "GenSigSendType" SG_ 1347 VFCVectorECMVFCid10 1;
BA_ "GenSigSendType" SG_ 1347 VFCVectorECMVFCid11 1;
BA_ "GenSigSendType" SG_ 1347 VFCVectorECMVFCid12 1;
BA_ "GenSigSendType" SG_ 1347 VFCVectorECMVFCid13 1;
BA_ "GenSigSendType" SG_ 1347 VFCVectorECMVFCid14 1;
BA_ "GenSigSendType" SG_ 1347 VFCVectorECMVFCid15 1;
BA_ "GenSigSendType" SG_ 1347 VFCVectorECMVFCid16 1;
BA_ "GenSigSendType" SG_ 1347 VFCVectorECMVFCid17 1;
BA_ "GenSigSendType" SG_ 1347 VFCVectorECMVFCid18 1;
BA_ "GenSigSendType" SG_ 1347 VFCVectorECMVFCid19 1;
BA_ "GenSigSendType" SG_ 1347 VFCVectorECMVFCid2 1;
BA_ "GenSigSendType" SG_ 1347 VFCVectorECMVFCid20 1;
BA_ "GenSigSendType" SG_ 1347 VFCVectorECMVFCid21 1;
BA_ "GenSigSendType" SG_ 1347 VFCVectorECMVFCid22 1;
BA_ "GenSigSendType" SG_ 1347 VFCVectorECMVFCid23 1;
BA_ "GenSigSendType" SG_ 1347 VFCVectorECMVFCid24 1;
BA_ "GenSigSendType" SG_ 1347 VFCVectorECMVFCid25 1;
BA_ "GenSigSendType" SG_ 1347 VFCVectorECMVFCid26 1;
BA_ "GenSigSendType" SG_ 1347 VFCVectorECMVFCid27 1;
BA_ "GenSigSendType" SG_ 1347 VFCVectorECMVFCid28 1;
BA_ "GenSigSendType" SG_ 1347 VFCVectorECMVFCid29 1;
BA_ "GenSigSendType" SG_ 1347 VFCVectorECMVFCid3 1;
BA_ "GenSigSendType" SG_ 1347 VFCVectorECMVFCid30 1;
BA_ "GenSigSendType" SG_ 1347 VFCVectorECMVFCid31 1;
BA_ "GenSigSendType" SG_ 1347 VFCVectorECMVFCid32 1;
BA_ "GenSigSendType" SG_ 1347 VFCVectorECMVFCid33 1;
BA_ "GenSigSendType" SG_ 1347 VFCVectorECMVFCid34 1;
BA_ "GenSigSendType" SG_ 1347 VFCVectorECMVFCid35 1;
BA_ "GenSigSendType" SG_ 1347 VFCVectorECMVFCid36 1;
BA_ "GenSigSendType" SG_ 1347 VFCVectorECMVFCid37 1;
BA_ "GenSigSendType" SG_ 1347 VFCVectorECMVFCid38 1;
BA_ "GenSigSendType" SG_ 1347 VFCVectorECMVFCid39 1;
BA_ "GenSigSendType" SG_ 1347 VFCVectorECMVFCid4 1;
BA_ "GenSigSendType" SG_ 1347 VFCVectorECMVFCid40 1;
BA_ "GenSigSendType" SG_ 1347 VFCVectorECMVFCid41 1;
BA_ "GenSigSendType" SG_ 1347 VFCVectorECMVFCid42 1;
BA_ "GenSigSendType" SG_ 1347 VFCVectorECMVFCid43 1;
BA_ "GenSigSendType" SG_ 1347 VFCVectorECMVFCid44 1;
BA_ "GenSigSendType" SG_ 1347 VFCVectorECMVFCid45 1;
BA_ "GenSigSendType" SG_ 1347 VFCVectorECMVFCid46 1;
BA_ "GenSigSendType" SG_ 1347 VFCVectorECMVFCid47 1;
BA_ "GenSigSendType" SG_ 1347 VFCVectorECMVFCid48 1;
BA_ "GenSigSendType" SG_ 1347 VFCVectorECMVFCid49 1;
BA_ "GenSigSendType" SG_ 1347 VFCVectorECMVFCid5 1;
BA_ "GenSigSendType" SG_ 1347 VFCVectorECMVFCid50 1;
BA_ "GenSigSendType" SG_ 1347 VFCVectorECMVFCid51 1;
BA_ "GenSigSendType" SG_ 1347 VFCVectorECMVFCid52 1;
BA_ "GenSigSendType" SG_ 1347 VFCVectorECMVFCid53 1;
BA_ "GenSigSendType" SG_ 1347 VFCVectorECMVFCid54 1;
BA_ "GenSigSendType" SG_ 1347 VFCVectorECMVFCid55 1;
BA_ "GenSigSendType" SG_ 1347 VFCVectorECMVFCid56 1;
BA_ "GenSigSendType" SG_ 1347 VFCVectorECMVFCid57 1;
BA_ "GenSigSendType" SG_ 1347 VFCVectorECMVFCid58 1;
BA_ "GenSigSendType" SG_ 1347 VFCVectorECMVFCid59 1;
BA_ "GenSigSendType" SG_ 1347 VFCVectorECMVFCid6 1;
BA_ "GenSigSendType" SG_ 1347 VFCVectorECMVFCid60 1;
BA_ "GenSigSendType" SG_ 1347 VFCVectorECMVFCid61 1;
BA_ "GenSigSendType" SG_ 1347 VFCVectorECMVFCid7 1;
BA_ "GenSigSendType" SG_ 1347 VFCVectorECMVFCid8 1;
BA_ "GenSigSendType" SG_ 1347 VFCVectorECMVFCid9 1;
// Frame: EcmPropXevFr06
BA_ "GenMsgSendType" BO_ 401 0;
BA_ "GenMsgCycleTime" BO_ 401 25.000;
BA_ "GenSigSendType" SG_ 401 IsgEngSpdOfActvDampg 0;
BA_ "GenSigSendType" SG_ 401 IsgTqAllwdChks 0;
BA_ "GenSigFuncType" SG_ 401 IsgTqAllwdChks 15;
BA_ "GenSigDataID" SG_ 401 IsgTqAllwdChks "0x50";
BA_ "GenSigSendType" SG_ 401 IsgTqAllwdCntr 0;
BA_ "GenSigFuncType" SG_ 401 IsgTqAllwdCntr 16;
BA_ "GenSigSendType" SG_ 401 IsgTqAllwdIsgTqAllwd 0;
BA_ "GenSigSendType" SG_ 401 WhlMotSysActvDampgModReq 0;
BA_ "GenSigStartValue" SG_ 401 WhlMotSysPwrLimMin 1022;
BA_ "GenSigSendType" SG_ 401 WhlMotSysPwrLimMin 0;
// Frame: EcmPropXEVFr16
BA_ "GenMsgSendType" BO_ 649 0;
BA_ "GenMsgCycleTime" BO_ 649 100.000;
BA_ "GenSigSendType" SG_ 649 EngOnReq 0;
BA_ "GenSigSendType" SG_ 649 HvBattChrgnEgyCnsAllwd1 0;
BA_ "GenSigSendType" SG_ 649 HvBattChrgnILim 0;
BA_ "GenSigSendType" SG_ 649 HvBattCoolgEgyCnsAllwd1 0;
BA_ "GenSigSendType" SG_ 649 RadFanCoolgSts 0;
// Frame: EcmToVddmPropDiagResFrame
BA_ "GenMsgSendType" BO_ 1584 1;
BA_ "GenMsgDelayTime" BO_ 1584 5.000;
// Frame: EcmToVgmJ1979OBDPropCanResFrame11
BA_ "GenMsgSendType" BO_ 2024 1;
BA_ "GenMsgDelayTime" BO_ 2024 5.000;
// Frame: EgsmPropFr01
BA_ "GenMsgSendType" BO_ 309 0;
BA_ "GenMsgCycleTime" BO_ 309 20.000;
BA_ "GenSigSendType" SG_ 309 DrvrGearShiftManReqDwnDwnTipReq 0;
BA_ "GenSigSendType" SG_ 309 DrvrGearShiftManReqDwnTipReq 0;
BA_ "GenSigSendType" SG_ 309 DrvrGearShiftManReqSteerWhlDwnReq1 0;
BA_ "GenSigSendType" SG_ 309 DrvrGearShiftManReqSteerWhlUpReq 0;
BA_ "GenSigSendType" SG_ 309 DrvrGearShiftManReqTipReq1 0;
BA_ "GenSigSendType" SG_ 309 DrvrGearShiftManReqUpTipReq1 0;
BA_ "GenSigSendType" SG_ 309 DrvrGearShiftManReqUpUpTipReq 0;
BA_ "GenSigSendType" SG_ 309 DrvrGearShiftParkReq1 0;
BA_ "GenSigSendType" SG_ 309 DrvrGearShiftParkReqChks 0;
BA_ "GenSigFuncType" SG_ 309 DrvrGearShiftParkReqChks 15;
BA_ "GenSigDataID" SG_ 309 DrvrGearShiftParkReqChks "0x20F";
BA_ "GenSigSendType" SG_ 309 DrvrGearShiftParkReqCntr 0;
BA_ "GenSigFuncType" SG_ 309 DrvrGearShiftParkReqCntr 16;
BA_ "GenSigSendType" SG_ 309 DrvrGearShiftParkReqSts 0;
BA_ "GenSigSendType" SG_ 309 GearLock 0;
BA_ "GenSigSendType" SG_ 309 GearShiftUnitSts 0;
// Frame: EgsmPropFr02
BA_ "GenMsgSendType" BO_ 310 0;
BA_ "GenMsgCycleTime" BO_ 310 20.000;
BA_ "GenSigSendType" SG_ 310 DrvrGearShiftDirReq1Chks 0;
BA_ "GenSigFuncType" SG_ 310 DrvrGearShiftDirReq1Chks 15;
BA_ "GenSigDataID" SG_ 310 DrvrGearShiftDirReq1Chks "0x39";
BA_ "GenSigSendType" SG_ 310 DrvrGearShiftDirReq1Cntr 0;
BA_ "GenSigFuncType" SG_ 310 DrvrGearShiftDirReq1Cntr 16;
BA_ "GenSigSendType" SG_ 310 DrvrGearShiftDirReq1DwnDwnTipAut 0;
BA_ "GenSigSendType" SG_ 310 DrvrGearShiftDirReq1DwnTipAut 0;
BA_ "GenSigSendType" SG_ 310 DrvrGearShiftDirReq1PosnAut 0;
BA_ "GenSigSendType" SG_ 310 DrvrGearShiftDirReq1UpTipAut 0;
BA_ "GenSigSendType" SG_ 310 DrvrGearShiftDirReq1UpUpTipAut 0;
BA_ "GenSigSendType" SG_ 310 DrvrGearShiftDirReq2Chks 0;
BA_ "GenSigFuncType" SG_ 310 DrvrGearShiftDirReq2Chks 15;
BA_ "GenSigDataID" SG_ 310 DrvrGearShiftDirReq2Chks "0x62";
BA_ "GenSigSendType" SG_ 310 DrvrGearShiftDirReq2Cntr 0;
BA_ "GenSigFuncType" SG_ 310 DrvrGearShiftDirReq2Cntr 16;
BA_ "GenSigSendType" SG_ 310 DrvrGearShiftDirReq2DwnDwnTipAut 0;
BA_ "GenSigSendType" SG_ 310 DrvrGearShiftDirReq2DwnTipAut 0;
BA_ "GenSigSendType" SG_ 310 DrvrGearShiftDirReq2PosnAut 0;
BA_ "GenSigSendType" SG_ 310 DrvrGearShiftDirReq2UpTipAut 0;
BA_ "GenSigSendType" SG_ 310 DrvrGearShiftDirReq2UpUpTipAut 0;
// Frame: EgsmPropNMFr
BA_ "GenMsgSendType" BO_ 1302 1;
BA_ "GenMsgDelayTime" BO_ 1302 20.000;
BA_ "GenMsgILSupport" BO_ 1302 0;
BA_ "NmAsrMessage" BO_ 1302 1;
// Frame: EgsmPropVFCVectorFr
BA_ "GenMsgSendType" BO_ 1349 1;
BA_ "GenMsgDelayTime" BO_ 1349 495.000;
BA_ "GenSigSendType" SG_ 1349 VFCVectorEGSMBlockID 1;
BA_ "GenSigSendType" SG_ 1349 VFCVectorEGSMVFCid0 1;
BA_ "GenSigSendType" SG_ 1349 VFCVectorEGSMVFCid1 1;
BA_ "GenSigSendType" SG_ 1349 VFCVectorEGSMVFCid10 1;
BA_ "GenSigSendType" SG_ 1349 VFCVectorEGSMVFCid11 1;
BA_ "GenSigSendType" SG_ 1349 VFCVectorEGSMVFCid12 1;
BA_ "GenSigSendType" SG_ 1349 VFCVectorEGSMVFCid13 1;
BA_ "GenSigSendType" SG_ 1349 VFCVectorEGSMVFCid14 1;
BA_ "GenSigSendType" SG_ 1349 VFCVectorEGSMVFCid15 1;
BA_ "GenSigSendType" SG_ 1349 VFCVectorEGSMVFCid16 1;
BA_ "GenSigSendType" SG_ 1349 VFCVectorEGSMVFCid17 1;
BA_ "GenSigSendType" SG_ 1349 VFCVectorEGSMVFCid18 1;
BA_ "GenSigSendType" SG_ 1349 VFCVectorEGSMVFCid19 1;
BA_ "GenSigSendType" SG_ 1349 VFCVectorEGSMVFCid2 1;
BA_ "GenSigSendType" SG_ 1349 VFCVectorEGSMVFCid20 1;
BA_ "GenSigSendType" SG_ 1349 VFCVectorEGSMVFCid21 1;
BA_ "GenSigSendType" SG_ 1349 VFCVectorEGSMVFCid22 1;
BA_ "GenSigSendType" SG_ 1349 VFCVectorEGSMVFCid23 1;
BA_ "GenSigSendType" SG_ 1349 VFCVectorEGSMVFCid24 1;
BA_ "GenSigSendType" SG_ 1349 VFCVectorEGSMVFCid25 1;
BA_ "GenSigSendType" SG_ 1349 VFCVectorEGSMVFCid26 1;
BA_ "GenSigSendType" SG_ 1349 VFCVectorEGSMVFCid27 1;
BA_ "GenSigSendType" SG_ 1349 VFCVectorEGSMVFCid28 1;
BA_ "GenSigSendType" SG_ 1349 VFCVectorEGSMVFCid29 1;
BA_ "GenSigSendType" SG_ 1349 VFCVectorEGSMVFCid3 1;
BA_ "GenSigSendType" SG_ 1349 VFCVectorEGSMVFCid30 1;
BA_ "GenSigSendType" SG_ 1349 VFCVectorEGSMVFCid31 1;
BA_ "GenSigSendType" SG_ 1349 VFCVectorEGSMVFCid32 1;
BA_ "GenSigSendType" SG_ 1349 VFCVectorEGSMVFCid33 1;
BA_ "GenSigSendType" SG_ 1349 VFCVectorEGSMVFCid34 1;
BA_ "GenSigSendType" SG_ 1349 VFCVectorEGSMVFCid35 1;
BA_ "GenSigSendType" SG_ 1349 VFCVectorEGSMVFCid36 1;
BA_ "GenSigSendType" SG_ 1349 VFCVectorEGSMVFCid37 1;
BA_ "GenSigSendType" SG_ 1349 VFCVectorEGSMVFCid38 1;
BA_ "GenSigSendType" SG_ 1349 VFCVectorEGSMVFCid39 1;
BA_ "GenSigSendType" SG_ 1349 VFCVectorEGSMVFCid4 1;
BA_ "GenSigSendType" SG_ 1349 VFCVectorEGSMVFCid40 1;
BA_ "GenSigSendType" SG_ 1349 VFCVectorEGSMVFCid41 1;
BA_ "GenSigSendType" SG_ 1349 VFCVectorEGSMVFCid42 1;
BA_ "GenSigSendType" SG_ 1349 VFCVectorEGSMVFCid43 1;
BA_ "GenSigSendType" SG_ 1349 VFCVectorEGSMVFCid44 1;
BA_ "GenSigSendType" SG_ 1349 VFCVectorEGSMVFCid45 1;
BA_ "GenSigSendType" SG_ 1349 VFCVectorEGSMVFCid46 1;
BA_ "GenSigSendType" SG_ 1349 VFCVectorEGSMVFCid47 1;
BA_ "GenSigSendType" SG_ 1349 VFCVectorEGSMVFCid48 1;
BA_ "GenSigSendType" SG_ 1349 VFCVectorEGSMVFCid49 1;
BA_ "GenSigSendType" SG_ 1349 VFCVectorEGSMVFCid5 1;
BA_ "GenSigSendType" SG_ 1349 VFCVectorEGSMVFCid50 1;
BA_ "GenSigSendType" SG_ 1349 VFCVectorEGSMVFCid51 1;
BA_ "GenSigSendType" SG_ 1349 VFCVectorEGSMVFCid52 1;
BA_ "GenSigSendType" SG_ 1349 VFCVectorEGSMVFCid53 1;
BA_ "GenSigSendType" SG_ 1349 VFCVectorEGSMVFCid54 1;
BA_ "GenSigSendType" SG_ 1349 VFCVectorEGSMVFCid55 1;
BA_ "GenSigSendType" SG_ 1349 VFCVectorEGSMVFCid56 1;
BA_ "GenSigSendType" SG_ 1349 VFCVectorEGSMVFCid57 1;
BA_ "GenSigSendType" SG_ 1349 VFCVectorEGSMVFCid58 1;
BA_ "GenSigSendType" SG_ 1349 VFCVectorEGSMVFCid59 1;
BA_ "GenSigSendType" SG_ 1349 VFCVectorEGSMVFCid6 1;
BA_ "GenSigSendType" SG_ 1349 VFCVectorEGSMVFCid60 1;
BA_ "GenSigSendType" SG_ 1349 VFCVectorEGSMVFCid61 1;
BA_ "GenSigSendType" SG_ 1349 VFCVectorEGSMVFCid7 1;
BA_ "GenSigSendType" SG_ 1349 VFCVectorEGSMVFCid8 1;
BA_ "GenSigSendType" SG_ 1349 VFCVectorEGSMVFCid9 1;
// Frame: EgsmToVddmPropDiagResFrame
BA_ "GenMsgSendType" BO_ 1587 1;
BA_ "GenMsgDelayTime" BO_ 1587 5.000;
// Frame: EsmPropFr01
BA_ "GenMsgSendType" BO_ 801 0;
BA_ "GenMsgCycleTime" BO_ 801 1000.000;
BA_ "GenSigSendType" SG_ 801 ComLostExtrSoundFront 0;
// Frame: EsmPropNmFr
BA_ "GenMsgSendType" BO_ 1320 1;
BA_ "GenMsgDelayTime" BO_ 1320 20.000;
BA_ "GenMsgILSupport" BO_ 1320 0;
BA_ "NmAsrMessage" BO_ 1320 1;
// Frame: EsmToVddmPropDiagResFrame
BA_ "GenMsgSendType" BO_ 1594 1;
BA_ "GenMsgDelayTime" BO_ 1594 5.000;
// Frame: EtcMvbmPropDevFr01
BA_ "GenMsgSendType" BO_ 1479 1;
BA_ "GenMsgDelayTime" BO_ 1479 100.000;
BA_ "GenSigSendType" SG_ 1479 MVBMdevelpsignalgroupreqFunctiondevpsignalgroup1 1;
BA_ "GenSigSendType" SG_ 1479 MVBMdevelpsignalgroupreqFunctiondevpsignalgroup2 1;
BA_ "GenSigSendType" SG_ 1479 MVBMdevelpsignalgroupreqFunctiondevpsignalgroup3 1;
BA_ "GenSigSendType" SG_ 1479 MVBMdevelpsignalgroupreqFunctiondevpsignalgroup4 1;
BA_ "GenSigSendType" SG_ 1479 MVBMdevelpsignalgroupreqFunctiondevpsignalgroup5 1;
BA_ "GenSigSendType" SG_ 1479 MVBMdevelpsignalgroupreqFunctiondevpsignalgroup6 1;
BA_ "GenSigSendType" SG_ 1479 MVBMdevelpsignalgroupreqFunctiondevpsignalgroup7 1;
BA_ "GenSigSendType" SG_ 1479 MVBMdevelpsignalgroupreqFunctiondevpsignalgroup8 1;
// Frame: EtcMvcmPropDevFr01
BA_ "GenMsgSendType" BO_ 1462 1;
BA_ "GenMsgDelayTime" BO_ 1462 100.000;
BA_ "GenSigSendType" SG_ 1462 MVCMdevelpsignalgroupreqFunctiondevpsignalgroup1 1;
BA_ "GenSigSendType" SG_ 1462 MVCMdevelpsignalgroupreqFunctiondevpsignalgroup2 1;
BA_ "GenSigSendType" SG_ 1462 MVCMdevelpsignalgroupreqFunctiondevpsignalgroup3 1;
BA_ "GenSigSendType" SG_ 1462 MVCMdevelpsignalgroupreqFunctiondevpsignalgroup4 1;
BA_ "GenSigSendType" SG_ 1462 MVCMdevelpsignalgroupreqFunctiondevpsignalgroup5 1;
BA_ "GenSigSendType" SG_ 1462 MVCMdevelpsignalgroupreqFunctiondevpsignalgroup6 1;
BA_ "GenSigSendType" SG_ 1462 MVCMdevelpsignalgroupreqFunctiondevpsignalgroup7 1;
BA_ "GenSigSendType" SG_ 1462 MVCMdevelpsignalgroupreqFunctiondevpsignalgroup8 1;
// Frame: EtcObcPropDevFr01
BA_ "GenMsgSendType" BO_ 1430 1;
BA_ "GenMsgDelayTime" BO_ 1430 100.000;
BA_ "GenSigSendType" SG_ 1430 OBCdevelpsignalgroupreqFunctiondevpsignalgroup1 1;
BA_ "GenSigSendType" SG_ 1430 OBCdevelpsignalgroupreqFunctiondevpsignalgroup2 1;
BA_ "GenSigSendType" SG_ 1430 OBCdevelpsignalgroupreqFunctiondevpsignalgroup3 1;
BA_ "GenSigSendType" SG_ 1430 OBCdevelpsignalgroupreqFunctiondevpsignalgroup4 1;
BA_ "GenSigSendType" SG_ 1430 OBCdevelpsignalgroupreqFunctiondevpsignalgroup5 1;
BA_ "GenSigSendType" SG_ 1430 OBCdevelpsignalgroupreqFunctiondevpsignalgroup6 1;
BA_ "GenSigSendType" SG_ 1430 OBCdevelpsignalgroupreqFunctiondevpsignalgroup7 1;
BA_ "GenSigSendType" SG_ 1430 OBCdevelpsignalgroupreqFunctiondevpsignalgroup8 1;
// Frame: EtcPropDevFr03
BA_ "GenMsgSendType" BO_ 1415 0;
BA_ "GenMsgCycleTime" BO_ 1415 1000.000;
BA_ "GenSigSendType" SG_ 1415 DftlDevCtrl0 1;
BA_ "GenSigSendType" SG_ 1415 DftlDevCtrl1 1;
BA_ "GenSigSendType" SG_ 1415 DftlDevCtrl2 1;
BA_ "GenSigSendType" SG_ 1415 DftlDevCtrl3 1;
BA_ "GenSigSendType" SG_ 1415 DftlDevCtrl4 1;
BA_ "GenSigSendType" SG_ 1415 DftlDevCtrl5 1;
BA_ "GenSigSendType" SG_ 1415 DftlDevCtrl6 1;
BA_ "GenSigSendType" SG_ 1415 DftlDevCtrl7 1;
// Frame: EtcSrsPropDevFr01
BA_ "GenMsgSendType" BO_ 1457 1;
BA_ "GenMsgDelayTime" BO_ 1457 100.000;
BA_ "GenSigSendType" SG_ 1457 SRSdevelpsignalgroupRXFunctiondevpsignalgroup1 1;
BA_ "GenSigSendType" SG_ 1457 SRSdevelpsignalgroupRXFunctiondevpsignalgroup2 1;
BA_ "GenSigSendType" SG_ 1457 SRSdevelpsignalgroupRXFunctiondevpsignalgroup3 1;
BA_ "GenSigSendType" SG_ 1457 SRSdevelpsignalgroupRXFunctiondevpsignalgroup4 1;
BA_ "GenSigSendType" SG_ 1457 SRSdevelpsignalgroupRXFunctiondevpsignalgroup5 1;
BA_ "GenSigSendType" SG_ 1457 SRSdevelpsignalgroupRXFunctiondevpsignalgroup6 1;
BA_ "GenSigSendType" SG_ 1457 SRSdevelpsignalgroupRXFunctiondevpsignalgroup7 1;
BA_ "GenSigSendType" SG_ 1457 SRSdevelpsignalgroupRXFunctiondevpsignalgroup8 1;
// Frame: EtctoCddXCPFr01
BA_ "GenMsgSendType" BO_ 1410 1;
BA_ "GenMsgDelayTime" BO_ 1410 5.000;
// Frame: ETCtoDEMXCPFr01
BA_ "GenMsgSendType" BO_ 1448 1;
BA_ "GenMsgDelayTime" BO_ 1448 10.000;
// Frame: ETCtoDEMXCPFr02
BA_ "GenMsgSendType" BO_ 1447 1;
BA_ "GenMsgDelayTime" BO_ 1447 10.000;
// Frame: ETCtoDEMXCPFr03
BA_ "GenMsgSendType" BO_ 1449 1;
BA_ "GenMsgDelayTime" BO_ 1449 10.000;
// Frame: ETCtoDEMXCPFr04
BA_ "GenMsgSendType" BO_ 1450 1;
BA_ "GenMsgDelayTime" BO_ 1450 10.000;
// Frame: ETCtoDEMXCPFr05
BA_ "GenMsgSendType" BO_ 1451 1;
BA_ "GenMsgDelayTime" BO_ 1451 10.000;
// Frame: ETCtoDEMXCPFr06
BA_ "GenMsgSendType" BO_ 1452 1;
BA_ "GenMsgDelayTime" BO_ 1452 10.000;
// Frame: EtctoEcmXCPFr01
BA_ "GenMsgSendType" BO_ 1412 1;
BA_ "GenMsgDelayTime" BO_ 1412 5.000;
// Frame: EtctoIgsmXCPFr01
BA_ "GenMsgSendType" BO_ 1418 1;
BA_ "GenMsgDelayTime" BO_ 1418 5.000;
// Frame: ETCtoTACMXcpFr01
BA_ "GenMsgSendType" BO_ 1424 1;
BA_ "GenMsgDelayTime" BO_ 1424 10.000;
// Frame: ETCtoTACMXcpFr02
BA_ "GenMsgSendType" BO_ 1428 1;
BA_ "GenMsgDelayTime" BO_ 1428 10.000;
// Frame: EtcToVddmDevelFr
BA_ "GenMsgSendType" BO_ 1513 1;
BA_ "GenMsgDelayTime" BO_ 1513 95.000;
BA_ "GenSigSendType" SG_ 1513 VDDMPropCANInternalDevReqMesgFunctiondevpsignalgroup1 1;
BA_ "GenSigSendType" SG_ 1513 VDDMPropCANInternalDevReqMesgFunctiondevpsignalgroup2 1;
BA_ "GenSigSendType" SG_ 1513 VDDMPropCANInternalDevReqMesgFunctiondevpsignalgroup3 1;
BA_ "GenSigSendType" SG_ 1513 VDDMPropCANInternalDevReqMesgFunctiondevpsignalgroup4 1;
BA_ "GenSigSendType" SG_ 1513 VDDMPropCANInternalDevReqMesgFunctiondevpsignalgroup5 1;
BA_ "GenSigSendType" SG_ 1513 VDDMPropCANInternalDevReqMesgFunctiondevpsignalgroup6 1;
BA_ "GenSigSendType" SG_ 1513 VDDMPropCANInternalDevReqMesgFunctiondevpsignalgroup7 1;
BA_ "GenSigSendType" SG_ 1513 VDDMPropCANInternalDevReqMesgFunctiondevpsignalgroup8 1;
// Frame: IemEduPropFr01
BA_ "GenMsgSendType" BO_ 76 0;
BA_ "GenMsgCycleTime" BO_ 76 10.000;
BA_ "GenSigSendType" SG_ 76 WhlMotSysModSts 0;
BA_ "GenSigStartValue" SG_ 76 WhlMotSysTqAvlTqAvlMax 2047;
BA_ "GenSigSendType" SG_ 76 WhlMotSysTqAvlTqAvlMax 0;
BA_ "GenSigStartValue" SG_ 76 WhlMotSysTqAvlTqAvlMin 2047;
BA_ "GenSigSendType" SG_ 76 WhlMotSysTqAvlTqAvlMin 0;
BA_ "GenSigSendType" SG_ 76 WhlMotSysTqEstChks 0;
BA_ "GenSigFuncType" SG_ 76 WhlMotSysTqEstChks 15;
BA_ "GenSigDataID" SG_ 76 WhlMotSysTqEstChks "0x45";
BA_ "GenSigSendType" SG_ 76 WhlMotSysTqEstCntr 0;
BA_ "GenSigFuncType" SG_ 76 WhlMotSysTqEstCntr 16;
BA_ "GenSigStartValue" SG_ 76 WhlMotSysTqEstIsgTqAct 8188;
BA_ "GenSigSendType" SG_ 76 WhlMotSysTqEstIsgTqAct 0;
BA_ "GenSigStartValue" SG_ 76 WhlMotSysTqEstQualityFactor 1;
BA_ "GenSigSendType" SG_ 76 WhlMotSysTqEstQualityFactor 0;
// Frame: IemEduPropFr02
BA_ "GenMsgSendType" BO_ 96 0;
BA_ "GenMsgCycleTime" BO_ 96 20.000;
BA_ "GenSigSendType" SG_ 96 ImobEngSts2 0;
BA_ "GenSigStartValue" SG_ 96 WhlMotSysCooltT 40;
BA_ "GenSigSendType" SG_ 96 WhlMotSysCooltT 0;
BA_ "GenSigSendType" SG_ 96 WhlMotSysLimnIndcn 0;
BA_ "GenSigSendType" SG_ 96 WhlMotSysSpdAct 0;
BA_ "GenSigSendType" SG_ 96 WhlMotSysUdc 0;
// Frame: IemPropFr01
BA_ "GenMsgSendType" BO_ 1111 0;
BA_ "GenMsgCycleTime" BO_ 1111 800.000;
BA_ "GenSigSendType" SG_ 1111 IEMTestFr1Byte0 0;
BA_ "GenSigSendType" SG_ 1111 IEMTestFr1Byte1 0;
BA_ "GenSigSendType" SG_ 1111 IEMTestFr1Byte2 0;
BA_ "GenSigSendType" SG_ 1111 IEMTestFr1Byte3 0;
BA_ "GenSigSendType" SG_ 1111 IEMTestFr1Byte4 0;
BA_ "GenSigSendType" SG_ 1111 IEMTestFr1Byte5 0;
BA_ "GenSigSendType" SG_ 1111 IEMTestFr1Byte6 0;
BA_ "GenSigSendType" SG_ 1111 IEMTestFr1Byte7 0;
// Frame: IemPropFr02
BA_ "GenMsgSendType" BO_ 1125 0;
BA_ "GenMsgCycleTime" BO_ 1125 800.000;
BA_ "GenSigSendType" SG_ 1125 IEMTestFr2Byte0 0;
BA_ "GenSigSendType" SG_ 1125 IEMTestFr2Byte1 0;
BA_ "GenSigSendType" SG_ 1125 IEMTestFr2Byte2 0;
BA_ "GenSigSendType" SG_ 1125 IEMTestFr2Byte3 0;
BA_ "GenSigSendType" SG_ 1125 IEMTestFr2Byte4 0;
BA_ "GenSigSendType" SG_ 1125 IEMTestFr2Byte5 0;
BA_ "GenSigSendType" SG_ 1125 IEMTestFr2Byte6 0;
BA_ "GenSigSendType" SG_ 1125 IEMTestFr2Byte7 0;
// Frame: IemPropFr03
BA_ "GenMsgSendType" BO_ 773 0;
BA_ "GenMsgCycleTime" BO_ 773 600.000;
BA_ "GenSigSendType" SG_ 773 WhlMotClrRdyReq 0;
BA_ "GenSigSendType" SG_ 773 WhlMotSysCoolgReq 0;
BA_ "GenSigSendType" SG_ 773 WhlMotSysErrIndcnReq 0;
BA_ "GenSigStartValue" SG_ 773 WhlMotSysInvrT 50;
BA_ "GenSigSendType" SG_ 773 WhlMotSysInvrT 0;
BA_ "GenSigStartValue" SG_ 773 WhlMotSysMotT 50;
BA_ "GenSigSendType" SG_ 773 WhlMotSysMotT 0;
// Frame: IemPropFr04
BA_ "GenMsgSendType" BO_ 613 0;
BA_ "GenMsgCycleTime" BO_ 613 80.000;
BA_ "GenSigSendType" SG_ 613 ImobEngChk2ImobEngChkSts 0;
BA_ "GenSigSendType" SG_ 613 ImobEngChk2ImobEngDataChk0 0;
BA_ "GenSigSendType" SG_ 613 ImobEngChk2ImobEngDataChk1 0;
BA_ "GenSigSendType" SG_ 613 ImobEngChk2ImobEngDataChk2 0;
BA_ "GenSigSendType" SG_ 613 ImobEngChk2ImobEngDataChk3 0;
BA_ "GenSigSendType" SG_ 613 ImobEngChk2ImobEngDataChk4 0;
BA_ "GenSigSendType" SG_ 613 ImobEngChk2ImobEngDataChk5 0;
BA_ "GenSigSendType" SG_ 613 ImobEngChk2ImobEngDataChk6 0;
// Frame: IemPropFr06
BA_ "GenMsgSendType" BO_ 626 0;
BA_ "GenMsgCycleTime" BO_ 626 100.000;
BA_ "GenSigSendType" SG_ 626 IemGenericADAlrmSt 0;
BA_ "GenSigSendType" SG_ 626 IemGenericDTCHig 0;
BA_ "GenSigSendType" SG_ 626 IemGenericDTCLow 0;
BA_ "GenSigSendType" SG_ 626 IemGenericDTCMid 0;
BA_ "GenSigSendType" SG_ 626 IemGenericDTCSts 0;
BA_ "GenSigSendType" SG_ 626 IemGenericEMQnty 0;
BA_ "GenSigSendType" SG_ 626 IemGenericEMSeqNr 0;
BA_ "GenSigSendType" SG_ 626 IemGenericFltAlrmSt 0;
BA_ "GenSigSendType" SG_ 626 IemGenericIacAlrmSt 0;
BA_ "GenSigSendType" SG_ 626 IemGenericInvrtTAlrmSt 0;
BA_ "GenSigStartValue" SG_ 626 IemGenericModStatusRms 3;
BA_ "GenSigSendType" SG_ 626 IemGenericModStatusRms 0;
BA_ "GenSigSendType" SG_ 626 IemGenericMotTAlrmSt 0;
BA_ "GenSigSendType" SG_ 626 IemGenericResd1 0;
BA_ "GenSigSendType" SG_ 626 IemGenericRslAlrmSt 0;
BA_ "GenSigSendType" SG_ 626 IemGenericSpdAlrmSt 0;
BA_ "GenSigSendType" SG_ 626 IemGenericUDcAlrmSt 0;
// Frame: IemPropFr07
BA_ "GenMsgSendType" BO_ 643 0;
BA_ "GenMsgCycleTime" BO_ 643 150.000;
BA_ "GenSigSendType" SG_ 643 WhlMotCooltFlowMinReq 0;
BA_ "GenSigSendType" SG_ 643 WhlMotNetIntlHeatg 0;
BA_ "GenSigStartValue" SG_ 643 WhlMotThermPwrMaxReq 10;
BA_ "GenSigSendType" SG_ 643 WhlMotThermPwrMaxReq 0;
BA_ "GenSigStartValue" SG_ 643 WhlMotThermPwrMinReq -10;
BA_ "GenSigSendType" SG_ 643 WhlMotThermPwrMinReq 0;
// Frame: IemPropFr08
BA_ "GenMsgSendType" BO_ 99 0;
BA_ "GenMsgCycleTime" BO_ 99 20.000;
BA_ "GenSigStartValue" SG_ 99 WhlMotSysIdc 8188;
BA_ "GenSigSendType" SG_ 99 WhlMotSysIdc 0;
// Frame: IemPropFr09
BA_ "GenMsgSendType" BO_ 1126 0;
BA_ "GenMsgCycleTime" BO_ 1126 800.000;
BA_ "GenSigSendType" SG_ 1126 IEMTestFr3Byte0 0;
BA_ "GenSigSendType" SG_ 1126 IEMTestFr3Byte1 0;
BA_ "GenSigSendType" SG_ 1126 IEMTestFr3Byte2 0;
BA_ "GenSigSendType" SG_ 1126 IEMTestFr3Byte3 0;
BA_ "GenSigSendType" SG_ 1126 IEMTestFr3Byte4 0;
BA_ "GenSigSendType" SG_ 1126 IEMTestFr3Byte5 0;
BA_ "GenSigSendType" SG_ 1126 IEMTestFr3Byte6 0;
BA_ "GenSigSendType" SG_ 1126 IEMTestFr3Byte7 0;
// Frame: IemPropNMFr
BA_ "GenMsgSendType" BO_ 1308 1;
BA_ "GenMsgDelayTime" BO_ 1308 20.000;
BA_ "GenMsgILSupport" BO_ 1308 0;
BA_ "NmAsrMessage" BO_ 1308 1;
// Frame: IemToVddmPropDiagResFrame
BA_ "GenMsgSendType" BO_ 1591 1;
BA_ "GenMsgDelayTime" BO_ 1591 5.000;
// Frame: IemToVgmJ1979OBDPropCanResFrame11
BA_ "GenMsgSendType" BO_ 2027 1;
BA_ "GenMsgDelayTime" BO_ 2027 5.000;
// Frame: IgmMgmPropFr02
BA_ "GenMsgSendType" BO_ 629 0;
BA_ "GenMsgCycleTime" BO_ 629 160.000;
BA_ "GenSigSendType" SG_ 629 IsgClrRdyReq 0;
BA_ "GenSigSendType" SG_ 629 IsgCoolgReqInvr 0;
BA_ "GenSigSendType" SG_ 629 IsgCooltFlowMinReq 0;
BA_ "GenSigStartValue" SG_ 629 IsgInvrT 50;
BA_ "GenSigSendType" SG_ 629 IsgInvrT 0;
BA_ "GenSigSendType" SG_ 629 IsgNetIntlHeatg 0;
BA_ "GenSigStartValue" SG_ 629 IsgThermPwrMaxReq 10;
BA_ "GenSigSendType" SG_ 629 IsgThermPwrMaxReq 0;
BA_ "GenSigStartValue" SG_ 629 IsgThermPwrMinReq -10;
BA_ "GenSigSendType" SG_ 629 IsgThermPwrMinReq 0;
// Frame: IgmMgmPropFr03
BA_ "GenMsgSendType" BO_ 314 0;
BA_ "GenMsgCycleTime" BO_ 314 20.000;
BA_ "GenSigStartValue" SG_ 314 IsgCooltT 40;
BA_ "GenSigSendType" SG_ 314 IsgCooltT 0;
BA_ "GenSigStartValue" SG_ 314 IsgIDc 8188;
BA_ "GenSigSendType" SG_ 314 IsgIDc 0;
BA_ "GenSigStartValue" SG_ 314 IsgMotT 50;
BA_ "GenSigSendType" SG_ 314 IsgMotT 0;
BA_ "GenSigStartValue" SG_ 314 IsgTqAvlMax 8188;
BA_ "GenSigSendType" SG_ 314 IsgTqAvlMax 0;
BA_ "GenSigStartValue" SG_ 314 IsgTqAvlMin 8188;
BA_ "GenSigSendType" SG_ 314 IsgTqAvlMin 0;
// Frame: IgmMgmPropFr04
BA_ "GenMsgSendType" BO_ 625 0;
BA_ "GenMsgCycleTime" BO_ 625 80.000;
BA_ "GenSigSendType" SG_ 625 ImobEngChk3ImobEngChkSts 0;
BA_ "GenSigSendType" SG_ 625 ImobEngChk3ImobEngDataChk0 0;
BA_ "GenSigSendType" SG_ 625 ImobEngChk3ImobEngDataChk1 0;
BA_ "GenSigSendType" SG_ 625 ImobEngChk3ImobEngDataChk2 0;
BA_ "GenSigSendType" SG_ 625 ImobEngChk3ImobEngDataChk3 0;
BA_ "GenSigSendType" SG_ 625 ImobEngChk3ImobEngDataChk4 0;
BA_ "GenSigSendType" SG_ 625 ImobEngChk3ImobEngDataChk5 0;
BA_ "GenSigSendType" SG_ 625 ImobEngChk3ImobEngDataChk6 0;
BA_ "GenSigSendType" SG_ 625 ImobEngSts3 0;
// Frame: IgmMgmPropFr05
BA_ "GenMsgSendType" BO_ 342 0;
BA_ "GenMsgCycleTime" BO_ 342 25.000;
BA_ "GenSigSendType" SG_ 342 IsgLimnIndcn 0;
BA_ "GenSigSendType" SG_ 342 IsgUDc 0;
// Frame: IgmMgmPropFr06
BA_ "GenMsgSendType" BO_ 149 0;
BA_ "GenMsgCycleTime" BO_ 149 10.000;
BA_ "GenSigSendType" SG_ 149 IsgModSts 0;
BA_ "GenSigSendType" SG_ 149 IsgSpdActSgn 0;
BA_ "GenSigSendType" SG_ 149 IsgTqActChks 0;
BA_ "GenSigFuncType" SG_ 149 IsgTqActChks 15;
BA_ "GenSigDataID" SG_ 149 IsgTqActChks "0x46";
BA_ "GenSigSendType" SG_ 149 IsgTqActCntr 0;
BA_ "GenSigFuncType" SG_ 149 IsgTqActCntr 16;
BA_ "GenSigStartValue" SG_ 149 IsgTqActIsgTqAct 8188;
BA_ "GenSigSendType" SG_ 149 IsgTqActIsgTqAct 0;
BA_ "GenSigStartValue" SG_ 149 IsgTqActQualityFactor 1;
BA_ "GenSigSendType" SG_ 149 IsgTqActQualityFactor 0;
// Frame: IgmMgmPropFr07
BA_ "GenMsgSendType" BO_ 627 0;
BA_ "GenMsgCycleTime" BO_ 627 100.000;
BA_ "GenSigSendType" SG_ 627 IgmGenericADAlrmSt 0;
BA_ "GenSigSendType" SG_ 627 IgmGenericDTCHig 0;
BA_ "GenSigSendType" SG_ 627 IgmGenericDTCLow 0;
BA_ "GenSigSendType" SG_ 627 IgmGenericDTCMid 0;
BA_ "GenSigSendType" SG_ 627 IgmGenericDTCSts 0;
BA_ "GenSigSendType" SG_ 627 IgmGenericEMQnty 0;
BA_ "GenSigSendType" SG_ 627 IgmGenericEMSeqNr 0;
BA_ "GenSigSendType" SG_ 627 IgmGenericFltAlrmSt 0;
BA_ "GenSigSendType" SG_ 627 IgmGenericIacAlrmSt 0;
BA_ "GenSigSendType" SG_ 627 IgmGenericInvrtTAlrmSt 0;
BA_ "GenSigStartValue" SG_ 627 IgmGenericModStatusRms 3;
BA_ "GenSigSendType" SG_ 627 IgmGenericModStatusRms 0;
BA_ "GenSigSendType" SG_ 627 IgmGenericMotTAlrmSt 0;
BA_ "GenSigSendType" SG_ 627 IgmGenericResd1 0;
BA_ "GenSigSendType" SG_ 627 IgmGenericRslAlrmSt 0;
BA_ "GenSigSendType" SG_ 627 IgmGenericSpdAlrmSt 0;
BA_ "GenSigSendType" SG_ 627 IgmGenericUDcAlrmSt 0;
// Frame: IgmPropFr01
BA_ "GenMsgSendType" BO_ 660 0;
BA_ "GenMsgCycleTime" BO_ 660 500.000;
BA_ "GenSigSendType" SG_ 660 IsgErrIndcnReq 0;
BA_ "GenSigSendType" SG_ 660 IsgMotCooltFlowReq 0;
BA_ "GenSigSendType" SG_ 660 IsgMotCooltTFlg 0;
// Frame: IgmPropFr03
BA_ "GenMsgSendType" BO_ 1127 0;
BA_ "GenMsgCycleTime" BO_ 1127 800.000;
BA_ "GenSigSendType" SG_ 1127 IGMTestFr1Byte0 0;
BA_ "GenSigSendType" SG_ 1127 IGMTestFr1Byte1 0;
BA_ "GenSigSendType" SG_ 1127 IGMTestFr1Byte2 0;
BA_ "GenSigSendType" SG_ 1127 IGMTestFr1Byte3 0;
BA_ "GenSigSendType" SG_ 1127 IGMTestFr1Byte4 0;
BA_ "GenSigSendType" SG_ 1127 IGMTestFr1Byte5 0;
BA_ "GenSigSendType" SG_ 1127 IGMTestFr1Byte6 0;
BA_ "GenSigSendType" SG_ 1127 IGMTestFr1Byte7 0;
// Frame: IgmPropFr04
BA_ "GenMsgSendType" BO_ 1129 0;
BA_ "GenMsgCycleTime" BO_ 1129 800.000;
BA_ "GenSigSendType" SG_ 1129 IGMTestFr2Byte0 0;
BA_ "GenSigSendType" SG_ 1129 IGMTestFr2Byte1 0;
BA_ "GenSigSendType" SG_ 1129 IGMTestFr2Byte2 0;
BA_ "GenSigSendType" SG_ 1129 IGMTestFr2Byte3 0;
BA_ "GenSigSendType" SG_ 1129 IGMTestFr2Byte4 0;
BA_ "GenSigSendType" SG_ 1129 IGMTestFr2Byte5 0;
BA_ "GenSigSendType" SG_ 1129 IGMTestFr2Byte6 0;
BA_ "GenSigSendType" SG_ 1129 IGMTestFr2Byte7 0;
// Frame: IgmPropNMFr
BA_ "GenMsgSendType" BO_ 1307 1;
BA_ "GenMsgDelayTime" BO_ 1307 20.000;
BA_ "GenMsgILSupport" BO_ 1307 0;
BA_ "NmAsrMessage" BO_ 1307 1;
// Frame: IgmToVddmPropDiagResFrame
BA_ "GenMsgSendType" BO_ 1590 1;
BA_ "GenMsgDelayTime" BO_ 1590 5.000;
// Frame: IgmToVgmJ1979OBDPropCanResFrame11
BA_ "GenMsgSendType" BO_ 2028 1;
BA_ "GenMsgDelayTime" BO_ 2028 5.000;
// Frame: IsgmPropFr04
BA_ "GenMsgSendType" BO_ 90 0;
BA_ "GenMsgCycleTime" BO_ 90 10.000;
BA_ "GenSigStartValue" SG_ 90 MvIsgIDc 410;
BA_ "GenSigSendType" SG_ 90 MvIsgIDc 0;
BA_ "GenSigStartValue" SG_ 90 MvIsgTqAvlIsgTqAvlMax 110;
BA_ "GenSigSendType" SG_ 90 MvIsgTqAvlIsgTqAvlMax 0;
BA_ "GenSigStartValue" SG_ 90 MvIsgTqAvlIsgTqAvlMin 30;
BA_ "GenSigSendType" SG_ 90 MvIsgTqAvlIsgTqAvlMin 0;
BA_ "GenSigSendType" SG_ 90 MvIsgTqNegAvlTra 0;
BA_ "GenSigSendType" SG_ 90 MvIsgTqPosAvlTra 0;
BA_ "GenSigSendType" SG_ 90 MvIsgTRate 0;
BA_ "GenSigSendType" SG_ 90 MvIsgUDc 0;
// Frame: IsgmPropFr05
BA_ "GenMsgSendType" BO_ 358 0;
BA_ "GenMsgCycleTime" BO_ 358 20.000;
BA_ "GenSigSendType" SG_ 358 MvIsgLimnIndcn 0;
BA_ "GenSigSendType" SG_ 358 MvIsgModSts 0;
BA_ "GenSigSendType" SG_ 358 MvIsgRstrtSts 0;
BA_ "GenSigStartValue" SG_ 358 MvIsgSpdAct 10000;
BA_ "GenSigSendType" SG_ 358 MvIsgSpdAct 0;
BA_ "GenSigStartValue" SG_ 358 MvIsgTqActMvIsgTq 700;
BA_ "GenSigSendType" SG_ 358 MvIsgTqActMvIsgTq 0;
BA_ "GenSigSendType" SG_ 358 MvIsgTqActMvIsgTqChks 0;
BA_ "GenSigFuncType" SG_ 358 MvIsgTqActMvIsgTqChks 15;
BA_ "GenSigDataID" SG_ 358 MvIsgTqActMvIsgTqChks "0x05";
BA_ "GenSigSendType" SG_ 358 MvIsgTqActMvIsgTqCntr 0;
BA_ "GenSigFuncType" SG_ 358 MvIsgTqActMvIsgTqCntr 16;
BA_ "GenSigSendType" SG_ 358 MvIsgTqActQualityFactor 0;
// Frame: IsgmPropFr07
BA_ "GenMsgSendType" BO_ 897 0;
BA_ "GenMsgCycleTime" BO_ 897 200.000;
BA_ "GenSigSendType" SG_ 897 MvIsgFltState1MvIsgIvtrThermProtn 0;
BA_ "GenSigSendType" SG_ 897 MvIsgFltState1MvIsgLoadDump 0;
BA_ "GenSigSendType" SG_ 897 MvIsgFltState1MvIsgNegSpdDetn 0;
BA_ "GenSigSendType" SG_ 897 MvIsgFltState1MvIsgOvrheatg 0;
BA_ "GenSigSendType" SG_ 897 MvIsgFltState1MvIsgPwrLimn 0;
BA_ "GenSigSendType" SG_ 897 MvIsgFltState1MvIsgStrtrModWarn 0;
BA_ "GenSigSendType" SG_ 897 MvIsgFltState1MvIsgULo 0;
BA_ "GenSigSendType" SG_ 897 MvIsgFltState1MvIsgUOvld 0;
BA_ "GenSigSendType" SG_ 897 MvIsgFltState2MvIsgBrushWearUDrpFlt 0;
BA_ "GenSigSendType" SG_ 897 MvIsgFltState2MvIsgCanFlt 0;
BA_ "GenSigSendType" SG_ 897 MvIsgFltState2MvIsgExctCircHiSideFlt 0;
BA_ "GenSigSendType" SG_ 897 MvIsgFltState2MvIsgIOvld 0;
BA_ "GenSigSendType" SG_ 897 MvIsgFltState2MvIsgPwrModuleIvtrFlt 0;
BA_ "GenSigSendType" SG_ 897 MvIsgFltState2MvIsgPwrModuleStrtrFlt 0;
BA_ "GenSigSendType" SG_ 897 MvIsgFltState2MvIsgRotorIOvld 0;
BA_ "GenSigSendType" SG_ 897 MvIsgFltState2MvIsgTqLvlFlt 0;
BA_ "GenSigSendType" SG_ 897 MvIsgFltState3BattUHi 0;
BA_ "GenSigSendType" SG_ 897 MvIsgFltState3BattULo 0;
BA_ "GenSigSendType" SG_ 897 MvIsgFltState3MvIsg48vVSClOc 0;
BA_ "GenSigSendType" SG_ 897 MvIsgFltState3MvIsgExctCircLatentFlt 0;
BA_ "GenSigSendType" SG_ 897 MvIsgFltState3MvIsgRotorOpenCircFlt 0;
BA_ "GenSigSendType" SG_ 897 MvIsgFltState3MvIsgRPSCh 0;
BA_ "GenSigSendType" SG_ 897 MvIsgFltState3MvIsgRPSClOc 0;
BA_ "GenSigSendType" SG_ 897 MvIsgFltState3MvIsgRvsSpdFlt 0;
BA_ "GenSigSendType" SG_ 897 MvIsgFltState4MvIsg48vVSCh 0;
BA_ "GenSigSendType" SG_ 897 MvIsgFltState4MvIsgECSCh 0;
BA_ "GenSigSendType" SG_ 897 MvIsgFltState4MvIsgECSClOc 0;
BA_ "GenSigSendType" SG_ 897 MvIsgFltState4MvIsgPCSCl 0;
BA_ "GenSigSendType" SG_ 897 MvIsgFltState4MvIsgPCSOc 0;
BA_ "GenSigSendType" SG_ 897 MvIsgFltState4MvIsgTECl 0;
BA_ "GenSigSendType" SG_ 897 MvIsgFltState4MvIsgTPCBChOc 0;
BA_ "GenSigSendType" SG_ 897 MvIsgFltState4MvIsgTPCBCl 0;
BA_ "GenSigSendType" SG_ 897 MvIsgFltState5MvIsgPMSClCh 0;
BA_ "GenSigSendType" SG_ 897 MvIsgFltState5MvIsgPMSOc 0;
BA_ "GenSigSendType" SG_ 897 MvIsgFltState5MvIsgRotorPosnTrackingLoopFlt 0;
BA_ "GenSigSendType" SG_ 897 MvIsgFltState5MvIsgRPSOc 0;
BA_ "GenSigSendType" SG_ 897 MvIsgFltState5MvIsgTEChOc 0;
// Frame: IsgmPropNMFr
BA_ "GenMsgSendType" BO_ 1316 1;
BA_ "GenMsgDelayTime" BO_ 1316 20.000;
BA_ "GenMsgILSupport" BO_ 1316 0;
BA_ "NmAsrMessage" BO_ 1316 1;
// Frame: IsgmtoEtcXCPFr01
BA_ "GenMsgSendType" BO_ 1419 1;
BA_ "GenMsgDelayTime" BO_ 1419 5.000;
// Frame: IsgmToVddmPropDiagResFrame
BA_ "GenMsgSendType" BO_ 1598 1;
BA_ "GenMsgDelayTime" BO_ 1598 5.000;
// Frame: IsgmToVgmJ1979OBDPropCanResFrame11
BA_ "GenMsgSendType" BO_ 2028 1;
BA_ "GenMsgDelayTime" BO_ 2028 5.000;
// Frame: MvbmPropDevFr01
BA_ "GenMsgSendType" BO_ 1478 1;
BA_ "GenMsgDelayTime" BO_ 1478 95.000;
BA_ "GenSigSendType" SG_ 1478 MVBMdevelpsignalgrouprespFunctiondevpsignalgroup1 1;
BA_ "GenSigSendType" SG_ 1478 MVBMdevelpsignalgrouprespFunctiondevpsignalgroup2 1;
BA_ "GenSigSendType" SG_ 1478 MVBMdevelpsignalgrouprespFunctiondevpsignalgroup3 1;
BA_ "GenSigSendType" SG_ 1478 MVBMdevelpsignalgrouprespFunctiondevpsignalgroup4 1;
BA_ "GenSigSendType" SG_ 1478 MVBMdevelpsignalgrouprespFunctiondevpsignalgroup5 1;
BA_ "GenSigSendType" SG_ 1478 MVBMdevelpsignalgrouprespFunctiondevpsignalgroup6 1;
BA_ "GenSigSendType" SG_ 1478 MVBMdevelpsignalgrouprespFunctiondevpsignalgroup7 1;
BA_ "GenSigSendType" SG_ 1478 MVBMdevelpsignalgrouprespFunctiondevpsignalgroup8 1;
// Frame: MvbmPropFr01
BA_ "GenMsgSendType" BO_ 408 0;
BA_ "GenMsgCycleTime" BO_ 408 50.000;
BA_ "GenSigSendType" SG_ 408 MvBattCellUMax 0;
BA_ "GenSigSendType" SG_ 408 MvBattCellUMin 0;
BA_ "GenSigSendType" SG_ 408 MvBattLimnIndcnChks 0;
BA_ "GenSigFuncType" SG_ 408 MvBattLimnIndcnChks 15;
BA_ "GenSigDataID" SG_ 408 MvBattLimnIndcnChks "0x03";
BA_ "GenSigSendType" SG_ 408 MvBattLimnIndcnCntr 0;
BA_ "GenSigFuncType" SG_ 408 MvBattLimnIndcnCntr 16;
BA_ "GenSigSendType" SG_ 408 MvBattLimnIndcnMvBattLimnIndcn 0;
BA_ "GenSigSendType" SG_ 408 MvBattMod 0;
// Frame: MvbmPropFr07
BA_ "GenMsgSendType" BO_ 630 0;
BA_ "GenMsgCycleTime" BO_ 630 100.000;
BA_ "GenSigSendType" SG_ 630 MvBattPwrLimChrg1 0;
BA_ "GenSigSendType" SG_ 630 MvBattPwrLimChrg2 0;
BA_ "GenSigStartValue" SG_ 630 MvBattPwrLimDcha1 4094;
BA_ "GenSigSendType" SG_ 630 MvBattPwrLimDcha1 0;
BA_ "GenSigStartValue" SG_ 630 MvBattPwrLimDcha2 4094;
BA_ "GenSigSendType" SG_ 630 MvBattPwrLimDcha2 0;
BA_ "GenSigSendType" SG_ 630 MvBattSoc 0;
// Frame: MvbmPropFr08
BA_ "GenMsgSendType" BO_ 106 0;
BA_ "GenMsgCycleTime" BO_ 106 20.000;
BA_ "GenSigSendType" SG_ 106 MvBattIDc 0;
BA_ "GenSigSendType" SG_ 106 MvBattRlyStsChks 0;
BA_ "GenSigFuncType" SG_ 106 MvBattRlyStsChks 15;
BA_ "GenSigDataID" SG_ 106 MvBattRlyStsChks "0x412";
BA_ "GenSigSendType" SG_ 106 MvBattRlyStsCntr 0;
BA_ "GenSigFuncType" SG_ 106 MvBattRlyStsCntr 16;
BA_ "GenSigSendType" SG_ 106 MvBattRlyStsMvBattRlySts 0;
BA_ "GenSigSendType" SG_ 106 MvBattUDc 0;
BA_ "GenSigSendType" SG_ 106 MvBattUDc2 0;
// Frame: MvbmPropFr10
BA_ "GenMsgSendType" BO_ 584 0;
BA_ "GenMsgCycleTime" BO_ 584 200.000;
BA_ "GenSigSendType" SG_ 584 MvBattFltState1MvBattBccComFlt 0;
BA_ "GenSigSendType" SG_ 584 MvBattFltState1MvBattBccFlt 0;
BA_ "GenSigSendType" SG_ 584 MvBattFltState1MvBattCellOvpFlt 0;
BA_ "GenSigSendType" SG_ 584 MvBattFltState1MvBattCellUvpFlt 0;
BA_ "GenSigSendType" SG_ 584 MvBattFltState1MvBattComFlt 0;
BA_ "GenSigSendType" SG_ 584 MvBattFltState1MvBattOcpFlt 0;
BA_ "GenSigSendType" SG_ 584 MvBattFltState1MvBattOvpFlt 0;
BA_ "GenSigSendType" SG_ 584 MvBattFltState1MvBattUvpFlt 0;
BA_ "GenSigSendType" SG_ 584 MvBattFltState2BattUHi 0;
BA_ "GenSigSendType" SG_ 584 MvBattFltState2BattULo 0;
BA_ "GenSigSendType" SG_ 584 MvBattFltState2MvBattCbClsFlt 0;
BA_ "GenSigSendType" SG_ 584 MvBattFltState2MvBattCellUSampleFlt 0;
BA_ "GenSigSendType" SG_ 584 MvBattFltState2MvBattISampleFlt 0;
BA_ "GenSigSendType" SG_ 584 MvBattFltState2MvBattPrecFail 0;
BA_ "GenSigSendType" SG_ 584 MvBattFltState2MvBattTSGND 0;
BA_ "GenSigSendType" SG_ 584 MvBattFltState2MvBattTSPWR 0;
BA_ "GenSigSendType" SG_ 584 MvBattFltState3MvBattCVSGND 0;
BA_ "GenSigSendType" SG_ 584 MvBattFltState3MvBattCVSOc 0;
BA_ "GenSigSendType" SG_ 584 MvBattFltState3MvBattCVSOOR 0;
BA_ "GenSigSendType" SG_ 584 MvBattFltState3MvBattCVSPWR 0;
BA_ "GenSigSendType" SG_ 584 MvBattFltState3MvBattPVSGND 0;
BA_ "GenSigSendType" SG_ 584 MvBattFltState3MvBattPVSOc 0;
BA_ "GenSigSendType" SG_ 584 MvBattFltState3MvBattPVSPWR 0;
BA_ "GenSigSendType" SG_ 584 MvBattFltState3MvBattTSOOR 0;
BA_ "GenSigSendType" SG_ 584 MvBattFltState4MvBattCSGND 0;
BA_ "GenSigSendType" SG_ 584 MvBattFltState4MvBattCSOc 0;
BA_ "GenSigSendType" SG_ 584 MvBattFltState4MvBattCSOOR 0;
BA_ "GenSigSendType" SG_ 584 MvBattFltState4MvBattPVSOOR 0;
BA_ "GenSigSendType" SG_ 584 MvBattFltState4MvBattTVSGND 0;
BA_ "GenSigSendType" SG_ 584 MvBattFltState4MvBattTVSOOR 0;
BA_ "GenSigSendType" SG_ 584 MvBattFltState4MvBattTVSPWR 0;
// Frame: MvbmPropFr12
BA_ "GenMsgSendType" BO_ 1151 0;
BA_ "GenMsgCycleTime" BO_ 1151 1000.000;
BA_ "GenSigSendType" SG_ 1151 MvBattEgyCdn 0;
BA_ "GenSigSendType" SG_ 1151 MvBattTAvg 0;
BA_ "GenSigSendType" SG_ 1151 MvBattTMax 0;
BA_ "GenSigSendType" SG_ 1151 MvBattTMin 0;
// Frame: MvbmPropNMFr
BA_ "GenMsgSendType" BO_ 1314 1;
BA_ "GenMsgDelayTime" BO_ 1314 20.000;
BA_ "GenMsgILSupport" BO_ 1314 0;
BA_ "NmAsrMessage" BO_ 1314 1;
// Frame: MvbmToVddmPropDiagResFrame
BA_ "GenMsgSendType" BO_ 1618 1;
BA_ "GenMsgDelayTime" BO_ 1618 5.000;
// Frame: MvemToVgmJ1979OBDPropCanResFrame11
BA_ "GenMsgSendType" BO_ 2027 1;
BA_ "GenMsgDelayTime" BO_ 2027 5.000;
VAL_ 634 DenoOfDiagcRateGen 0 "Boolean_FALSE" 1 "Boolean_TRUE";
VAL_ 634 DrvgCyc 0 "OnOff1_Off" 1 "OnOff1_On";
VAL_ 634 DrvgCycToClrPrmntDtc 0 "Boolean_FALSE" 1 "Boolean_TRUE";
VAL_ 634 IuprDenominatorInhb 0 "InhibitSts_NotInhibited" 1 "InhibitSts_Inhibited";
VAL_ 1347 VFCVectorECMVFCid0 0 "VFCOnOff_Off" 1 "VFCOnOff_On";
VAL_ 1347 VFCVectorECMVFCid1 0 "VFCOnOff_Off" 1 "VFCOnOff_On";
VAL_ 1347 VFCVectorECMVFCid10 0 "VFCOnOff_Off" 1 "VFCOnOff_On";
VAL_ 1347 VFCVectorECMVFCid11 0 "VFCOnOff_Off" 1 "VFCOnOff_On";
VAL_ 1347 VFCVectorECMVFCid12 0 "VFCOnOff_Off" 1 "VFCOnOff_On";
VAL_ 1347 VFCVectorECMVFCid13 0 "VFCOnOff_Off" 1 "VFCOnOff_On";
VAL_ 1347 VFCVectorECMVFCid14 0 "VFCOnOff_Off" 1 "VFCOnOff_On";
VAL_ 1347 VFCVectorECMVFCid15 0 "VFCOnOff_Off" 1 "VFCOnOff_On";
VAL_ 1347 VFCVectorECMVFCid16 0 "VFCOnOff_Off" 1 "VFCOnOff_On";
VAL_ 1347 VFCVectorECMVFCid17 0 "VFCOnOff_Off" 1 "VFCOnOff_On";
VAL_ 1347 VFCVectorECMVFCid18 0 "VFCOnOff_Off" 1 "VFCOnOff_On";
VAL_ 1347 VFCVectorECMVFCid19 0 "VFCOnOff_Off" 1 "VFCOnOff_On";
VAL_ 1347 VFCVectorECMVFCid2 0 "VFCOnOff_Off" 1 "VFCOnOff_On";
VAL_ 1347 VFCVectorECMVFCid20 0 "VFCOnOff_Off" 1 "VFCOnOff_On";
VAL_ 1347 VFCVectorECMVFCid21 0 "VFCOnOff_Off" 1 "VFCOnOff_On";
VAL_ 1347 VFCVectorECMVFCid22 0 "VFCOnOff_Off" 1 "VFCOnOff_On";
VAL_ 1347 VFCVectorECMVFCid23 0 "VFCOnOff_Off" 1 "VFCOnOff_On";
VAL_ 1347 VFCVectorECMVFCid24 0 "VFCOnOff_Off" 1 "VFCOnOff_On";
VAL_ 1347 VFCVectorECMVFCid25 0 "VFCOnOff_Off" 1 "VFCOnOff_On";
VAL_ 1347 VFCVectorECMVFCid26 0 "VFCOnOff_Off" 1 "VFCOnOff_On";
VAL_ 1347 VFCVectorECMVFCid27 0 "VFCOnOff_Off" 1 "VFCOnOff_On";
VAL_ 1347 VFCVectorECMVFCid28 0 "VFCOnOff_Off" 1 "VFCOnOff_On";
VAL_ 1347 VFCVectorECMVFCid29 0 "VFCOnOff_Off" 1 "VFCOnOff_On";
VAL_ 1347 VFCVectorECMVFCid3 0 "VFCOnOff_Off" 1 "VFCOnOff_On";
VAL_ 1347 VFCVectorECMVFCid30 0 "VFCOnOff_Off" 1 "VFCOnOff_On";
VAL_ 1347 VFCVectorECMVFCid31 0 "VFCOnOff_Off" 1 "VFCOnOff_On";
VAL_ 1347 VFCVectorECMVFCid32 0 "VFCOnOff_Off" 1 "VFCOnOff_On";
VAL_ 1347 VFCVectorECMVFCid33 0 "VFCOnOff_Off" 1 "VFCOnOff_On";
VAL_ 1347 VFCVectorECMVFCid34 0 "VFCOnOff_Off" 1 "VFCOnOff_On";
VAL_ 1347 VFCVectorECMVFCid35 0 "VFCOnOff_Off" 1 "VFCOnOff_On";
VAL_ 1347 VFCVectorECMVFCid36 0 "VFCOnOff_Off" 1 "VFCOnOff_On";
VAL_ 1347 VFCVectorECMVFCid37 0 "VFCOnOff_Off" 1 "VFCOnOff_On";
VAL_ 1347 VFCVectorECMVFCid38 0 "VFCOnOff_Off" 1 "VFCOnOff_On";
VAL_ 1347 VFCVectorECMVFCid39 0 "VFCOnOff_Off" 1 "VFCOnOff_On";
VAL_ 1347 VFCVectorECMVFCid4 0 "VFCOnOff_Off" 1 "VFCOnOff_On";
VAL_ 1347 VFCVectorECMVFCid40 0 "VFCOnOff_Off" 1 "VFCOnOff_On";
VAL_ 1347 VFCVectorECMVFCid41 0 "VFCOnOff_Off" 1 "VFCOnOff_On";
VAL_ 1347 VFCVectorECMVFCid42 0 "VFCOnOff_Off" 1 "VFCOnOff_On";
VAL_ 1347 VFCVectorECMVFCid43 0 "VFCOnOff_Off" 1 "VFCOnOff_On";
VAL_ 1347 VFCVectorECMVFCid44 0 "VFCOnOff_Off" 1 "VFCOnOff_On";
VAL_ 1347 VFCVectorECMVFCid45 0 "VFCOnOff_Off" 1 "VFCOnOff_On";
VAL_ 1347 VFCVectorECMVFCid46 0 "VFCOnOff_Off" 1 "VFCOnOff_On";
VAL_ 1347 VFCVectorECMVFCid47 0 "VFCOnOff_Off" 1 "VFCOnOff_On";
VAL_ 1347 VFCVectorECMVFCid48 0 "VFCOnOff_Off" 1 "VFCOnOff_On";
VAL_ 1347 VFCVectorECMVFCid49 0 "VFCOnOff_Off" 1 "VFCOnOff_On";
VAL_ 1347 VFCVectorECMVFCid5 0 "VFCOnOff_Off" 1 "VFCOnOff_On";
VAL_ 1347 VFCVectorECMVFCid50 0 "VFCOnOff_Off" 1 "VFCOnOff_On";
VAL_ 1347 VFCVectorECMVFCid51 0 "VFCOnOff_Off" 1 "VFCOnOff_On";
VAL_ 1347 VFCVectorECMVFCid52 0 "VFCOnOff_Off" 1 "VFCOnOff_On";
VAL_ 1347 VFCVectorECMVFCid53 0 "VFCOnOff_Off" 1 "VFCOnOff_On";
VAL_ 1347 VFCVectorECMVFCid54 0 "VFCOnOff_Off" 1 "VFCOnOff_On";
VAL_ 1347 VFCVectorECMVFCid55 0 "VFCOnOff_Off" 1 "VFCOnOff_On";
VAL_ 1347 VFCVectorECMVFCid56 0 "VFCOnOff_Off" 1 "VFCOnOff_On";
VAL_ 1347 VFCVectorECMVFCid57 0 "VFCOnOff_Off" 1 "VFCOnOff_On";
VAL_ 1347 VFCVectorECMVFCid58 0 "VFCOnOff_Off" 1 "VFCOnOff_On";
VAL_ 1347 VFCVectorECMVFCid59 0 "VFCOnOff_Off" 1 "VFCOnOff_On";
VAL_ 1347 VFCVectorECMVFCid6 0 "VFCOnOff_Off" 1 "VFCOnOff_On";
VAL_ 1347 VFCVectorECMVFCid60 0 "VFCOnOff_Off" 1 "VFCOnOff_On";
VAL_ 1347 VFCVectorECMVFCid61 0 "VFCOnOff_Off" 1 "VFCOnOff_On";
VAL_ 1347 VFCVectorECMVFCid7 0 "VFCOnOff_Off" 1 "VFCOnOff_On";
VAL_ 1347 VFCVectorECMVFCid8 0 "VFCOnOff_Off" 1 "VFCOnOff_On";
VAL_ 1347 VFCVectorECMVFCid9 0 "VFCOnOff_Off" 1 "VFCOnOff_On";
VAL_ 401 WhlMotSysActvDampgModReq 0 "WhlMotSysActvDampgModCodSts_NoDampg" 1 "WhlMotSysActvDampgModCodSts_LoDampg" 2 "WhlMotSysActvDampgModCodSts_MedDampg" 3 "WhlMotSysActvDampgModCodSts_HiDampg";
VAL_ 649 EngOnReq 0 "OnOff1_Off" 1 "OnOff1_On";
VAL_ 309 DrvrGearShiftManReqDwnDwnTipReq 0 "DwnDwnTipReq_NotActv" 1 "DwnDwnTipReq_Actv";
VAL_ 309 DrvrGearShiftManReqDwnTipReq 0 "DwnTipReq_DwnTipReqNotActv" 1 "DwnTipReq_DwnTipReqActv";
VAL_ 309 DrvrGearShiftManReqSteerWhlDwnReq1 0 "SteerWhlDwnReq1_SteerWhlDwnReqNotActv" 1 "SteerWhlDwnReq1_SteerWhlDwnReqActv";
VAL_ 309 DrvrGearShiftManReqSteerWhlUpReq 0 "SteerWhlUpReq_SteerWhlUpReqNotActv" 1 "SteerWhlUpReq_SteerWhlUpReqActv";
VAL_ 309 DrvrGearShiftManReqTipReq1 0 "TipReq1_TipReqNotActv" 1 "TipReq1_TipReqActv";
VAL_ 309 DrvrGearShiftManReqUpTipReq1 0 "UpTipReq1_UpTipReqNotActv" 1 "UpTipReq1_UpTipReqActv";
VAL_ 309 DrvrGearShiftManReqUpUpTipReq 0 "UpUpTipReq_NotActv" 1 "UpUpTipReq_Actv";
VAL_ 309 DrvrGearShiftParkReq1 0 "SwtPark1_SwtParkNotActv" 1 "SwtPark1_SwtParkActv";
VAL_ 309 DrvrGearShiftParkReqSts 0 "ClutchPedlPsd_No" 1 "ClutchPedlPsd_Yes" 2 "ClutchPedlPsd_Reserved1" 3 "ClutchPedlPsd_Reserved2";
VAL_ 309 GearLock 0 "ActvInActv_Active" 1 "ActvInActv_Inactive";
VAL_ 309 GearShiftUnitSts 0 "NoFlt" 1 "NoUpTipAut" 2 "NoDwnTipAut" 3 "NoPark" 4 "SrvRqrd" 5 "NoUpUpTipAut" 6 "NoDownDownTipAut" 7 "Nounlock";
VAL_ 310 DrvrGearShiftDirReq1DwnDwnTipAut 0 "NotActvActv1_NotActv" 1 "NotActvActv1_Actv";
VAL_ 310 DrvrGearShiftDirReq1DwnTipAut 0 "DwnTipAut1_DwnTipAutNotActv" 1 "DwnTipAut1_DwnTipAutActv";
VAL_ 310 DrvrGearShiftDirReq1PosnAut 0 "PosnAut_PosnAutNotActv" 1 "PosnAut_PosnAutActv";
VAL_ 310 DrvrGearShiftDirReq1UpTipAut 0 "UpTipAut1_UpTipAutNotActv" 1 "UpTipAut1_UpTipAutActv";
VAL_ 310 DrvrGearShiftDirReq1UpUpTipAut 0 "NotActvActv1_NotActv" 1 "NotActvActv1_Actv";
VAL_ 310 DrvrGearShiftDirReq2DwnDwnTipAut 0 "NotActvActv1_NotActv" 1 "NotActvActv1_Actv";
VAL_ 310 DrvrGearShiftDirReq2DwnTipAut 0 "DwnTipAut1_DwnTipAutNotActv" 1 "DwnTipAut1_DwnTipAutActv";
VAL_ 310 DrvrGearShiftDirReq2PosnAut 0 "PosnAut_PosnAutNotActv" 1 "PosnAut_PosnAutActv";
VAL_ 310 DrvrGearShiftDirReq2UpTipAut 0 "UpTipAut1_UpTipAutNotActv" 1 "UpTipAut1_UpTipAutActv";
VAL_ 310 DrvrGearShiftDirReq2UpUpTipAut 0 "NotActvActv1_NotActv" 1 "NotActvActv1_Actv";
VAL_ 1349 VFCVectorEGSMVFCid0 0 "VFCOnOff_Off" 1 "VFCOnOff_On";
VAL_ 1349 VFCVectorEGSMVFCid1 0 "VFCOnOff_Off" 1 "VFCOnOff_On";
VAL_ 1349 VFCVectorEGSMVFCid10 0 "VFCOnOff_Off" 1 "VFCOnOff_On";
VAL_ 1349 VFCVectorEGSMVFCid11 0 "VFCOnOff_Off" 1 "VFCOnOff_On";
VAL_ 1349 VFCVectorEGSMVFCid12 0 "VFCOnOff_Off" 1 "VFCOnOff_On";
VAL_ 1349 VFCVectorEGSMVFCid13 0 "VFCOnOff_Off" 1 "VFCOnOff_On";
VAL_ 1349 VFCVectorEGSMVFCid14 0 "VFCOnOff_Off" 1 "VFCOnOff_On";
VAL_ 1349 VFCVectorEGSMVFCid15 0 "VFCOnOff_Off" 1 "VFCOnOff_On";
VAL_ 1349 VFCVectorEGSMVFCid16 0 "VFCOnOff_Off" 1 "VFCOnOff_On";
VAL_ 1349 VFCVectorEGSMVFCid17 0 "VFCOnOff_Off" 1 "VFCOnOff_On";
VAL_ 1349 VFCVectorEGSMVFCid18 0 "VFCOnOff_Off" 1 "VFCOnOff_On";
VAL_ 1349 VFCVectorEGSMVFCid19 0 "VFCOnOff_Off" 1 "VFCOnOff_On";
VAL_ 1349 VFCVectorEGSMVFCid2 0 "VFCOnOff_Off" 1 "VFCOnOff_On";
VAL_ 1349 VFCVectorEGSMVFCid20 0 "VFCOnOff_Off" 1 "VFCOnOff_On";
VAL_ 1349 VFCVectorEGSMVFCid21 0 "VFCOnOff_Off" 1 "VFCOnOff_On";
VAL_ 1349 VFCVectorEGSMVFCid22 0 "VFCOnOff_Off" 1 "VFCOnOff_On";
VAL_ 1349 VFCVectorEGSMVFCid23 0 "VFCOnOff_Off" 1 "VFCOnOff_On";
VAL_ 1349 VFCVectorEGSMVFCid24 0 "VFCOnOff_Off" 1 "VFCOnOff_On";
VAL_ 1349 VFCVectorEGSMVFCid25 0 "VFCOnOff_Off" 1 "VFCOnOff_On";
VAL_ 1349 VFCVectorEGSMVFCid26 0 "VFCOnOff_Off" 1 "VFCOnOff_On";
VAL_ 1349 VFCVectorEGSMVFCid27 0 "VFCOnOff_Off" 1 "VFCOnOff_On";
VAL_ 1349 VFCVectorEGSMVFCid28 0 "VFCOnOff_Off" 1 "VFCOnOff_On";
VAL_ 1349 VFCVectorEGSMVFCid29 0 "VFCOnOff_Off" 1 "VFCOnOff_On";
VAL_ 1349 VFCVectorEGSMVFCid3 0 "VFCOnOff_Off" 1 "VFCOnOff_On";
VAL_ 1349 VFCVectorEGSMVFCid30 0 "VFCOnOff_Off" 1 "VFCOnOff_On";
VAL_ 1349 VFCVectorEGSMVFCid31 0 "VFCOnOff_Off" 1 "VFCOnOff_On";
VAL_ 1349 VFCVectorEGSMVFCid32 0 "VFCOnOff_Off" 1 "VFCOnOff_On";
VAL_ 1349 VFCVectorEGSMVFCid33 0 "VFCOnOff_Off" 1 "VFCOnOff_On";
VAL_ 1349 VFCVectorEGSMVFCid34 0 "VFCOnOff_Off" 1 "VFCOnOff_On";
VAL_ 1349 VFCVectorEGSMVFCid35 0 "VFCOnOff_Off" 1 "VFCOnOff_On";
VAL_ 1349 VFCVectorEGSMVFCid36 0 "VFCOnOff_Off" 1 "VFCOnOff_On";
VAL_ 1349 VFCVectorEGSMVFCid37 0 "VFCOnOff_Off" 1 "VFCOnOff_On";
VAL_ 1349 VFCVectorEGSMVFCid38 0 "VFCOnOff_Off" 1 "VFCOnOff_On";
VAL_ 1349 VFCVectorEGSMVFCid39 0 "VFCOnOff_Off" 1 "VFCOnOff_On";
VAL_ 1349 VFCVectorEGSMVFCid4 0 "VFCOnOff_Off" 1 "VFCOnOff_On";
VAL_ 1349 VFCVectorEGSMVFCid40 0 "VFCOnOff_Off" 1 "VFCOnOff_On";
VAL_ 1349 VFCVectorEGSMVFCid41 0 "VFCOnOff_Off" 1 "VFCOnOff_On";
VAL_ 1349 VFCVectorEGSMVFCid42 0 "VFCOnOff_Off" 1 "VFCOnOff_On";
VAL_ 1349 VFCVectorEGSMVFCid43 0 "VFCOnOff_Off" 1 "VFCOnOff_On";
VAL_ 1349 VFCVectorEGSMVFCid44 0 "VFCOnOff_Off" 1 "VFCOnOff_On";
VAL_ 1349 VFCVectorEGSMVFCid45 0 "VFCOnOff_Off" 1 "VFCOnOff_On";
VAL_ 1349 VFCVectorEGSMVFCid46 0 "VFCOnOff_Off" 1 "VFCOnOff_On";
VAL_ 1349 VFCVectorEGSMVFCid47 0 "VFCOnOff_Off" 1 "VFCOnOff_On";
VAL_ 1349 VFCVectorEGSMVFCid48 0 "VFCOnOff_Off" 1 "VFCOnOff_On";
VAL_ 1349 VFCVectorEGSMVFCid49 0 "VFCOnOff_Off" 1 "VFCOnOff_On";
VAL_ 1349 VFCVectorEGSMVFCid5 0 "VFCOnOff_Off" 1 "VFCOnOff_On";
VAL_ 1349 VFCVectorEGSMVFCid50 0 "VFCOnOff_Off" 1 "VFCOnOff_On";
VAL_ 1349 VFCVectorEGSMVFCid51 0 "VFCOnOff_Off" 1 "VFCOnOff_On";
VAL_ 1349 VFCVectorEGSMVFCid52 0 "VFCOnOff_Off" 1 "VFCOnOff_On";
VAL_ 1349 VFCVectorEGSMVFCid53 0 "VFCOnOff_Off" 1 "VFCOnOff_On";
VAL_ 1349 VFCVectorEGSMVFCid54 0 "VFCOnOff_Off" 1 "VFCOnOff_On";
VAL_ 1349 VFCVectorEGSMVFCid55 0 "VFCOnOff_Off" 1 "VFCOnOff_On";
VAL_ 1349 VFCVectorEGSMVFCid56 0 "VFCOnOff_Off" 1 "VFCOnOff_On";
VAL_ 1349 VFCVectorEGSMVFCid57 0 "VFCOnOff_Off" 1 "VFCOnOff_On";
VAL_ 1349 VFCVectorEGSMVFCid58 0 "VFCOnOff_Off" 1 "VFCOnOff_On";
VAL_ 1349 VFCVectorEGSMVFCid59 0 "VFCOnOff_Off" 1 "VFCOnOff_On";
VAL_ 1349 VFCVectorEGSMVFCid6 0 "VFCOnOff_Off" 1 "VFCOnOff_On";
VAL_ 1349 VFCVectorEGSMVFCid60 0 "VFCOnOff_Off" 1 "VFCOnOff_On";
VAL_ 1349 VFCVectorEGSMVFCid61 0 "VFCOnOff_Off" 1 "VFCOnOff_On";
VAL_ 1349 VFCVectorEGSMVFCid7 0 "VFCOnOff_Off" 1 "VFCOnOff_On";
VAL_ 1349 VFCVectorEGSMVFCid8 0 "VFCOnOff_Off" 1 "VFCOnOff_On";
VAL_ 1349 VFCVectorEGSMVFCid9 0 "VFCOnOff_Off" 1 "VFCOnOff_On";
VAL_ 801 ComLostExtrSoundFront 0 "Boolean_FALSE" 1 "Boolean_TRUE";
VAL_ 76 WhlMotSysModSts 0 "WhlMotSysModStsTyp2_Inin" 1 "WhlMotSysModStsTyp2_Stb" 2 "WhlMotSysModStsTyp2_TqCtrl" 3 "WhlMotSysModStsTyp2_SpdCtrlIdle" 4 "WhlMotSysModStsTyp2_CluOper" 5 "WhlMotSysModStsTyp2_PreChrg" 6 "WhlMotSysModStsTyp2_PwrDwn" 7 "WhlMotSysModStsTyp2_Flt" 8 "WhlMotSysModStsTyp2_TcsCtrl";
VAL_ 76 WhlMotSysTqEstQualityFactor 0 "QualityFactor_QfUndefd" 1 "QualityFactor_QfInProgs" 2 "QualityFactor_QfNotSpc" 3 "QualityFactor_QfSnsrDataOk";
VAL_ 96 ImobEngSts2 0 "ImobSts_ImobUndefd" 1 "ImobSts_ImobImobn" 2 "ImobSts_ImobMtn" 3 "ImobSts_ImobNoMtn";
VAL_ 773 WhlMotClrRdyReq 0 "OnOff1_Off" 1 "OnOff1_On";
VAL_ 773 WhlMotSysCoolgReq 0 "HvCoolg1_NoRequestForMoreCoolantPower" 1 "HvCoolg1_IncreaseLevel1ForMoreCoolantPower" 2 "HvCoolg1_IncreaseLevel2ForMoreCoolantPower" 3 "HvCoolg1_MaxCoolingPower" 4 "HvCoolg1_NotDefined";
VAL_ 773 WhlMotSysErrIndcnReq 0 "OnOff1_Off" 1 "OnOff1_On";
VAL_ 613 ImobEngChk2ImobEngChkSts 0 "AvlSts2_NotAvl" 1 "AvlSts2_Avl";
VAL_ 626 IemGenericADAlrmSt 0 "AlrmSt_Disarmd" 1 "AlrmSt_Armd" 2 "AlrmSt_Actv";
VAL_ 626 IemGenericFltAlrmSt 0 "AlrmSt_Disarmd" 1 "AlrmSt_Armd" 2 "AlrmSt_Actv";
VAL_ 626 IemGenericIacAlrmSt 0 "AlrmSt_Disarmd" 1 "AlrmSt_Armd" 2 "AlrmSt_Actv";
VAL_ 626 IemGenericInvrtTAlrmSt 0 "AlrmSt_Disarmd" 1 "AlrmSt_Armd" 2 "AlrmSt_Actv";
VAL_ 626 IemGenericModStatusRms 0 "ModStatusRms_Invalid" 1 "PModStatusRms_wrCns" 2 "ModStatusRms_PwrGen" 3 "ModStatusRms_OffSts" 4 "ModStatusRms_RdySts" 5 "ModStatusRms_Abnormal" 6 "ModStatusRms_Invalid1" 7 "ModStatusRms_Invalid2" 8 "ModStatusRms_Invalid3" 9 "ModStatusRms_Invalid4" 10 "ModStatusRms_Invalid5" 11 "ModStatusRms_Invalid6" 12 "ModStatusRms_Invalid7" 13 "ModStatusRms_Invalid8" 14 "ModStatusRms_Invalid9" 15 "ModStatusRms_Invalid10";
VAL_ 626 IemGenericMotTAlrmSt 0 "AlrmSt_Disarmd" 1 "AlrmSt_Armd" 2 "AlrmSt_Actv";
VAL_ 626 IemGenericRslAlrmSt 0 "AlrmSt_Disarmd" 1 "AlrmSt_Armd" 2 "AlrmSt_Actv";
VAL_ 626 IemGenericSpdAlrmSt 0 "AlrmSt_Disarmd" 1 "AlrmSt_Armd" 2 "AlrmSt_Actv";
VAL_ 626 IemGenericUDcAlrmSt 0 "AlrmSt_Disarmd" 1 "AlrmSt_Armd" 2 "AlrmSt_Actv";
VAL_ 629 IsgClrRdyReq 0 "OnOff1_Off" 1 "OnOff1_On";
VAL_ 629 IsgCoolgReqInvr 0 "HvCoolg1_NoRequestForMoreCoolantPower" 1 "HvCoolg1_IncreaseLevel1ForMoreCoolantPower" 2 "HvCoolg1_IncreaseLevel2ForMoreCoolantPower" 3 "HvCoolg1_MaxCoolingPower" 4 "HvCoolg1_NotDefined";
VAL_ 625 ImobEngChk3ImobEngChkSts 0 "AvlSts2_NotAvl" 1 "AvlSts2_Avl";
VAL_ 625 ImobEngSts3 0 "ImobSts_ImobUndefd" 1 "ImobSts_ImobImobn" 2 "ImobSts_ImobMtn" 3 "ImobSts_ImobNoMtn";
VAL_ 149 IsgModSts 0 "IsgModTyp2_Inin" 1 "IsgModTyp2_Stb" 2 "IsgModTyp2_TqCtrl" 3 "IsgModTyp2_SpdCtrl" 4 "IsgModTyp2_UDcCtrl" 5 "IsgModTyp2_PreChrg" 6 "IsgModTyp2_PwrDwn" 7 "IsgModTyp2_Flt" 8 "IsgModTyp2_TcsCtrl";
VAL_ 149 IsgTqActQualityFactor 0 "QualityFactor_QfUndefd" 1 "QualityFactor_QfInProgs" 2 "QualityFactor_QfNotSpc" 3 "QualityFactor_QfSnsrDataOk";
VAL_ 627 IgmGenericADAlrmSt 0 "AlrmSt_Disarmd" 1 "AlrmSt_Armd" 2 "AlrmSt_Actv";
VAL_ 627 IgmGenericFltAlrmSt 0 "AlrmSt_Disarmd" 1 "AlrmSt_Armd" 2 "AlrmSt_Actv";
VAL_ 627 IgmGenericIacAlrmSt 0 "AlrmSt_Disarmd" 1 "AlrmSt_Armd" 2 "AlrmSt_Actv";
VAL_ 627 IgmGenericInvrtTAlrmSt 0 "AlrmSt_Disarmd" 1 "AlrmSt_Armd" 2 "AlrmSt_Actv";
VAL_ 627 IgmGenericModStatusRms 0 "ModStatusRms_Invalid" 1 "PModStatusRms_wrCns" 2 "ModStatusRms_PwrGen" 3 "ModStatusRms_OffSts" 4 "ModStatusRms_RdySts" 5 "ModStatusRms_Abnormal" 6 "ModStatusRms_Invalid1" 7 "ModStatusRms_Invalid2" 8 "ModStatusRms_Invalid3" 9 "ModStatusRms_Invalid4" 10 "ModStatusRms_Invalid5" 11 "ModStatusRms_Invalid6" 12 "ModStatusRms_Invalid7" 13 "ModStatusRms_Invalid8" 14 "ModStatusRms_Invalid9" 15 "ModStatusRms_Invalid10";
VAL_ 627 IgmGenericMotTAlrmSt 0 "AlrmSt_Disarmd" 1 "AlrmSt_Armd" 2 "AlrmSt_Actv";
VAL_ 627 IgmGenericRslAlrmSt 0 "AlrmSt_Disarmd" 1 "AlrmSt_Armd" 2 "AlrmSt_Actv";
VAL_ 627 IgmGenericSpdAlrmSt 0 "AlrmSt_Disarmd" 1 "AlrmSt_Armd" 2 "AlrmSt_Actv";
VAL_ 627 IgmGenericUDcAlrmSt 0 "AlrmSt_Disarmd" 1 "AlrmSt_Armd" 2 "AlrmSt_Actv";
VAL_ 660 IsgErrIndcnReq 0 "OnOff1_Off" 1 "OnOff1_On";
VAL_ 660 IsgMotCooltTFlg 0 "EngTLoFlg_ActvLoTForEng" 1 "EngTLoFlg_DeactvLoTForEng";
VAL_ 358 MvIsgModSts 0 "MvIsgModSts_Inin" 1 "MvIsgModSts_Stb" 2 "MvIsgModSts_TqCtrl" 3 "MvIsgModSts_SpdCtrl" 4 "MvIsgModSts_UDcCtrl" 5 "MvIsgModSts_Reserved1" 6 "MvIsgModSts_PwrDwn" 7 "MvIsgModSts_Reserved2" 8 "MvIsgModSts_IninFlt" 9 "MvIsgModSts_Reserved3" 10 "MvIsgModSts_Reserved4" 11 "MvIsgModSts_StrtActv" 12 "MvIsgModSts_StrtDone" 13 "MvIsgModSts_StrtIdl" 14 "MvIsgModSts_StrtFlt" 15 "MvIsgModSts_StrtOutOfRng" 16 "MvIsgModSts_StrtInhb" 17 "MvIsgModSts_Reserved5" 18 "MvIsgModSts_GenrFlt" 19 "MvIsgModSts_GenrOutOfRng" 20 "MvIsgModSts_GenrDerating" 21 "MvIsgModSts_GenrMax" 22 "MvIsgModSts_Reserved6" 23 "MvIsgModSts_SpdCtrlFlt" 24 "MvIsgModSts_SpdCtrlOutOfRng" 25 "MvIsgModSts_SpdCtrlInhb" 26 "MvIsgModSts_SpdCtrlDerating" 27 "MvIsgModSts_SpdCtrlMax" 28 "MvIsgModSts_ESAActv" 29 "MvIsgModSts_ESADone" 30 "MvIsgModSts_ESAFlt" 31 "MvIsgModSts_ESAOutOfRng" 32 "MvIsgModSts_ESAInhb" 33 "MvIsgModSts_DchrgActv" 34 "MvIsgModSts_DchrgDone" 35 "MvIsgModSts_DchrgFlt" 36 "MvIsgModSts_DchrgOutOfRng" 37 "MvIsgModSts_Reserved7" 38 "MvIsgModSts_TqCtrlIdl" 39 "MvIsgModSts_TqCtrlFlt" 40 "MvIsgModSts_TqCtrlOutOfRng" 41 "MvIsgModSts_TqCtrlInhb" 42 "MvIsgModSts_TqCtrlDetrating" 43 "MvIsgModSts_TqCtrlMax";
VAL_ 358 MvIsgRstrtSts 0 "NotActvActv1_NotActv" 1 "NotActvActv1_Actv";
VAL_ 358 MvIsgTqActQualityFactor 0 "QualityFactor_QfUndefd" 1 "QualityFactor_QfInProgs" 2 "QualityFactor_QfNotSpc" 3 "QualityFactor_QfSnsrDataOk";
VAL_ 897 MvIsgFltState1MvIsgIvtrThermProtn 0 "Flt_NoFault" 1 "Flt_Fault";
VAL_ 897 MvIsgFltState1MvIsgLoadDump 0 "Flt_NoFault" 1 "Flt_Fault";
VAL_ 897 MvIsgFltState1MvIsgNegSpdDetn 0 "Flt_NoFault" 1 "Flt_Fault";
VAL_ 897 MvIsgFltState1MvIsgOvrheatg 0 "Flt_NoFault" 1 "Flt_Fault";
VAL_ 897 MvIsgFltState1MvIsgPwrLimn 0 "Flt_NoFault" 1 "Flt_Fault";
VAL_ 897 MvIsgFltState1MvIsgStrtrModWarn 0 "Flt_NoFault" 1 "Flt_Fault";
VAL_ 897 MvIsgFltState1MvIsgULo 0 "Flt_NoFault" 1 "Flt_Fault";
VAL_ 897 MvIsgFltState1MvIsgUOvld 0 "Flt_NoFault" 1 "Flt_Fault";
VAL_ 897 MvIsgFltState2MvIsgBrushWearUDrpFlt 0 "Flt_NoFault" 1 "Flt_Fault";
VAL_ 897 MvIsgFltState2MvIsgCanFlt 0 "Flt_NoFault" 1 "Flt_Fault";
VAL_ 897 MvIsgFltState2MvIsgExctCircHiSideFlt 0 "Flt_NoFault" 1 "Flt_Fault";
VAL_ 897 MvIsgFltState2MvIsgIOvld 0 "Flt_NoFault" 1 "Flt_Fault";
VAL_ 897 MvIsgFltState2MvIsgPwrModuleIvtrFlt 0 "Flt_NoFault" 1 "Flt_Fault";
VAL_ 897 MvIsgFltState2MvIsgPwrModuleStrtrFlt 0 "Flt_NoFault" 1 "Flt_Fault";
VAL_ 897 MvIsgFltState2MvIsgRotorIOvld 0 "Flt_NoFault" 1 "Flt_Fault";
VAL_ 897 MvIsgFltState2MvIsgTqLvlFlt 0 "Flt_NoFault" 1 "Flt_Fault";
VAL_ 897 MvIsgFltState3BattUHi 0 "Flt_NoFault" 1 "Flt_Fault";
VAL_ 897 MvIsgFltState3BattULo 0 "Flt_NoFault" 1 "Flt_Fault";
VAL_ 897 MvIsgFltState3MvIsg48vVSClOc 0 "Flt_NoFault" 1 "Flt_Fault";
VAL_ 897 MvIsgFltState3MvIsgExctCircLatentFlt 0 "Flt_NoFault" 1 "Flt_Fault";
VAL_ 897 MvIsgFltState3MvIsgRotorOpenCircFlt 0 "Flt_NoFault" 1 "Flt_Fault";
VAL_ 897 MvIsgFltState3MvIsgRPSCh 0 "Flt_NoFault" 1 "Flt_Fault";
VAL_ 897 MvIsgFltState3MvIsgRPSClOc 0 "Flt_NoFault" 1 "Flt_Fault";
VAL_ 897 MvIsgFltState3MvIsgRvsSpdFlt 0 "Flt_NoFault" 1 "Flt_Fault";
VAL_ 897 MvIsgFltState4MvIsg48vVSCh 0 "Flt_NoFault" 1 "Flt_Fault";
VAL_ 897 MvIsgFltState4MvIsgECSCh 0 "Flt_NoFault" 1 "Flt_Fault";
VAL_ 897 MvIsgFltState4MvIsgECSClOc 0 "Flt_NoFault" 1 "Flt_Fault";
VAL_ 897 MvIsgFltState4MvIsgPCSCl 0 "Flt_NoFault" 1 "Flt_Fault";
VAL_ 897 MvIsgFltState4MvIsgPCSOc 0 "Flt_NoFault" 1 "Flt_Fault";
VAL_ 897 MvIsgFltState4MvIsgTECl 0 "Flt_NoFault" 1 "Flt_Fault";
VAL_ 897 MvIsgFltState4MvIsgTPCBChOc 0 "Flt_NoFault" 1 "Flt_Fault";
VAL_ 897 MvIsgFltState4MvIsgTPCBCl 0 "Flt_NoFault" 1 "Flt_Fault";
VAL_ 897 MvIsgFltState5MvIsgPMSClCh 0 "Flt_NoFault" 1 "Flt_Fault";
VAL_ 897 MvIsgFltState5MvIsgPMSOc 0 "Flt_NoFault" 1 "Flt_Fault";
VAL_ 897 MvIsgFltState5MvIsgRotorPosnTrackingLoopFlt 0 "Flt_NoFault" 1 "Flt_Fault";
VAL_ 897 MvIsgFltState5MvIsgRPSOc 0 "Flt_NoFault" 1 "Flt_Fault";
VAL_ 897 MvIsgFltState5MvIsgTEChOc 0 "Flt_NoFault" 1 "Flt_Fault";
VAL_ 408 MvBattMod 0 "MvBattMod_Sleep" 1 "MvBattMod_Initialization" 2 "MvBattMod_Standby" 3 "MvBattMod_Close" 4 "MvBattMod_Run" 5 "MvBattMod_Open" 6 "MvBattMod_EmergencyDisconnect" 7 "MvBattMod_Shutdown" 8 "MvBattMod_Reserved1" 9 "MvBattMod_SafeState" 10 "MvBattMod_Reserved2" 11 "MvBattMod_Reserved3" 12 "MvBattMod_Reserved4" 13 "MvBattMod_Reserved5" 14 "MvBattMod_Reserved6" 15 "MvBattMod_Failure";
VAL_ 106 MvBattRlyStsMvBattRlySts 0 "BattRlySts_Open" 1 "BattRlySts_Clsd" 2 "BattRlySts_StuckOpen" 3 "BattRlySts_StuckClose";
VAL_ 584 MvBattFltState1MvBattBccComFlt 0 "Err1_NoErr" 1 "Err1_Err";
VAL_ 584 MvBattFltState1MvBattBccFlt 0 "Err1_NoErr" 1 "Err1_Err";
VAL_ 584 MvBattFltState1MvBattCellOvpFlt 0 "Err1_NoErr" 1 "Err1_Err";
VAL_ 584 MvBattFltState1MvBattCellUvpFlt 0 "Err1_NoErr" 1 "Err1_Err";
VAL_ 584 MvBattFltState1MvBattComFlt 0 "Err1_NoErr" 1 "Err1_Err";
VAL_ 584 MvBattFltState1MvBattOcpFlt 0 "Err1_NoErr" 1 "Err1_Err";
VAL_ 584 MvBattFltState1MvBattOvpFlt 0 "Err1_NoErr" 1 "Err1_Err";
VAL_ 584 MvBattFltState1MvBattUvpFlt 0 "Err1_NoErr" 1 "Err1_Err";
VAL_ 584 MvBattFltState2BattUHi 0 "Err1_NoErr" 1 "Err1_Err";
VAL_ 584 MvBattFltState2BattULo 0 "Err1_NoErr" 1 "Err1_Err";
VAL_ 584 MvBattFltState2MvBattCbClsFlt 0 "Err1_NoErr" 1 "Err1_Err";
VAL_ 584 MvBattFltState2MvBattCellUSampleFlt 0 "Err1_NoErr" 1 "Err1_Err";
VAL_ 584 MvBattFltState2MvBattISampleFlt 0 "Err1_NoErr" 1 "Err1_Err";
VAL_ 584 MvBattFltState2MvBattPrecFail 0 "Err1_NoErr" 1 "Err1_Err";
VAL_ 584 MvBattFltState2MvBattTSGND 0 "Err1_NoErr" 1 "Err1_Err";
VAL_ 584 MvBattFltState2MvBattTSPWR 0 "Err1_NoErr" 1 "Err1_Err";
VAL_ 584 MvBattFltState3MvBattCVSGND 0 "Err1_NoErr" 1 "Err1_Err";
VAL_ 584 MvBattFltState3MvBattCVSOc 0 "Err1_NoErr" 1 "Err1_Err";
VAL_ 584 MvBattFltState3MvBattCVSOOR 0 "Err1_NoErr" 1 "Err1_Err";
VAL_ 584 MvBattFltState3MvBattCVSPWR 0 "Err1_NoErr" 1 "Err1_Err";
VAL_ 584 MvBattFltState3MvBattPVSGND 0 "Err1_NoErr" 1 "Err1_Err";
VAL_ 584 MvBattFltState3MvBattPVSOc 0 "Err1_NoErr" 1 "Err1_Err";
VAL_ 584 MvBattFltState3MvBattPVSPWR 0 "Err1_NoErr" 1 "Err1_Err";
VAL_ 584 MvBattFltState3MvBattTSOOR 0 "Err1_NoErr" 1 "Err1_Err";
VAL_ 584 MvBattFltState4MvBattCSGND 0 "Err1_NoErr" 1 "Err1_Err";
VAL_ 584 MvBattFltState4MvBattCSOc 0 "Err1_NoErr" 1 "Err1_Err";
VAL_ 584 MvBattFltState4MvBattCSOOR 0 "Err1_NoErr" 1 "Err1_Err";
VAL_ 584 MvBattFltState4MvBattPVSOOR 0 "Err1_NoErr" 1 "Err1_Err";
VAL_ 584 MvBattFltState4MvBattTVSGND 0 "Err1_NoErr" 1 "Err1_Err";
VAL_ 584 MvBattFltState4MvBattTVSOOR 0 "Err1_NoErr" 1 "Err1_Err";
VAL_ 584 MvBattFltState4MvBattTVSPWR 0 "Err1_NoErr" 1 "Err1_Err";
SIG_GROUP_ 1415 DftlDevCtrl 1 : DftlDevCtrl0 DftlDevCtrl1 DftlDevCtrl2 DftlDevCtrl3 DftlDevCtrl4 DftlDevCtrl5 DftlDevCtrl6 DftlDevCtrl7;
SIG_GROUP_ 310 DrvrGearShiftDirReq1 1 : DrvrGearShiftDirReq1Chks DrvrGearShiftDirReq1Cntr DrvrGearShiftDirReq1DwnDwnTipAut DrvrGearShiftDirReq1DwnTipAut DrvrGearShiftDirReq1PosnAut DrvrGearShiftDirReq1UpTipAut DrvrGearShiftDirReq1UpUpTipAut;
SIG_GROUP_ 310 DrvrGearShiftDirReq2 1 : DrvrGearShiftDirReq2Chks DrvrGearShiftDirReq2Cntr DrvrGearShiftDirReq2DwnDwnTipAut DrvrGearShiftDirReq2DwnTipAut DrvrGearShiftDirReq2PosnAut DrvrGearShiftDirReq2UpTipAut DrvrGearShiftDirReq2UpUpTipAut;
SIG_GROUP_ 309 DrvrGearShiftManReq 1 : DrvrGearShiftManReqDwnDwnTipReq DrvrGearShiftManReqDwnTipReq DrvrGearShiftManReqSteerWhlDwnReq1 DrvrGearShiftManReqSteerWhlUpReq DrvrGearShiftManReqTipReq1 DrvrGearShiftManReqUpTipReq1 DrvrGearShiftManReqUpUpTipReq;
SIG_GROUP_ 309 DrvrGearShiftParkReq 1 : DrvrGearShiftParkReq1 DrvrGearShiftParkReqChks DrvrGearShiftParkReqCntr DrvrGearShiftParkReqSts;
SIG_GROUP_ 626 IemGeneric 1 : IemGenericADAlrmSt IemGenericDTCHig IemGenericDTCLow IemGenericDTCMid IemGenericDTCSts IemGenericEMQnty IemGenericEMSeqNr IemGenericFltAlrmSt IemGenericIacAlrmSt IemGenericInvrtTAlrmSt IemGenericModStatusRms IemGenericMotTAlrmSt IemGenericResd1 IemGenericRslAlrmSt IemGenericSpdAlrmSt IemGenericUDcAlrmSt;
SIG_GROUP_ 1111 IEMTestFr1 1 : IEMTestFr1Byte0 IEMTestFr1Byte1 IEMTestFr1Byte2 IEMTestFr1Byte3 IEMTestFr1Byte4 IEMTestFr1Byte5 IEMTestFr1Byte6 IEMTestFr1Byte7;
SIG_GROUP_ 1125 IEMTestFr2 1 : IEMTestFr2Byte0 IEMTestFr2Byte1 IEMTestFr2Byte2 IEMTestFr2Byte3 IEMTestFr2Byte4 IEMTestFr2Byte5 IEMTestFr2Byte6 IEMTestFr2Byte7;
SIG_GROUP_ 1126 IEMTestFr3 1 : IEMTestFr3Byte0 IEMTestFr3Byte1 IEMTestFr3Byte2 IEMTestFr3Byte3 IEMTestFr3Byte4 IEMTestFr3Byte5 IEMTestFr3Byte6 IEMTestFr3Byte7;
SIG_GROUP_ 627 IgmGeneric 1 : IgmGenericADAlrmSt IgmGenericDTCHig IgmGenericDTCLow IgmGenericDTCMid IgmGenericDTCSts IgmGenericEMQnty IgmGenericEMSeqNr IgmGenericFltAlrmSt IgmGenericIacAlrmSt IgmGenericInvrtTAlrmSt IgmGenericModStatusRms IgmGenericMotTAlrmSt IgmGenericResd1 IgmGenericRslAlrmSt IgmGenericSpdAlrmSt IgmGenericUDcAlrmSt;
SIG_GROUP_ 1127 IGMTestFr1 1 : IGMTestFr1Byte0 IGMTestFr1Byte1 IGMTestFr1Byte2 IGMTestFr1Byte3 IGMTestFr1Byte4 IGMTestFr1Byte5 IGMTestFr1Byte6 IGMTestFr1Byte7;
SIG_GROUP_ 1129 IGMTestFr2 1 : IGMTestFr2Byte0 IGMTestFr2Byte1 IGMTestFr2Byte2 IGMTestFr2Byte3 IGMTestFr2Byte4 IGMTestFr2Byte5 IGMTestFr2Byte6 IGMTestFr2Byte7;
SIG_GROUP_ 613 ImobEngChk2 1 : ImobEngChk2ImobEngChkSts ImobEngChk2ImobEngDataChk0 ImobEngChk2ImobEngDataChk1 ImobEngChk2ImobEngDataChk2 ImobEngChk2ImobEngDataChk3 ImobEngChk2ImobEngDataChk4 ImobEngChk2ImobEngDataChk5 ImobEngChk2ImobEngDataChk6;
SIG_GROUP_ 625 ImobEngChk3 1 : ImobEngChk3ImobEngChkSts ImobEngChk3ImobEngDataChk0 ImobEngChk3ImobEngDataChk1 ImobEngChk3ImobEngDataChk2 ImobEngChk3ImobEngDataChk3 ImobEngChk3ImobEngDataChk4 ImobEngChk3ImobEngDataChk5 ImobEngChk3ImobEngDataChk6;
SIG_GROUP_ 149 IsgTqAct 1 : IsgTqActChks IsgTqActCntr IsgTqActIsgTqAct IsgTqActQualityFactor;
SIG_GROUP_ 401 IsgTqAllwd 1 : IsgTqAllwdChks IsgTqAllwdCntr IsgTqAllwdIsgTqAllwd;
SIG_GROUP_ 314 IsgTqAvl 1 : IsgTqAvlMax IsgTqAvlMin;
SIG_GROUP_ 584 MvBattFltState1 1 : MvBattFltState1MvBattBccComFlt MvBattFltState1MvBattBccFlt MvBattFltState1MvBattCellOvpFlt MvBattFltState1MvBattCellUvpFlt MvBattFltState1MvBattComFlt MvBattFltState1MvBattOcpFlt MvBattFltState1MvBattOvpFlt MvBattFltState1MvBattUvpFlt;
SIG_GROUP_ 584 MvBattFltState2 1 : MvBattFltState2BattUHi MvBattFltState2BattULo MvBattFltState2MvBattCbClsFlt MvBattFltState2MvBattCellUSampleFlt MvBattFltState2MvBattISampleFlt MvBattFltState2MvBattPrecFail MvBattFltState2MvBattTSGND MvBattFltState2MvBattTSPWR;
SIG_GROUP_ 584 MvBattFltState3 1 : MvBattFltState3MvBattCVSGND MvBattFltState3MvBattCVSOc MvBattFltState3MvBattCVSOOR MvBattFltState3MvBattCVSPWR MvBattFltState3MvBattPVSGND MvBattFltState3MvBattPVSOc MvBattFltState3MvBattPVSPWR MvBattFltState3MvBattTSOOR;
SIG_GROUP_ 584 MvBattFltState4 1 : MvBattFltState4MvBattCSGND MvBattFltState4MvBattCSOc MvBattFltState4MvBattCSOOR MvBattFltState4MvBattPVSOOR MvBattFltState4MvBattTVSGND MvBattFltState4MvBattTVSOOR MvBattFltState4MvBattTVSPWR;
SIG_GROUP_ 408 MvBattLimnIndcn 1 : MvBattLimnIndcnChks MvBattLimnIndcnCntr MvBattLimnIndcnMvBattLimnIndcn;
SIG_GROUP_ 106 MvBattRlySts 1 : MvBattRlyStsChks MvBattRlyStsCntr MvBattRlyStsMvBattRlySts;
SIG_GROUP_ 1151 MvBattT 1 : MvBattTAvg MvBattTMax MvBattTMin;
SIG_GROUP_ 1479 MVBMdevelpsignalgroupreq 1 : MVBMdevelpsignalgroupreqFunctiondevpsignalgroup1 MVBMdevelpsignalgroupreqFunctiondevpsignalgroup2 MVBMdevelpsignalgroupreqFunctiondevpsignalgroup3 MVBMdevelpsignalgroupreqFunctiondevpsignalgroup4 MVBMdevelpsignalgroupreqFunctiondevpsignalgroup5 MVBMdevelpsignalgroupreqFunctiondevpsignalgroup6 MVBMdevelpsignalgroupreqFunctiondevpsignalgroup7 MVBMdevelpsignalgroupreqFunctiondevpsignalgroup8;
SIG_GROUP_ 1478 MVBMdevelpsignalgroupresp 1 : MVBMdevelpsignalgrouprespFunctiondevpsignalgroup1 MVBMdevelpsignalgrouprespFunctiondevpsignalgroup2 MVBMdevelpsignalgrouprespFunctiondevpsignalgroup3 MVBMdevelpsignalgrouprespFunctiondevpsignalgroup4 MVBMdevelpsignalgrouprespFunctiondevpsignalgroup5 MVBMdevelpsignalgrouprespFunctiondevpsignalgroup6 MVBMdevelpsignalgrouprespFunctiondevpsignalgroup7 MVBMdevelpsignalgrouprespFunctiondevpsignalgroup8;
SIG_GROUP_ 1462 MVCMdevelpsignalgroupreq 1 : MVCMdevelpsignalgroupreqFunctiondevpsignalgroup1 MVCMdevelpsignalgroupreqFunctiondevpsignalgroup2 MVCMdevelpsignalgroupreqFunctiondevpsignalgroup3 MVCMdevelpsignalgroupreqFunctiondevpsignalgroup4 MVCMdevelpsignalgroupreqFunctiondevpsignalgroup5 MVCMdevelpsignalgroupreqFunctiondevpsignalgroup6 MVCMdevelpsignalgroupreqFunctiondevpsignalgroup7 MVCMdevelpsignalgroupreqFunctiondevpsignalgroup8;
SIG_GROUP_ 897 MvIsgFltState1 1 : MvIsgFltState1MvIsgIvtrThermProtn MvIsgFltState1MvIsgLoadDump MvIsgFltState1MvIsgNegSpdDetn MvIsgFltState1MvIsgOvrheatg MvIsgFltState1MvIsgPwrLimn MvIsgFltState1MvIsgStrtrModWarn MvIsgFltState1MvIsgULo MvIsgFltState1MvIsgUOvld;
SIG_GROUP_ 897 MvIsgFltState2 1 : MvIsgFltState2MvIsgBrushWearUDrpFlt MvIsgFltState2MvIsgCanFlt MvIsgFltState2MvIsgExctCircHiSideFlt MvIsgFltState2MvIsgIOvld MvIsgFltState2MvIsgPwrModuleIvtrFlt MvIsgFltState2MvIsgPwrModuleStrtrFlt MvIsgFltState2MvIsgRotorIOvld MvIsgFltState2MvIsgTqLvlFlt;
SIG_GROUP_ 897 MvIsgFltState3 1 : MvIsgFltState3BattUHi MvIsgFltState3BattULo MvIsgFltState3MvIsg48vVSClOc MvIsgFltState3MvIsgExctCircLatentFlt MvIsgFltState3MvIsgRotorOpenCircFlt MvIsgFltState3MvIsgRPSCh MvIsgFltState3MvIsgRPSClOc MvIsgFltState3MvIsgRvsSpdFlt;
SIG_GROUP_ 897 MvIsgFltState4 1 : MvIsgFltState4MvIsg48vVSCh MvIsgFltState4MvIsgECSCh MvIsgFltState4MvIsgECSClOc MvIsgFltState4MvIsgPCSCl MvIsgFltState4MvIsgPCSOc MvIsgFltState4MvIsgTECl MvIsgFltState4MvIsgTPCBChOc MvIsgFltState4MvIsgTPCBCl;
SIG_GROUP_ 897 MvIsgFltState5 1 : MvIsgFltState5MvIsgPMSClCh MvIsgFltState5MvIsgPMSOc MvIsgFltState5MvIsgRotorPosnTrackingLoopFlt MvIsgFltState5MvIsgRPSOc MvIsgFltState5MvIsgTEChOc;
SIG_GROUP_ 358 MvIsgTqAct 1 : MvIsgTqActMvIsgTq MvIsgTqActMvIsgTqChks MvIsgTqActMvIsgTqCntr MvIsgTqActQualityFactor;
SIG_GROUP_ 90 MvIsgTqAvl 1 : MvIsgTqAvlIsgTqAvlMax MvIsgTqAvlIsgTqAvlMin;
SIG_GROUP_ 1430 OBCdevelpsignalgroupreq 1 : OBCdevelpsignalgroupreqFunctiondevpsignalgroup1 OBCdevelpsignalgroupreqFunctiondevpsignalgroup2 OBCdevelpsignalgroupreqFunctiondevpsignalgroup3 OBCdevelpsignalgroupreqFunctiondevpsignalgroup4 OBCdevelpsignalgroupreqFunctiondevpsignalgroup5 OBCdevelpsignalgroupreqFunctiondevpsignalgroup6 OBCdevelpsignalgroupreqFunctiondevpsignalgroup7 OBCdevelpsignalgroupreqFunctiondevpsignalgroup8;
SIG_GROUP_ 1457 SRSdevelpsignalgroupRX 1 : SRSdevelpsignalgroupRXFunctiondevpsignalgroup1 SRSdevelpsignalgroupRXFunctiondevpsignalgroup2 SRSdevelpsignalgroupRXFunctiondevpsignalgroup3 SRSdevelpsignalgroupRXFunctiondevpsignalgroup4 SRSdevelpsignalgroupRXFunctiondevpsignalgroup5 SRSdevelpsignalgroupRXFunctiondevpsignalgroup6 SRSdevelpsignalgroupRXFunctiondevpsignalgroup7 SRSdevelpsignalgroupRXFunctiondevpsignalgroup8;
SIG_GROUP_ 1513 VDDMPropCANInternalDevReqMesg 1 : VDDMPropCANInternalDevReqMesgFunctiondevpsignalgroup1 VDDMPropCANInternalDevReqMesgFunctiondevpsignalgroup2 VDDMPropCANInternalDevReqMesgFunctiondevpsignalgroup3 VDDMPropCANInternalDevReqMesgFunctiondevpsignalgroup4 VDDMPropCANInternalDevReqMesgFunctiondevpsignalgroup5 VDDMPropCANInternalDevReqMesgFunctiondevpsignalgroup6 VDDMPropCANInternalDevReqMesgFunctiondevpsignalgroup7 VDDMPropCANInternalDevReqMesgFunctiondevpsignalgroup8;
SIG_GROUP_ 1347 VFCVectorECM 1 : VFCVectorECMBlockID VFCVectorECMVFCid0 VFCVectorECMVFCid1 VFCVectorECMVFCid10 VFCVectorECMVFCid11 VFCVectorECMVFCid12 VFCVectorECMVFCid13 VFCVectorECMVFCid14 VFCVectorECMVFCid15 VFCVectorECMVFCid16 VFCVectorECMVFCid17 VFCVectorECMVFCid18 VFCVectorECMVFCid19 VFCVectorECMVFCid2 VFCVectorECMVFCid20 VFCVectorECMVFCid21 VFCVectorECMVFCid22 VFCVectorECMVFCid23 VFCVectorECMVFCid24 VFCVectorECMVFCid25 VFCVectorECMVFCid26 VFCVectorECMVFCid27 VFCVectorECMVFCid28 VFCVectorECMVFCid29 VFCVectorECMVFCid3 VFCVectorECMVFCid30 VFCVectorECMVFCid31 VFCVectorECMVFCid32 VFCVectorECMVFCid33 VFCVectorECMVFCid34 VFCVectorECMVFCid35 VFCVectorECMVFCid36 VFCVectorECMVFCid37 VFCVectorECMVFCid38 VFCVectorECMVFCid39 VFCVectorECMVFCid4 VFCVectorECMVFCid40 VFCVectorECMVFCid41 VFCVectorECMVFCid42 VFCVectorECMVFCid43 VFCVectorECMVFCid44 VFCVectorECMVFCid45 VFCVectorECMVFCid46 VFCVectorECMVFCid47 VFCVectorECMVFCid48 VFCVectorECMVFCid49 VFCVectorECMVFCid5 VFCVectorECMVFCid50 VFCVectorECMVFCid51 VFCVectorECMVFCid52 VFCVectorECMVFCid53 VFCVectorECMVFCid54 VFCVectorECMVFCid55 VFCVectorECMVFCid56 VFCVectorECMVFCid57 VFCVectorECMVFCid58 VFCVectorECMVFCid59 VFCVectorECMVFCid6 VFCVectorECMVFCid60 VFCVectorECMVFCid61 VFCVectorECMVFCid7 VFCVectorECMVFCid8 VFCVectorECMVFCid9;
SIG_GROUP_ 1349 VFCVectorEGSM 1 : VFCVectorEGSMBlockID VFCVectorEGSMVFCid0 VFCVectorEGSMVFCid1 VFCVectorEGSMVFCid10 VFCVectorEGSMVFCid11 VFCVectorEGSMVFCid12 VFCVectorEGSMVFCid13 VFCVectorEGSMVFCid14 VFCVectorEGSMVFCid15 VFCVectorEGSMVFCid16 VFCVectorEGSMVFCid17 VFCVectorEGSMVFCid18 VFCVectorEGSMVFCid19 VFCVectorEGSMVFCid2 VFCVectorEGSMVFCid20 VFCVectorEGSMVFCid21 VFCVectorEGSMVFCid22 VFCVectorEGSMVFCid23 VFCVectorEGSMVFCid24 VFCVectorEGSMVFCid25 VFCVectorEGSMVFCid26 VFCVectorEGSMVFCid27 VFCVectorEGSMVFCid28 VFCVectorEGSMVFCid29 VFCVectorEGSMVFCid3 VFCVectorEGSMVFCid30 VFCVectorEGSMVFCid31 VFCVectorEGSMVFCid32 VFCVectorEGSMVFCid33 VFCVectorEGSMVFCid34 VFCVectorEGSMVFCid35 VFCVectorEGSMVFCid36 VFCVectorEGSMVFCid37 VFCVectorEGSMVFCid38 VFCVectorEGSMVFCid39 VFCVectorEGSMVFCid4 VFCVectorEGSMVFCid40 VFCVectorEGSMVFCid41 VFCVectorEGSMVFCid42 VFCVectorEGSMVFCid43 VFCVectorEGSMVFCid44 VFCVectorEGSMVFCid45 VFCVectorEGSMVFCid46 VFCVectorEGSMVFCid47 VFCVectorEGSMVFCid48 VFCVectorEGSMVFCid49 VFCVectorEGSMVFCid5 VFCVectorEGSMVFCid50 VFCVectorEGSMVFCid51 VFCVectorEGSMVFCid52 VFCVectorEGSMVFCid53 VFCVectorEGSMVFCid54 VFCVectorEGSMVFCid55 VFCVectorEGSMVFCid56 VFCVectorEGSMVFCid57 VFCVectorEGSMVFCid58 VFCVectorEGSMVFCid59 VFCVectorEGSMVFCid6 VFCVectorEGSMVFCid60 VFCVectorEGSMVFCid61 VFCVectorEGSMVFCid7 VFCVectorEGSMVFCid8 VFCVectorEGSMVFCid9;
SIG_GROUP_ 76 WhlMotSysTqAvl 1 : WhlMotSysTqAvlTqAvlMax WhlMotSysTqAvlTqAvlMin;
SIG_GROUP_ 76 WhlMotSysTqEst 1 : WhlMotSysTqEstChks WhlMotSysTqEstCntr WhlMotSysTqEstIsgTqAct WhlMotSysTqEstQualityFactor;
